VERSION "dbc-export 1 2026.26.6.5"

NS_ :

BS_:

BU_: ADSP APB APP APS APSB BB BMS CC CMP CMPD CP DAS DI DIF DIR DPB EPAS3P EPAS3S EPASTP EPASTS EPBL EPBR ESP EVSE FC GTW HCML HCMR HVP IBST ICR IDB LS OCS1P PARK PCS PCS2 PM PMF PMR PNCD PTC RADC RCM RCM2 RCM3 RCU SCCM SCM SCS SDCR TAS TCU TCU2 TPMS TRCM UI UIS UMC USM V2G VC VCBATT VCBATT0 VCBATT1 VCBATT2 VCCC VCFRONT VCFRONT1 VCFRONT2 VCLEFT VCRIGHT VCSEAT2L VCSEAT2R VCSEC VEH

BO_ 1360 ADSP_alertLog: 8 ADSP
 SG_ ADSP_alertID M : 0|7@1+ (1,0) [0|127] "" Vector__XXX
 SG_ ADSP_alertState : 15|1@1+ (1,0) [0|1] "" Vector__XXX
 SG_ ADSP_a002_core m2 : 16|2@1+ (1,0) [0|3] "" Vector__XXX
 SG_ ADSP_a002_cause m2 : 18|4@1+ (1,0) [0|15] "" Vector__XXX
 SG_ ADSP_a022_error m22 : 16|3@1+ (1,0) [0|7] "" Vector__XXX
 SG_ ADSP_a022_errorCount m22 : 24|32@1+ (1,0) [0|4294967295] "" Vector__XXX
 SG_ ADSP_a035_a2baFaultNode m35 : 16|4@1+ (1,0) [0|15] "" Vector__XXX
 SG_ ADSP_a035_timeout m35 : 20|1@1+ (1,0) [0|1] "" Vector__XXX
 SG_ ADSP_a035_a2baIntrType m35 : 24|8@1+ (1,0) [0|255] "" Vector__XXX
 SG_ ADSP_a035_a2baFaultType m35 : 32|6@1+ (1,0) [0|63] "" Vector__XXX
 SG_ ADSP_a036_a2bbFaultNode m36 : 16|4@1+ (1,0) [0|15] "" Vector__XXX
 SG_ ADSP_a036_timeout m36 : 20|1@1+ (1,0) [0|1] "" Vector__XXX
 SG_ ADSP_a036_a2bbIntrType m36 : 24|8@1+ (1,0) [0|255] "" Vector__XXX
 SG_ ADSP_a036_a2bbFaultType m36 : 32|6@1+ (1,0) [0|63] "" Vector__XXX
 SG_ ADSP_a050_open_load m50 : 16|1@1+ (1,0) [0|1] "" Vector__XXX
 SG_ ADSP_a050_short_vcc m50 : 17|1@1+ (1,0) [0|1] "" Vector__XXX
 SG_ ADSP_a050_short_gnd m50 : 18|1@1+ (1,0) [0|1] "" Vector__XXX
 SG_ ADSP_a050_short_load m50 : 19|1@1+ (1,0) [0|1] "" Vector__XXX
 SG_ ADSP_a050_diag_failed_to_start m50 : 20|1@1+ (1,0) [0|1] "" Vector__XXX
 SG_ ADSP_a050_diag_failed m50 : 21|1@1+ (1,0) [0|1] "" Vector__XXX
 SG_ ADSP_a053_audioSystemUnavailable m53 : 16|3@1+ (1,0) [0|7] "" Vector__XXX
 SG_ ADSP_a066_open_load m66 : 16|1@1+ (1,0) [0|1] "" Vector__XXX
 SG_ ADSP_a066_short_vcc m66 : 17|1@1+ (1,0) [0|1] "" Vector__XXX
 SG_ ADSP_a066_short_gnd m66 : 18|1@1+ (1,0) [0|1] "" Vector__XXX
 SG_ ADSP_a066_short_load m66 : 19|1@1+ (1,0) [0|1] "" Vector__XXX
 SG_ ADSP_a066_diag_failed_to_start m66 : 20|1@1+ (1,0) [0|1] "" Vector__XXX
 SG_ ADSP_a066_diag_failed m66 : 21|1@1+ (1,0) [0|1] "" Vector__XXX
 SG_ ADSP_a067_baseamp0Fault m67 : 16|3@1+ (1,0) [0|7] "" Vector__XXX
 SG_ ADSP_a067_baseamp0Temp m67 : 24|8@1+ (1,0) [0|255] "C" Vector__XXX
 SG_ ADSP_a068_baseamp1Fault m68 : 16|3@1+ (1,0) [0|7] "" Vector__XXX
 SG_ ADSP_a068_baseamp1Temp m68 : 24|8@1+ (1,0) [0|255] "C" Vector__XXX
 SG_ ADSP_a069_baseamp2Fault m69 : 16|3@1+ (1,0) [0|7] "" Vector__XXX
 SG_ ADSP_a069_baseamp2Temp m69 : 24|8@1+ (1,0) [0|255] "C" Vector__XXX
 SG_ ADSP_a070_baseamp3Fault m70 : 16|3@1+ (1,0) [0|7] "" Vector__XXX
 SG_ ADSP_a070_baseamp3Temp m70 : 24|8@1+ (1,0) [0|255] "C" Vector__XXX
 SG_ ADSP_a071_versionMismatch m71 : 16|1@1+ (1,0) [0|1] "" Vector__XXX
 SG_ ADSP_a080_micInitError m80 : 16|2@1+ (1,0) [0|3] "" Vector__XXX

BO_ 1361 ADSP_alertMatrix1: 8 ADSP
 SG_ ADSP_w001_flashInit : 0|1@1+ (1,0) [0|1] "" Vector__XXX
 SG_ ADSP_w002_exception : 1|1@1+ (1,0) [0|1] "" Vector__XXX
 SG_ ADSP_w003_assert : 2|1@1+ (1,0) [0|1] "" Vector__XXX
 SG_ ADSP_w004_malloc : 3|1@1+ (1,0) [0|1] "" Vector__XXX
 SG_ ADSP_w005_stackOverflow : 4|1@1+ (1,0) [0|1] "" Vector__XXX
 SG_ ADSP_w006_eavbSeqno : 5|1@1+ (1,0) [0|1] "" Vector__XXX
 SG_ ADSP_w007_ethLinkErr : 6|1@1+ (1,0) [0|1] "" Vector__XXX
 SG_ ADSP_w008_internalTempHigh : 7|1@1+ (1,0) [0|1] "" Vector__XXX
 SG_ ADSP_w010_12vAudioFiltLow : 9|1@1+ (1,0) [0|1] "" Vector__XXX
 SG_ ADSP_w011_armHighCpuUsage : 10|1@1+ (1,0) [0|1] "" Vector__XXX
 SG_ ADSP_w012_sharc0HighCpuUsage : 11|1@1+ (1,0) [0|1] "" Vector__XXX
 SG_ ADSP_w013_sharc1HighCpuUsage : 12|1@1+ (1,0) [0|1] "" Vector__XXX
 SG_ ADSP_w014_eavbOverrun : 13|1@1+ (1,0) [0|1] "" Vector__XXX
 SG_ ADSP_w015_eavbUnderrun : 14|1@1+ (1,0) [0|1] "" Vector__XXX
 SG_ ADSP_w016_usbRxOverrun : 15|1@1+ (1,0) [0|1] "" Vector__XXX
 SG_ ADSP_w017_usbRxUnderrun : 16|1@1+ (1,0) [0|1] "" Vector__XXX
 SG_ ADSP_w018_usbTxOverrun : 17|1@1+ (1,0) [0|1] "" Vector__XXX
 SG_ ADSP_w019_usbTxUnderrun : 18|1@1+ (1,0) [0|1] "" Vector__XXX
 SG_ ADSP_w020_usbTxFailed : 19|1@1+ (1,0) [0|1] "" Vector__XXX
 SG_ ADSP_w021_usbTxAborted : 20|1@1+ (1,0) [0|1] "" Vector__XXX
 SG_ ADSP_w022_emacErr : 21|1@1+ (1,0) [0|1] "" Vector__XXX
 SG_ ADSP_w023_ethEtharpErr : 22|1@1+ (1,0) [0|1] "" Vector__XXX
 SG_ ADSP_w024_ethIpfragErr : 23|1@1+ (1,0) [0|1] "" Vector__XXX
 SG_ ADSP_w025_ethIpErr : 24|1@1+ (1,0) [0|1] "" Vector__XXX
 SG_ ADSP_w026_ethIcmpErr : 25|1@1+ (1,0) [0|1] "" Vector__XXX
 SG_ ADSP_w027_ethUdpErr : 26|1@1+ (1,0) [0|1] "" Vector__XXX
 SG_ ADSP_w028_ethTcpErr : 27|1@1+ (1,0) [0|1] "" Vector__XXX
 SG_ ADSP_w029_baseamp0SmFault : 28|1@1+ (1,0) [0|1] "" Vector__XXX
 SG_ ADSP_w030_ethSysErr : 29|1@1+ (1,0) [0|1] "" Vector__XXX
 SG_ ADSP_w031_baseamp1SmFault : 30|1@1+ (1,0) [0|1] "" Vector__XXX
 SG_ ADSP_w032_baseamp2SmFault : 31|1@1+ (1,0) [0|1] "" Vector__XXX
 SG_ ADSP_w033_a2baDiscoveryFailed : 32|1@1+ (1,0) [0|1] "" Vector__XXX
 SG_ ADSP_w034_a2bbDiscoveryFailed : 33|1@1+ (1,0) [0|1] "" Vector__XXX
 SG_ ADSP_w035_a2baFault : 34|1@1+ (1,0) [0|1] "" Vector__XXX
 SG_ ADSP_w036_a2bbFault : 35|1@1+ (1,0) [0|1] "" Vector__XXX
 SG_ ADSP_w037_a2baIdleFailed : 36|1@1+ (1,0) [0|1] "" Vector__XXX
 SG_ ADSP_w038_a2bbIdleFailed : 37|1@1+ (1,0) [0|1] "" Vector__XXX
 SG_ ADSP_w039_ancPing : 38|1@1+ (1,0) [0|1] "" Vector__XXX
 SG_ ADSP_w040_socSciHeartbeat : 39|1@1+ (1,0) [0|1] "" Vector__XXX
 SG_ ADSP_w041_twiWriteError : 40|1@1+ (1,0) [0|1] "" Vector__XXX
 SG_ ADSP_w042_twiReadError : 41|1@1+ (1,0) [0|1] "" Vector__XXX
 SG_ ADSP_w043_aweControlError : 42|1@1+ (1,0) [0|1] "" Vector__XXX
 SG_ ADSP_w044_canethChecksum : 43|1@1+ (1,0) [0|1] "" Vector__XXX
 SG_ ADSP_w045_ancEnableFail : 44|1@1+ (1,0) [0|1] "" Vector__XXX
 SG_ ADSP_w046_sharc0AweFrameOverload : 45|1@1+ (1,0) [0|1] "" Vector__XXX
 SG_ ADSP_w047_sharc1AweFrameOverload : 46|1@1+ (1,0) [0|1] "" Vector__XXX
 SG_ ADSP_w048_eCallSelfTestFailed : 47|1@1+ (1,0) [0|1] "" Vector__XXX
 SG_ ADSP_w049_sae : 48|1@1+ (1,0) [0|1] "" Vector__XXX
 SG_ ADSP_w050_extSpkFault : 49|1@1+ (1,0) [0|1] "" Vector__XXX
 SG_ ADSP_w051_extspkFailure : 50|1@1+ (1,0) [0|1] "" Vector__XXX
 SG_ ADSP_w052_criticalReset : 51|1@1+ (1,0) [0|1] "" Vector__XXX
 SG_ ADSP_w053_audioSystemUnavailable : 52|1@1+ (1,0) [0|1] "" Vector__XXX
 SG_ ADSP_w054_canethRxError : 53|1@1+ (1,0) [0|1] "" Vector__XXX
 SG_ ADSP_w055_hfpMathExcept1NAN : 54|1@1+ (1,0) [0|1] "" Vector__XXX
 SG_ ADSP_w056_hfpMathExcept1INF : 55|1@1+ (1,0) [0|1] "" Vector__XXX
 SG_ ADSP_w057_hfpMathExcept2NAN : 56|1@1+ (1,0) [0|1] "" Vector__XXX
 SG_ ADSP_w058_hfpMathExcept2INF : 57|1@1+ (1,0) [0|1] "" Vector__XXX
 SG_ ADSP_w059_nvmmError : 58|1@1+ (1,0) [0|1] "" Vector__XXX
 SG_ ADSP_w060_baseamp3SmFault : 59|1@1+ (1,0) [0|1] "" Vector__XXX
 SG_ ADSP_w061_tcuGpioServiceError : 60|1@1+ (1,0) [0|1] "" Vector__XXX

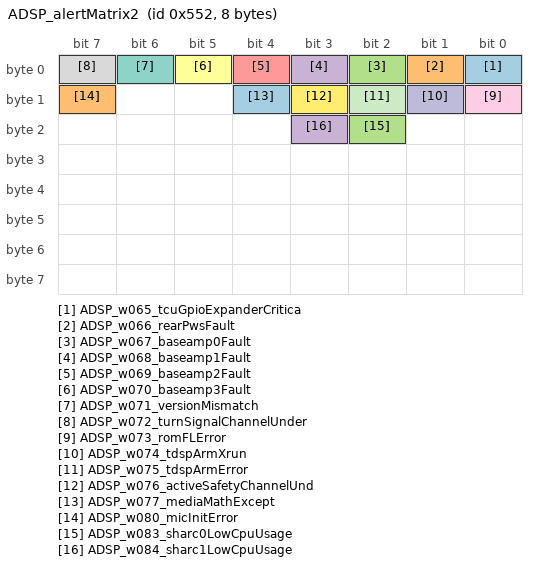
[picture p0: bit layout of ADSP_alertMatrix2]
BO_ 1362 ADSP_alertMatrix2: 8 ADSP
 SG_ ADSP_w065_tcuGpioExpanderCritica : 0|1@1+ (1,0) [0|1] "" Vector__XXX
 SG_ ADSP_w066_rearPwsFault : 1|1@1+ (1,0) [0|1] "" Vector__XXX
 SG_ ADSP_w067_baseamp0Fault : 2|1@1+ (1,0) [0|1] "" Vector__XXX
 SG_ ADSP_w068_baseamp1Fault : 3|1@1+ (1,0) [0|1] "" Vector__XXX
 SG_ ADSP_w069_baseamp2Fault : 4|1@1+ (1,0) [0|1] "" Vector__XXX
 SG_ ADSP_w070_baseamp3Fault : 5|1@1+ (1,0) [0|1] "" Vector__XXX
 SG_ ADSP_w071_versionMismatch : 6|1@1+ (1,0) [0|1] "" Vector__XXX
 SG_ ADSP_w072_turnSignalChannelUnder : 7|1@1+ (1,0) [0|1] "" Vector__XXX
 SG_ ADSP_w073_romFLError : 8|1@1+ (1,0) [0|1] "" Vector__XXX
 SG_ ADSP_w074_tdspArmXrun : 9|1@1+ (1,0) [0|1] "" Vector__XXX
 SG_ ADSP_w075_tdspArmError : 10|1@1+ (1,0) [0|1] "" Vector__XXX
 SG_ ADSP_w076_activeSafetyChannelUnd : 11|1@1+ (1,0) [0|1] "" Vector__XXX
 SG_ ADSP_w077_mediaMathExcept : 12|1@1+ (1,0) [0|1] "" Vector__XXX
 SG_ ADSP_w080_micInitError : 15|1@1+ (1,0) [0|1] "" Vector__XXX
 SG_ ADSP_w083_sharc0LowCpuUsage : 18|1@1+ (1,0) [0|1] "" Vector__XXX
 SG_ ADSP_w084_sharc1LowCpuUsage : 19|1@1+ (1,0) [0|1] "" Vector__XXX

BO_ 1951 ADSP_audioVisualizer: 1 ADSP
 SG_ ADSP_audioVisualizerBrightness : 0|8@1+ (1,0) [0|255] "" Vector__XXX

BO_ 1383 ADSP_state: 8 ADSP
 SG_ ADSP_a2baState : 0|5@1+ (1,0) [0|31] "" Vector__XXX
 SG_ ADSP_a2bbState : 8|5@1+ (1,0) [0|31] "" Vector__XXX
 SG_ ADSP_baseamp0State : 13|3@1+ (1,0) [0|7] "" Vector__XXX
 SG_ ADSP_baseamp1State : 16|3@1+ (1,0) [0|7] "" Vector__XXX
 SG_ ADSP_baseamp2State : 19|3@1+ (1,0) [0|7] "" Vector__XXX
 SG_ ADSP_baseamp3State : 24|3@1+ (1,0) [0|7] "" Vector__XXX
 SG_ ADSP_audioReady : 27|1@1+ (1,0) [0|1] "" Vector__XXX
 SG_ ADSP_extSpkCheckRan : 28|1@1+ (1,0) [0|1] "" Vector__XXX
 SG_ ADSP_tcuI2SEnabled : 29|1@1+ (1,0) [0|1] "" Vector__XXX
 SG_ ADSP_telephonyRxMute : 31|1@1+ (1,0) [0|1] "" Vector__XXX
 SG_ ADSP_ancState : 32|3@1+ (1,0) [0|7] "" Vector__XXX
 SG_ ADSP_sourceSelect : 35|2@1+ (1,0) [0|3] "" Vector__XXX
 SG_ ADSP_tunerSelect : 37|1@1+ (1,0) [0|1] "" Vector__XXX
 SG_ ADSP_ancMode : 38|5@1+ (1,0) [0|31] "" Vector__XXX
 SG_ ADSP_spkMuteAll : 43|1@1+ (1,0) [0|1] "" Vector__XXX
 SG_ ADSP_eCall_ENS_state : 44|3@1+ (1,0) [0|7] "" Vector__XXX
 SG_ ADSP_eCallSelfTest : 47|2@1+ (1,0) [0|3] "" Vector__XXX
 SG_ ADSP_eCallState : 49|1@1+ (1,0) [0|1] "" Vector__XXX
 SG_ ADSP_allAudioReady : 50|1@1+ (1,0) [0|1] "" Vector__XXX
 SG_ ADSP_callState : 51|1@1+ (1,0) [0|1] "" Vector__XXX
 SG_ ADSP_telephonyTxMute : 52|1@1+ (1,0) [0|1] "" Vector__XXX
 SG_ ADSP_eCallMicrophoneStatus : 53|2@1+ (1,0) [0|3] "" Vector__XXX
 SG_ ADSP_eCallSpeakerStatus : 56|2@1+ (1,0) [0|3] "" Vector__XXX
 SG_ ADSP_a2baLoadShedded : 58|1@1+ (1,0) [0|1] "" Vector__XXX
 SG_ ADSP_requestFailoverSpeaker : 59|1@1+ (1,0) [0|1] "" Vector__XXX
 SG_ ADSP_microphoneDataState : 60|1@1+ (1,0) [0|1] "" Vector__XXX

BO_ 600 APB_status: 8 APB
 SG_ APB_watchdogState : 0|3@1+ (1,0) [0|6] "" Vector__XXX
 SG_ APB_fusedState : 3|2@1+ (1,0) [0|2] "" Vector__XXX
 SG_ APB_cameraHeaterRequest : 5|1@1+ (1,0) [0|1] "" Vector__XXX
 SG_ APB_factorySummonStatus : 6|4@1+ (1,0) [1|15] "" Vector__XXX
 SG_ APB_clipRecordingStatus : 10|3@1+ (1,0) [0|7] "" Vector__XXX
 SG_ APB_summonUnavailableReason : 14|5@1+ (1,0) [0|31] "" Vector__XXX
 SG_ APB_fsdSuspendState : 19|2@1+ (1,0) [0|2] "" Vector__XXX
 SG_ APB_fsdRevokeStrikeoutCount : 21|3@1+ (1,0) [0|6] "" Vector__XXX
 SG_ APB_teslaVisionSupported : 24|2@1+ (1,0) [0|2] "" Vector__XXX
 SG_ APB_teslaVisionUnsupportedReason : 26|3@1+ (1,0) [0|7] "" Vector__XXX
 SG_ APB_fsdRevokeCount : 29|3@1+ (1,0) [0|6] "" Vector__XXX
 SG_ APB_excessiveAccelPedalWarning : 32|1@1+ (1,0) [0|1] "" Vector__XXX
 SG_ APB_unifiedObjectStackSupported : 33|2@1+ (1,0) [0|2] "" Vector__XXX
 SG_ APB_sendingBUCStream : 35|1@1+ (1,0) [0|1] "" Vector__XXX
 SG_ APB_DDAWSystemStatus : 37|3@1+ (1,0) [0|7] "" Vector__XXX
 SG_ APB_socOperatingMode : 40|2@1+ (1,0) [0|3] "" Vector__XXX
 SG_ APB_summonVersionIdentifier : 42|2@1+ (1,0) [0|3] "" Vector__XXX
 SG_ APB_sentryState : 44|3@1+ (1,0) [0|7] "" Vector__XXX
 SG_ APB_autoparkVersionIdentifier : 47|2@1+ (1,0) [0|3] "" Vector__XXX
 SG_ APB_autonomySystemHealth : 49|1@1+ (1,0) [0|1] "" Vector__XXX
 SG_ APB_suspendResumeAvailable : 51|1@1+ (1,0) [0|1] "" Vector__XXX
 SG_ APB_statusCounter : 52|4@1+ (1,0) [0|15] "" Vector__XXX
 SG_ APB_statusChecksum : 56|8@1+ (1,0) [0|255] "" Vector__XXX

BO_ 909 APP_VC_infoMessage: 8 APP
 SG_ APP_inTunnel : 0|2@1+ (1,0) [1|3] "" Vector__XXX
 SG_ APP_windshieldHeaterOnReason : 2|4@1+ (1,0) [1|15] "" Vector__XXX
 SG_ APP_selfieCameraBlocked : 6|2@1+ (1,0) [1|3] "" Vector__XXX
 SG_ APP_selfieCameraLUX : 8|8@1+ (1,0) [0|253] "lux" Vector__XXX
 SG_ APP_sceneTagClearlyRaining : 16|2@1+ (1,0) [1|3] "" Vector__XXX
 SG_ APP_sceneTagFog : 18|2@1+ (1,0) [1|3] "" Vector__XXX
 SG_ APP_sceneTagFullyBlocked : 20|2@1+ (1,0) [1|3] "" Vector__XXX
 SG_ APP_sceneTagIndoors : 22|2@1+ (1,0) [1|3] "" Vector__XXX
 SG_ APP_sceneTagLensFlare : 24|2@1+ (1,0) [1|3] "" Vector__XXX
 SG_ APP_sceneTagRaining : 26|2@1+ (1,0) [1|3] "" Vector__XXX
 SG_ APP_sceneTagSevereWeather : 28|2@1+ (1,0) [1|3] "" Vector__XXX
 SG_ APP_sceneTagSnowing : 30|2@1+ (1,0) [1|3] "" Vector__XXX
 SG_ APP_sceneTagSnowyRoad : 32|2@1+ (1,0) [1|3] "" Vector__XXX
 SG_ APP_sceneTagSunGlare : 34|2@1+ (1,0) [1|3] "" Vector__XXX
 SG_ APP_sceneTagTunnel : 36|2@1+ (1,0) [1|3] "" Vector__XXX
 SG_ APP_sceneTagWetRoad : 38|2@1+ (1,0) [1|3] "" Vector__XXX
 SG_ APP_fisheyeInPathVisibility : 40|3@1+ (1,0) [1|7] "" Vector__XXX
 SG_ APP_fisheyeOverallVisibility : 43|3@1+ (1,0) [1|7] "" Vector__XXX
 SG_ APP_mainInPathVisibility : 46|3@1+ (1,0) [1|7] "" Vector__XXX
 SG_ APP_mainOverallVisibility : 49|3@1+ (1,0) [1|7] "" Vector__XXX
 SG_ APP_narrowInPathVisibility : 52|3@1+ (1,0) [1|7] "" Vector__XXX
 SG_ APP_narrowOverallVisibility : 55|3@1+ (1,0) [1|7] "" Vector__XXX
 SG_ APP_frontCamOcclusionType : 58|3@1+ (1,0) [0|7] "" Vector__XXX

BO_ 1513 APP_alertLog: 8 APP
 SG_ APP_alertID M : 0|14@1+ (1,0) [0|16383] "" Vector__XXX
 SG_ APP_alertSource : 14|1@1+ (1,0) [0|1] "" Vector__XXX
 SG_ APP_alertState : 15|1@1+ (1,0) [0|1] "" Vector__XXX
 SG_ APP_sw004_radIssue m4 : 16|1@1+ (1,0) [0|1] "" Vector__XXX
 SG_ APP_sw004_radHWFailure m4 : 17|1@1+ (1,0) [0|1] "" Vector__XXX
 SG_ APP_sw004_radSensorBlind m4 : 18|1@1+ (1,0) [0|1] "" Vector__XXX
 SG_ APP_sw004_radSGUFailure m4 : 19|1@1+ (1,0) [0|1] "" Vector__XXX
 SG_ APP_sw004_radMia m4 : 20|1@1+ (1,0) [0|1] "" Vector__XXX
 SG_ APP_sw004_radDynamicsError m4 : 21|1@1+ (1,0) [0|1] "" Vector__XXX
 SG_ APP_sw004_espMIA m4 : 22|1@1+ (1,0) [0|1] "" Vector__XXX
 SG_ APP_sw004_accState m4 : 24|4@1+ (1,0) [0|15] "" Vector__XXX
 SG_ APP_sw004_appMobileyeStatus m4 : 28|5@1+ (1,0) [0|31] "" Vector__XXX
 SG_ APP_sw004_diCruiseStateFault m4 : 33|1@1+ (1,0) [0|1] "" Vector__XXX
 SG_ APP_sw004_diMIA m4 : 34|1@1+ (1,0) [0|1] "" Vector__XXX
 SG_ APP_sw004_accelPedalInvalid m4 : 35|1@1+ (1,0) [0|1] "" Vector__XXX
 SG_ APP_sw004_stwAngleInvalid m4 : 36|1@1+ (1,0) [0|1] "" Vector__XXX
 SG_ APP_sw004_accelerationInvalid m4 : 37|1@1+ (1,0) [0|1] "" Vector__XXX
 SG_ APP_sw004_diSpeedInvalid m4 : 38|1@1+ (1,0) [0|1] "" Vector__XXX
 SG_ APP_sw004_DASFeaturesDisabled m4 : 39|1@1+ (1,0) [0|1] "" Vector__XXX
 SG_ APP_sw004_appMobileyeNotInVision m4 : 40|1@1+ (1,0) [0|1] "" Vector__XXX
 SG_ APP_sw004_CamCommonMIA m4 : 41|1@1+ (1,0) [0|1] "" Vector__XXX
 SG_ APP_sw004_CamObjectsMIA m4 : 42|1@1+ (1,0) [0|1] "" Vector__XXX
 SG_ APP_sw004_CamWatchdog m4 : 43|1@1+ (1,0) [0|1] "" Vector__XXX
 SG_ APP_sw004_RadarLowVisibility m4 : 44|1@1+ (1,0) [0|1] "" Vector__XXX
 SG_ APP_sw004_RadarMisalignment m4 : 45|1@1+ (1,0) [0|1] "" Vector__XXX
 SG_ APP_sw004_OutOfFocusImage m4 : 46|1@1+ (1,0) [0|1] "" Vector__XXX
 SG_ APP_sw004_ImpairedVD m4 : 47|1@1+ (1,0) [0|1] "" Vector__XXX
 SG_ APP_sw004_SunRay m4 : 48|1@1+ (1,0) [0|1] "" Vector__XXX
 SG_ APP_sw004_Splashes m4 : 49|1@1+ (1,0) [0|1] "" Vector__XXX
 SG_ APP_sw004_BlurredImage m4 : 50|1@1+ (1,0) [0|1] "" Vector__XXX
 SG_ APP_sw004_LowSun m4 : 51|1@1+ (1,0) [0|1] "" Vector__XXX
 SG_ APP_sw004_SmearedSpots m4 : 52|1@1+ (1,0) [0|1] "" Vector__XXX
 SG_ APP_sw004_PartialBlockage m4 : 53|1@1+ (1,0) [0|1] "" Vector__XXX
 SG_ APP_sw004_AutofixOutOfCalib m4 : 54|1@1+ (1,0) [0|1] "" Vector__XXX
 SG_ APP_sw004_AutofixOutOfCalibHorzn m4 : 55|1@1+ (1,0) [0|1] "" Vector__XXX
 SG_ APP_sw004_AutofixOutOfCalibYaw m4 : 56|1@1+ (1,0) [0|1] "" Vector__XXX
 SG_ APP_sw004_FullBlockage m4 : 57|1@1+ (1,0) [0|1] "" Vector__XXX
 SG_ APP_sw004_SmearedHalos m4 : 58|1@1+ (1,0) [0|1] "" Vector__XXX
 SG_ APP_sw004_FoggyLights m4 : 59|1@1+ (1,0) [0|1] "" Vector__XXX
 SG_ APP_sw004_SelfGlare m4 : 60|1@1+ (1,0) [0|1] "" Vector__XXX
 SG_ APP_sw004_visionNotRunning m4 : 61|1@1+ (1,0) [0|1] "" Vector__XXX
 SG_ APP_sw009_DIaebState_fault m9 : 16|1@1+ (1,0) [0|1] "" Vector__XXX
 SG_ APP_sw009_DI_aeb_unresponsive m9 : 17|1@1+ (1,0) [0|1] "" Vector__XXX
 SG_ APP_sw009_DI_MIA m9 : 18|1@1+ (1,0) [0|1] "" Vector__XXX
 SG_ APP_sw009_SCCM_MIA m9 : 19|1@1+ (1,0) [0|1] "" Vector__XXX
 SG_ APP_sw009_CameraStream_fault m9 : 20|1@1+ (1,0) [0|1] "" Vector__XXX
 SG_ APP_sw010_a04calibNotDone m10 : 16|1@1+ (1,0) [0|1] "" Vector__XXX
 SG_ APP_sw010_a05calibReqd m10 : 17|1@1+ (1,0) [0|1] "" Vector__XXX
 SG_ APP_sw010_a06calibNotOK m10 : 18|1@1+ (1,0) [0|1] "" Vector__XXX
 SG_ APP_sw010_a08PlantMode m10 : 19|1@1+ (1,0) [0|1] "" Vector__XXX
 SG_ APP_sw010_HorizontalMisalignment m10 : 20|16@1+ (0.00137332,-45) [-45|45.0005262] "deg" Vector__XXX
 SG_ APP_sw010_VerticalMisalignment m10 : 36|10@1+ (0.087977,-45) [-45|45.000471] "deg" Vector__XXX
 SG_ APP_sw010_unusedBits m10 : 46|2@1+ (1,0) [0|3] "" Vector__XXX
 SG_ APP_sw010_VmaPlausibility m10 : 48|16@1+ (1.52587890625e-05,0) [0|0.999984741211] "FIXME" Vector__XXX
 SG_ APP_sw011_scaState m11 : 16|3@1+ (1,0) [0|7] "" Vector__XXX
 SG_ APP_sw011_scaLeft m11 : 19|1@1+ (1,0) [0|1] "" Vector__XXX
 SG_ APP_sw011_scaRight m11 : 20|1@1+ (1,0) [0|1] "" Vector__XXX
 SG_ APP_sw011_scaBlinker m11 : 21|2@1+ (1,0) [0|3] "" Vector__XXX
 SG_ APP_sw011_scaThreshold m11 : 23|1@1+ (1,0) [0|1] "" Vector__XXX
 SG_ APP_sw011_scaSpeed m11 : 24|7@1+ (1,0) [0|127] "MPH" Vector__XXX
 SG_ APP_sw011_scaSonicDist m11 : 32|5@1+ (0.05,0) [0|1.55] "m" Vector__XXX
 SG_ APP_sw011_scaSteerAngle m11 : 37|10@1+ (0.1,-51.2) [-51.2|51.1] "deg" Vector__XXX
 SG_ APP_sw011_egoRightOfCenter m11 : 47|1@1+ (1,0) [0|1] "" Vector__XXX
 SG_ APP_sw011_egoMovingRight m11 : 48|1@1+ (1,0) [0|1] "" Vector__XXX
 SG_ APP_sw011_egoLeftOfCenter m11 : 49|1@1+ (1,0) [0|1] "" Vector__XXX
 SG_ APP_sw011_egoMovingLeft m11 : 50|1@1+ (1,0) [0|1] "" Vector__XXX
 SG_ APP_sw011_polyValid m11 : 51|1@1+ (1,0) [0|1] "" Vector__XXX
 SG_ APP_sw011_egoCentered m11 : 52|1@1+ (1,0) [0|1] "" Vector__XXX
 SG_ APP_sw011_scaReasonEldw m11 : 53|1@1+ (1,0) [0|1] "" Vector__XXX
 SG_ APP_sw011_laneWidth m11 : 56|8@1+ (0.025,0) [0|6.375] "m" Vector__XXX
 SG_ APP_sw025_state_before_override m25 : 16|4@1+ (1,0) [0|15] "" Vector__XXX
 SG_ APP_sw025_road_class m25 : 20|3@1+ (1,0) [0|7] "" Vector__XXX
 SG_ APP_sw025_road_match m25 : 23|1@1+ (1,0) [0|1] "" Vector__XXX
 SG_ APP_sw025_controlled_access m25 : 24|1@1+ (1,0) [0|1] "" Vector__XXX
 SG_ APP_sw025_leftLaneUsage m25 : 25|2@1+ (1,0) [0|3] "" Vector__XXX
 SG_ APP_sw025_rightLaneUsage m25 : 27|2@1+ (1,0) [0|3] "" Vector__XXX
 SG_ APP_sw025_vehiclesUsage m25 : 29|2@1+ (1,0) [0|3] "" Vector__XXX
 SG_ APP_sw025_hppUsage m25 : 32|2@1+ (1,0) [0|3] "" Vector__XXX
 SG_ APP_sw025_navigationUsage m25 : 34|2@1+ (1,0) [0|3] "" Vector__XXX
 SG_ APP_sw025_modelUsage m25 : 36|2@1+ (1,0) [0|3] "" Vector__XXX
 SG_ APP_sw025_bottsDotsUsage m25 : 38|2@1+ (1,0) [0|3] "" Vector__XXX
 SG_ APP_sw025_offsetSide m25 : 40|2@1+ (1,0) [0|3] "" Vector__XXX
 SG_ APP_sw025_torsionBarTorque m25 : 48|8@1+ (0.1,-12.8) [-12.8|12.7] "Nm" Vector__XXX
 SG_ APP_sw033_carConfig m33 : 16|1@1+ (1,0) [0|1] "" Vector__XXX
 SG_ APP_sw033_chNm m33 : 17|1@1+ (1,0) [0|1] "" Vector__XXX
 SG_ APP_sw033_gearControlVehBus m33 : 18|1@1+ (1,0) [0|1] "" Vector__XXX
 SG_ APP_sw034_sccmMia m34 : 16|8@1+ (1,0) [0|255] "" Vector__XXX
 SG_ APP_sw034_unusedByte m34 : 24|8@1+ (1,0) [0|255] "" Vector__XXX
 SG_ APP_sw034_unusedW0 m34 : 32|16@1+ (1,0) [0|65535] "" Vector__XXX
 SG_ APP_sw034_unusedW1 m34 : 48|16@1+ (1,0) [0|65535] "" Vector__XXX
 SG_ APP_sw035_status m35 : 16|1@1+ (1,0) [0|1] "" Vector__XXX
 SG_ APP_sw035_wheelRotation m35 : 17|1@1+ (1,0) [0|1] "" Vector__XXX
 SG_ APP_sw035_wheelSpeeds m35 : 18|1@1+ (1,0) [0|1] "" Vector__XXX
 SG_ APP_sw035_redundantBrakingStatus m35 : 19|1@1+ (1,0) [0|1] "" Vector__XXX
 SG_ APP_sw040_accel_pedal_pos m40 : 16|8@1+ (0.5,0) [0|127.5] "%" Vector__XXX
 SG_ APP_sw040_ego_veh_speed m40 : 24|8@1+ (0.2,0) [0|51] "m/s" Vector__XXX
 SG_ APP_sw040_das_steering_req m40 : 32|8@1+ (1,-128) [-128|127] "deg" Vector__XXX
 SG_ APP_sw040_epas_internal_sas m40 : 40|8@1+ (1,-128) [-128|127] "deg" Vector__XXX
 SG_ APP_sw040_torsion_bar_torque m40 : 48|8@1+ (0.1,-12.8) [-12.8|12.7] "Nm" Vector__XXX
 SG_ APP_sw040_view_range m40 : 56|8@1+ (1,0) [0|255] "m" Vector__XXX
 SG_ APP_sw041_rate m41 : 16|10@1- (1,0) [-512|511] "deg/s" Vector__XXX
 SG_ APP_sw041_max_rate m41 : 26|10@1- (1,0) [-512|511] "deg/s" Vector__XXX
 SG_ APP_sw041_ego_speed m41 : 36|10@1+ (0.05,0) [0|51.15] "m/s" Vector__XXX
 SG_ APP_sw041_unusedW2 m41 : 46|18@1+ (1,0) [0|262143] "" Vector__XXX
 SG_ APP_sw042_health_state m42 : 16|3@1+ (1,0) [0|6] "" Vector__XXX
 SG_ APP_sw042_abort_reason m42 : 19|5@1+ (1,0) [0|31] "" Vector__XXX
 SG_ APP_sw042_view_range m42 : 24|8@1+ (1,0) [0|255] "" Vector__XXX
 SG_ APP_sw042_state_before_abort m42 : 32|4@1+ (1,0) [0|15] "" Vector__XXX
 SG_ APP_sw042_epas_error_code m42 : 36|4@1+ (1,0) [0|15] "" Vector__XXX
 SG_ APP_sw042_cam_SunRay m42 : 40|1@1+ (1,0) [0|1] "" Vector__XXX
 SG_ APP_sw042_cam_RoadSpray m42 : 41|1@1+ (1,0) [0|1] "" Vector__XXX
 SG_ APP_sw042_cam_BlurredImage m42 : 42|1@1+ (1,0) [0|1] "" Vector__XXX
 SG_ APP_sw042_cam_LowSun m42 : 43|1@1+ (1,0) [0|1] "" Vector__XXX
 SG_ APP_sw042_cam_SmearedSpots m42 : 44|1@1+ (1,0) [0|1] "" Vector__XXX
 SG_ APP_sw042_cam_PartialBlock m42 : 45|1@1+ (1,0) [0|1] "" Vector__XXX
 SG_ APP_sw042_cam_Autofix m42 : 46|1@1+ (1,0) [0|1] "" Vector__XXX
 SG_ APP_sw042_cam_AutofixHorizon m42 : 47|1@1+ (1,0) [0|1] "" Vector__XXX
 SG_ APP_sw042_cam_AutofixYaw m42 : 48|1@1+ (1,0) [0|1] "" Vector__XXX
 SG_ APP_sw042_cam_FullBlock m42 : 49|1@1+ (1,0) [0|1] "" Vector__XXX
 SG_ APP_sw042_cam_SmearedHalos m42 : 50|1@1+ (1,0) [0|1] "" Vector__XXX
 SG_ APP_sw042_cam_FoggySpots m42 : 51|1@1+ (1,0) [0|1] "" Vector__XXX
 SG_ APP_sw042_cam_SelfGlare m42 : 52|1@1+ (1,0) [0|1] "" Vector__XXX
 SG_ APP_sw042_cam_OutofFocus m42 : 53|1@1+ (1,0) [0|1] "" Vector__XXX
 SG_ APP_sw042_road_match m42 : 54|1@1+ (1,0) [0|1] "" Vector__XXX
 SG_ APP_sw042_controlled_access m42 : 55|1@1+ (1,0) [0|1] "" Vector__XXX
 SG_ APP_sw042_road_class m42 : 56|3@1+ (1,0) [0|7] "" Vector__XXX
 SG_ APP_sw045_radcAlertMatrix m45 : 16|1@1+ (1,0) [0|1] "" Vector__XXX
 SG_ APP_sw045_radcInfo m45 : 17|1@1+ (1,0) [0|1] "" Vector__XXX
 SG_ APP_sw045_radcAccTargObj1A m45 : 18|1@1+ (1,0) [0|1] "" Vector__XXX
 SG_ APP_sw045_lrrAlertMatrix0 m45 : 19|1@1+ (1,0) [0|1] "" Vector__XXX
 SG_ APP_sw045_lrrPacketEnder m45 : 20|1@1+ (1,0) [0|1] "" Vector__XXX
 SG_ APP_sw045_lrrRadarStatus m45 : 21|1@1+ (1,0) [0|1] "" Vector__XXX
 SG_ APP_sw045_lrrObj00A m45 : 22|1@1+ (1,0) [0|1] "" Vector__XXX
 SG_ APP_sw048_swAssert m48 : 16|1@1+ (1,0) [0|1] "" Vector__XXX
 SG_ APP_sw048_thermalIssue m48 : 17|1@1+ (1,0) [0|1] "" Vector__XXX
 SG_ APP_sw048_powerIssue m48 : 18|1@1+ (1,0) [0|1] "" Vector__XXX
 SG_ APP_sw048_stackOverflow m48 : 19|1@1+ (1,0) [0|1] "" Vector__XXX
 SG_ APP_sw048_checkStop m48 : 20|1@1+ (1,0) [0|1] "" Vector__XXX
 SG_ APP_sw048_ecuWatchdog m48 : 21|1@1+ (1,0) [0|1] "" Vector__XXX
 SG_ APP_sw048_ecuReset m48 : 22|1@1+ (1,0) [0|1] "" Vector__XXX
 SG_ APP_sw048_radcVersionMismatch m48 : 23|1@1+ (1,0) [0|1] "" Vector__XXX
 SG_ APP_sw048_radcCalibration m48 : 24|1@1+ (1,0) [0|1] "" Vector__XXX
 SG_ APP_sw048_radcMia m48 : 25|1@1+ (1,0) [0|1] "" Vector__XXX
 SG_ APP_sw048_eyeQVersionMismatch m48 : 26|1@1+ (1,0) [0|1] "" Vector__XXX
 SG_ APP_sw048_camIssue m48 : 27|1@1+ (1,0) [0|1] "" Vector__XXX
 SG_ APP_sw048_parkerIssue m48 : 28|1@1+ (1,0) [0|1] "" Vector__XXX
 SG_ APP_sw048_prolongedUiMia m48 : 29|1@1+ (1,0) [0|1] "" Vector__XXX
 SG_ APP_sw048_apImuNoise m48 : 30|1@1+ (1,0) [0|1] "" Vector__XXX
 SG_ APP_sw048_uiMiaAtBootup m48 : 31|1@1+ (1,0) [0|1] "" Vector__XXX
 SG_ APP_sw048_fisheyeNarrowSwap m48 : 32|1@1+ (1,0) [0|1] "" Vector__XXX
 SG_ APP_sw048_pillarSwap m48 : 33|1@1+ (1,0) [0|1] "" Vector__XXX
 SG_ APP_sw048_severeResidueDetected m48 : 34|1@1+ (1,0) [0|1] "" Vector__XXX
 SG_ APP_sw050_targetDist m50 : 16|9@1+ (0.2,0) [0|102.2] "m" Vector__XXX
 SG_ APP_sw050_targetRelSpeed m50 : 25|9@1+ (0.0625,-31) [-31|0.9375] "m/s" Vector__XXX
 SG_ APP_sw050_targetOverlap m50 : 34|6@1+ (0.1,0) [0|6.3] "m" Vector__XXX
 SG_ APP_sw050_hostSpeed m50 : 40|8@1+ (1,0) [0|255] "kph" Vector__XXX
 SG_ APP_sw050_hostLongAccel m50 : 48|7@1+ (0.15625,-10) [-10|9.84375] "m/s^2" Vector__XXX
 SG_ APP_sw050_driverPressedAccelPed m50 : 55|1@1+ (1,0) [0|1] "" Vector__XXX
 SG_ APP_sw050_driverPressedBrakePed m50 : 56|1@1+ (1,0) [0|1] "" Vector__XXX
 SG_ APP_sw050_overrideAccelPed m50 : 57|1@1+ (1,0) [0|1] "" Vector__XXX
 SG_ APP_sw050_overrideBlinker m50 : 58|1@1+ (1,0) [0|1] "" Vector__XXX
 SG_ APP_sw050_overrideBrake m50 : 59|1@1+ (1,0) [0|1] "" Vector__XXX
 SG_ APP_sw050_overrideSteer m50 : 60|1@1+ (1,0) [0|1] "" Vector__XXX
 SG_ APP_sw050_fcmModeAtEvent m50 : 61|2@1+ (1,0) [0|3] "" Vector__XXX
 SG_ APP_sw050_accActive m50 : 63|1@1+ (1,0) [0|1] "" Vector__XXX
 SG_ APP_sw051_a01ecuInternalPerf m51 : 16|1@1+ (1,0) [0|1] "" Vector__XXX
 SG_ APP_sw051_a02flashPerformance m51 : 17|1@1+ (1,0) [0|1] "" Vector__XXX
 SG_ APP_sw051_a03vBatHigh m51 : 18|1@1+ (1,0) [0|1] "" Vector__XXX
 SG_ APP_sw051_a09configMismatch m51 : 19|1@1+ (1,0) [0|1] "" Vector__XXX
 SG_ APP_sw051_a52radomeHtrInop m51 : 20|1@1+ (1,0) [0|1] "" Vector__XXX
 SG_ APP_sw051_unused m51 : 21|3@1+ (1,0) [0|7] "" Vector__XXX
 SG_ APP_sw051_SCUTemperature m51 : 24|8@1- (1,0) [-128|127] "" Vector__XXX
 SG_ APP_sw051_HWFail m51 : 32|1@1+ (1,0) [0|1] "" Vector__XXX
 SG_ APP_sw051_SGUFail m51 : 33|1@1+ (1,0) [0|1] "" Vector__XXX
 SG_ APP_sw051_unusedBits m51 : 34|6@1+ (1,0) [0|63] "" Vector__XXX
 SG_ APP_sw051_unusedB0 m51 : 40|8@1+ (1,0) [0|255] "" Vector__XXX
 SG_ APP_sw051_unusedW1 m51 : 48|16@1+ (1,0) [0|65535] "" Vector__XXX
 SG_ APP_sw052_a07sensorBlinded m52 : 16|1@1+ (1,0) [0|1] "" Vector__XXX
 SG_ APP_sw052_sensorDirty m52 : 17|1@1+ (1,0) [0|1] "" Vector__XXX
 SG_ APP_sw052_HWFail m52 : 18|1@1+ (1,0) [0|1] "" Vector__XXX
 SG_ APP_sw052_overTemperature m52 : 19|1@1+ (1,0) [0|1] "" Vector__XXX
 SG_ APP_sw052_underTemperature m52 : 20|1@1+ (1,0) [0|1] "" Vector__XXX
 SG_ APP_sw052_chirpError m52 : 21|1@1+ (1,0) [0|1] "" Vector__XXX
 SG_ APP_sw052_rspError m52 : 22|1@1+ (1,0) [0|1] "" Vector__XXX
 SG_ APP_sw052_sensorBlocked m52 : 23|1@1+ (1,0) [0|1] "" Vector__XXX
 SG_ APP_sw053_a10canBusOff m53 : 16|1@1+ (1,0) [0|1] "" Vector__XXX
 SG_ APP_sw053_a11bdyMIA m53 : 17|1@1+ (1,0) [0|1] "" Vector__XXX
 SG_ APP_sw053_a12espMIA m53 : 18|1@1+ (1,0) [0|1] "" Vector__XXX
 SG_ APP_sw053_a13gtwMIA m53 : 19|1@1+ (1,0) [0|1] "" Vector__XXX
 SG_ APP_sw053_a14sccmMIA m53 : 20|1@1+ (1,0) [0|1] "" Vector__XXX
 SG_ APP_sw053_a15adasMIA m53 : 21|1@1+ (1,0) [0|1] "" Vector__XXX
 SG_ APP_sw053_a16bdyInvalidCount m53 : 22|1@1+ (1,0) [0|1] "" Vector__XXX
 SG_ APP_sw053_a17adasInvalidCount m53 : 23|1@1+ (1,0) [0|1] "" Vector__XXX
 SG_ APP_sw053_a18espInvalidCount m53 : 24|1@1+ (1,0) [0|1] "" Vector__XXX
 SG_ APP_sw053_a19sccmInvalidCount m53 : 25|1@1+ (1,0) [0|1] "" Vector__XXX
 SG_ APP_sw053_a20bdyInvalidChkSm m53 : 26|1@1+ (1,0) [0|1] "" Vector__XXX
 SG_ APP_sw053_a21espInvalidChkSm m53 : 27|1@1+ (1,0) [0|1] "" Vector__XXX
 SG_ APP_sw053_a22sccmInvalidChkSm m53 : 28|1@1+ (1,0) [0|1] "" Vector__XXX
 SG_ APP_sw053_a23sccmInvalidChkSm m53 : 29|1@1+ (1,0) [0|1] "" Vector__XXX
 SG_ APP_sw053_a24absValidity m53 : 30|1@1+ (1,0) [0|1] "" Vector__XXX
 SG_ APP_sw053_a25ambTValidity m53 : 31|1@1+ (1,0) [0|1] "" Vector__XXX
 SG_ APP_sw053_a26brakeValidity m53 : 32|1@1+ (1,0) [0|1] "" Vector__XXX
 SG_ APP_sw053_a27CntryCdValidity m53 : 33|1@1+ (1,0) [0|1] "" Vector__XXX
 SG_ APP_sw053_a28espValidity m53 : 34|1@1+ (1,0) [0|1] "" Vector__XXX
 SG_ APP_sw053_a29longAccOffValidity m53 : 35|1@1+ (1,0) [0|1] "" Vector__XXX
 SG_ APP_sw053_a30longAccValidity m53 : 36|1@1+ (1,0) [0|1] "" Vector__XXX
 SG_ APP_sw053_a31odoValidity m53 : 37|1@1+ (1,0) [0|1] "" Vector__XXX
 SG_ APP_sw053_a32gearValidity m53 : 38|1@1+ (1,0) [0|1] "" Vector__XXX
 SG_ APP_sw053_a33steerAngValidity m53 : 39|1@1+ (1,0) [0|1] "" Vector__XXX
 SG_ APP_sw053_a34steerAngSpdValidity m53 : 40|1@1+ (1,0) [0|1] "" Vector__XXX
 SG_ APP_sw053_a35indctrValidity m53 : 41|1@1+ (1,0) [0|1] "" Vector__XXX
 SG_ APP_sw053_a36vehStndStllValidty m53 : 42|1@1+ (1,0) [0|1] "" Vector__XXX
 SG_ APP_sw053_a37vinValidity m53 : 43|1@1+ (1,0) [0|1] "" Vector__XXX
 SG_ APP_sw053_a38whlRotValidity m53 : 44|1@1+ (1,0) [0|1] "" Vector__XXX
 SG_ APP_sw053_a39whlSpdValidity m53 : 45|1@1+ (1,0) [0|1] "" Vector__XXX
 SG_ APP_sw053_a40whlStndStllValidty m53 : 46|1@1+ (1,0) [0|1] "" Vector__XXX
 SG_ APP_sw053_a41wiperValidity m53 : 47|1@1+ (1,0) [0|1] "" Vector__XXX
 SG_ APP_sw053_a42xwdValidity m53 : 48|1@1+ (1,0) [0|1] "" Vector__XXX
 SG_ APP_sw053_a43yawOffValidity m53 : 49|1@1+ (1,0) [0|1] "" Vector__XXX
 SG_ APP_sw053_a44yawValidity m53 : 50|1@1+ (1,0) [0|1] "" Vector__XXX
 SG_ APP_sw053_a48steerAngOffSanity m53 : 51|1@1+ (1,0) [0|1] "" Vector__XXX
 SG_ APP_sw053_a49tireSizeSanity m53 : 52|1@1+ (1,0) [0|1] "" Vector__XXX
 SG_ APP_sw053_a50velocitySanity m53 : 53|1@1+ (1,0) [0|1] "" Vector__XXX
 SG_ APP_sw053_a51yawSanity m53 : 54|1@1+ (1,0) [0|1] "" Vector__XXX
 SG_ APP_sw053_a53espmodValidity m53 : 55|1@1+ (1,0) [0|1] "" Vector__XXX
 SG_ APP_sw053_a54gtwmodValidity m53 : 56|1@1+ (1,0) [0|1] "" Vector__XXX
 SG_ APP_sw053_a55stwmodValidity m53 : 57|1@1+ (1,0) [0|1] "" Vector__XXX
 SG_ APP_sw053_a56bcmodValidity m53 : 58|1@1+ (1,0) [0|1] "" Vector__XXX
 SG_ APP_sw053_a57dimodValidity m53 : 59|1@1+ (1,0) [0|1] "" Vector__XXX
 SG_ APP_sw053_a59drmiInvalidChkSm m53 : 60|1@1+ (1,0) [0|1] "" Vector__XXX
 SG_ APP_sw053_a60drmiInvalidCount m53 : 61|1@1+ (1,0) [0|1] "" Vector__XXX
 SG_ APP_sw053_a61radPositionMismatch m53 : 62|1@1+ (1,0) [0|1] "" Vector__XXX
 SG_ APP_sw053_a62strRackMismatch m53 : 63|1@1+ (1,0) [0|1] "" Vector__XXX
 SG_ APP_sw055_detectedRadcVersion m55 : 16|32@1+ (1,0) [0|4294967295] "" Vector__XXX
 SG_ APP_sw055_expectedCrcLsw m55 : 48|16@1+ (1,0) [0|65535] "" Vector__XXX
 SG_ APP_sw056_diMia m56 : 16|8@1+ (1,0) [0|255] "" Vector__XXX
 SG_ APP_sw056_unusedByte m56 : 24|8@1+ (1,0) [0|255] "" Vector__XXX
 SG_ APP_sw056_unusedW0 m56 : 32|16@1+ (1,0) [0|65535] "" Vector__XXX
 SG_ APP_sw056_unusedW1 m56 : 48|16@1+ (1,0) [0|65535] "" Vector__XXX
 SG_ APP_sw058_epbMia m58 : 16|8@1+ (1,0) [0|255] "" Vector__XXX
 SG_ APP_sw058_unusedByte m58 : 24|8@1+ (1,0) [0|255] "" Vector__XXX
 SG_ APP_sw058_unusedW0 m58 : 32|16@1+ (1,0) [0|65535] "" Vector__XXX
 SG_ APP_sw058_unusedW1 m58 : 48|16@1+ (1,0) [0|65535] "" Vector__XXX
 SG_ APP_sw059_oloDict m59 : 16|1@1+ (1,0) [0|1] "" Vector__XXX
 SG_ APP_sw059_oocStatus m59 : 17|1@1+ (1,0) [0|1] "" Vector__XXX
 SG_ APP_sw059_pasFrontMiddle m59 : 18|1@1+ (1,0) [0|1] "" Vector__XXX
 SG_ APP_sw059_pasRearMiddle m59 : 19|1@1+ (1,0) [0|1] "" Vector__XXX
 SG_ APP_sw059_pscStatus m59 : 20|1@1+ (1,0) [0|1] "" Vector__XXX
 SG_ APP_sw059_pscVehSlot m59 : 21|1@1+ (1,0) [0|1] "" Vector__XXX
 SG_ APP_sw059_sdiFront m59 : 22|1@1+ (1,0) [0|1] "" Vector__XXX
 SG_ APP_sw059_sdiRear m59 : 23|1@1+ (1,0) [0|1] "" Vector__XXX
 SG_ APP_sw059_sensorStatusFront m59 : 24|1@1+ (1,0) [0|1] "" Vector__XXX
 SG_ APP_sw059_sensorStatusRear m59 : 25|1@1+ (1,0) [0|1] "" Vector__XXX
 SG_ APP_sw059_status2 m59 : 26|1@1+ (1,0) [0|1] "" Vector__XXX
 SG_ APP_sw059_status m59 : 27|1@1+ (1,0) [0|1] "" Vector__XXX
 SG_ APP_sw061_states m61 : 16|1@1+ (1,0) [0|1] "" Vector__XXX
 SG_ APP_sw061_axleData m61 : 17|1@1+ (1,0) [0|1] "" Vector__XXX
 SG_ APP_sw061_dampingStates m61 : 18|1@1+ (1,0) [0|1] "" Vector__XXX
 SG_ APP_sw061_speedBumpAttributes m61 : 19|1@1+ (1,0) [0|1] "" Vector__XXX
 SG_ APP_sw063_expectedMajorVer m63 : 16|8@1+ (1,0) [0|255] "" Vector__XXX
 SG_ APP_sw063_detectedMajorVer m63 : 24|8@1+ (1,0) [0|255] "" Vector__XXX
 SG_ APP_sw063_expectedMinorVer m63 : 32|8@1+ (1,0) [0|255] "" Vector__XXX
 SG_ APP_sw063_detectedMinorVer m63 : 40|8@1+ (1,0) [0|255] "" Vector__XXX
 SG_ APP_sw063_expectedSubMinorVer m63 : 48|8@1+ (1,0) [0|255] "" Vector__XXX
 SG_ APP_sw063_detectedSubMinorVer m63 : 56|8@1+ (1,0) [0|255] "" Vector__XXX
 SG_ APP_sw064_sysStatus m64 : 16|1@1+ (1,0) [0|1] "" Vector__XXX
 SG_ APP_sw064_status m64 : 17|1@1+ (1,0) [0|1] "" Vector__XXX
 SG_ APP_sw073_escalateLDWs m73 : 16|1@1+ (1,0) [0|1] "" Vector__XXX
 SG_ APP_sw073_silentEscalatedLDW m73 : 17|1@1+ (1,0) [0|1] "" Vector__XXX
 SG_ APP_sw073_escalateLDWreason m73 : 18|3@1+ (1,0) [0|7] "" Vector__XXX
 SG_ APP_sw073_rawMobileyeLDW m73 : 21|2@1+ (1,0) [0|3] "" Vector__XXX
 SG_ APP_sw073_freespaceLDW m73 : 24|2@1+ (1,0) [0|3] "" Vector__XXX
 SG_ APP_sw073_freespaceLeftC0 m73 : 26|7@1+ (0.2,-12.8) [-12.8|12.6] "m" Vector__XXX
 SG_ APP_sw073_freespaceRightC0 m73 : 33|7@1+ (0.2,-12.8) [-12.8|12.6] "m" Vector__XXX
 SG_ APP_sw073_freespaceLeftC1 m73 : 40|8@1+ (0.0016,-0.2) [-0.2|0.208] "rad" Vector__XXX
 SG_ APP_sw073_freespaceRightC1 m73 : 48|8@1+ (0.0016,-0.2) [-0.2|0.208] "rad" Vector__XXX
 SG_ APP_sw073_freespaceLeftFarZ m73 : 56|4@1+ (4,0) [0|60] "m" Vector__XXX
 SG_ APP_sw073_freespaceRightFarZ m73 : 60|4@1+ (4,0) [0|60] "m" Vector__XXX
 SG_ APP_sw075_scMia m75 : 16|8@1+ (1,0) [0|255] "" Vector__XXX
 SG_ APP_sw075_unusedByte m75 : 24|8@1+ (1,0) [0|255] "" Vector__XXX
 SG_ APP_sw075_unusedW0 m75 : 32|16@1+ (1,0) [0|65535] "" Vector__XXX
 SG_ APP_sw075_unusedW1 m75 : 48|16@1+ (1,0) [0|65535] "" Vector__XXX
 SG_ APP_sw077_oocDistance m77 : 16|9@1+ (1,0) [0|511] "cm" Vector__XXX
 SG_ APP_sw077_oocConfidence m77 : 25|7@1+ (1,0) [0|127] "%" Vector__XXX
 SG_ APP_sw077_oocCollisionSide m77 : 32|3@1+ (1,0) [0|7] "" Vector__XXX
 SG_ APP_sw077_oocHeight m77 : 35|2@1+ (1,0) [0|3] "" Vector__XXX
 SG_ APP_sw077_vehicleSpeed m77 : 37|10@1+ (0.05,-25) [-25|26.15] "MPH" Vector__XXX
 SG_ APP_sw077_oocUntrackedTime m77 : 48|6@1+ (0.1,0) [0|6.3] "s" Vector__XXX
 SG_ APP_sw077_oocOffCourseDist_cm m77 : 54|10@1- (1,0) [-512|511] "" Vector__XXX
 SG_ APP_sw080_sensors_healty_check m80 : 16|1@1+ (1,0) [0|1] "" Vector__XXX
 SG_ APP_sw080_dist_travelled_check m80 : 17|1@1+ (1,0) [0|1] "" Vector__XXX
 SG_ APP_sw080_road_class_check m80 : 18|1@1+ (1,0) [0|1] "" Vector__XXX
 SG_ APP_sw080_stw_angle_check m80 : 19|1@1+ (1,0) [0|1] "" Vector__XXX
 SG_ APP_sw080_rad_tar_5_check m80 : 20|1@1+ (1,0) [0|1] "" Vector__XXX
 SG_ APP_sw080_ultrasonic_obs_check m80 : 21|1@1+ (1,0) [0|1] "" Vector__XXX
 SG_ APP_sw080_freespace_check m80 : 22|1@1+ (1,0) [0|1] "" Vector__XXX
 SG_ APP_sw080_pedestrian_check m80 : 23|1@1+ (1,0) [0|1] "" Vector__XXX
 SG_ APP_sw080_rad_tar_5_dist m80 : 24|6@1+ (1,0) [0|63] "m" Vector__XXX
 SG_ APP_sw080_stw_angle_deg m80 : 32|8@1+ (1,0) [0|255] "deg" Vector__XXX
 SG_ APP_sw080_road_class m80 : 40|3@1+ (1,0) [0|7] "" Vector__XXX
 SG_ APP_sw080_ego_speed m80 : 43|5@1+ (1,0) [0|31] "mph" Vector__XXX
 SG_ APP_sw080_cipv_valid m80 : 48|1@1+ (1,0) [0|1] "" Vector__XXX
 SG_ APP_sw080_min_speed_check m80 : 49|1@1+ (1,0) [0|1] "" Vector__XXX
 SG_ APP_sw080_cruise_lever_state m80 : 50|3@1+ (1,0) [0|7] "" Vector__XXX
 SG_ APP_sw080_cruise_speed_check m80 : 53|1@1+ (1,0) [0|1] "" Vector__XXX
 SG_ APP_sw081_radarDistance m81 : 16|8@1+ (0.0625,0) [0|15.9375] "m" Vector__XXX
 SG_ APP_sw081_radarTTC m81 : 24|8@1+ (0.02,0) [0|5.1] "seconds" Vector__XXX
 SG_ APP_sw081_cameraDistance m81 : 32|8@1+ (0.0625,0) [0|15.9375] "m" Vector__XXX
 SG_ APP_sw081_cameraTTC m81 : 40|8@1+ (0.02,0) [0|5.1] "seconds" Vector__XXX
 SG_ APP_sw081_pedalPosition m81 : 48|7@1+ (1,0) [0|127] "%" Vector__XXX
 SG_ APP_sw129_mainCamExtNoCalFile m129 : 16|1@1+ (1,0) [0|1] "" Vector__XXX
 SG_ APP_sw130_narrowCamExtNoCalFile m130 : 16|1@1+ (1,0) [0|1] "" Vector__XXX
 SG_ APP_sw133_mainCamDeserFault m133 : 16|3@1+ (1,0) [0|7] "" Vector__XXX
 SG_ APP_sw133_mainCamI2CbusFault m133 : 19|1@1+ (1,0) [0|1] "" Vector__XXX
 SG_ APP_sw133_mainCamSensorFault m133 : 20|3@1+ (1,0) [0|7] "" Vector__XXX
 SG_ APP_sw133_mainCamSerFault m133 : 24|3@1+ (1,0) [0|7] "" Vector__XXX
 SG_ APP_sw134_narrowCamDeserFault m134 : 16|3@1+ (1,0) [0|7] "" Vector__XXX
 SG_ APP_sw134_narrowCamI2CbusFault m134 : 19|1@1+ (1,0) [0|1] "" Vector__XXX
 SG_ APP_sw134_narrowCamSensorFault m134 : 20|3@1+ (1,0) [0|7] "" Vector__XXX
 SG_ APP_sw134_narrowCamSerFault m134 : 24|3@1+ (1,0) [0|7] "" Vector__XXX
 SG_ APP_sw135_fisheyeCamDeserFault m135 : 16|3@1+ (1,0) [0|7] "" Vector__XXX
 SG_ APP_sw135_fisheyeCamI2CbusFault m135 : 19|1@1+ (1,0) [0|1] "" Vector__XXX
 SG_ APP_sw135_fisheyeCamSensorFault m135 : 20|3@1+ (1,0) [0|7] "" Vector__XXX
 SG_ APP_sw135_fisheyeCamSerFault m135 : 24|3@1+ (1,0) [0|7] "" Vector__XXX
 SG_ APP_sw136_lPillarCamDeserFault m136 : 16|3@1+ (1,0) [0|7] "" Vector__XXX
 SG_ APP_sw136_lPillarCamI2CbusFault m136 : 19|1@1+ (1,0) [0|1] "" Vector__XXX
 SG_ APP_sw136_lPillarCamSensorFault m136 : 20|3@1+ (1,0) [0|7] "" Vector__XXX
 SG_ APP_sw136_lPillarCamSerFault m136 : 24|3@1+ (1,0) [0|7] "" Vector__XXX
 SG_ APP_sw137_rPillarCamDeserFault m137 : 16|3@1+ (1,0) [0|7] "" Vector__XXX
 SG_ APP_sw137_rPillarCamI2CbusFault m137 : 19|1@1+ (1,0) [0|1] "" Vector__XXX
 SG_ APP_sw137_rPillarCamSensorFault m137 : 20|3@1+ (1,0) [0|7] "" Vector__XXX
 SG_ APP_sw137_rPillarCamSerFault m137 : 24|3@1+ (1,0) [0|7] "" Vector__XXX
 SG_ APP_sw138_lRepeatCamDeserFault m138 : 16|3@1+ (1,0) [0|7] "" Vector__XXX
 SG_ APP_sw138_lRepeatCamI2CbusFault m138 : 19|1@1+ (1,0) [0|1] "" Vector__XXX
 SG_ APP_sw138_lRepeatCamSensorFault m138 : 20|3@1+ (1,0) [0|7] "" Vector__XXX
 SG_ APP_sw138_lRepeatCamSerFault m138 : 24|3@1+ (1,0) [0|7] "" Vector__XXX
 SG_ APP_sw139_rRepeatCamDeserFault m139 : 16|3@1+ (1,0) [0|7] "" Vector__XXX
 SG_ APP_sw139_rRepeatCamI2CbusFault m139 : 19|1@1+ (1,0) [0|1] "" Vector__XXX
 SG_ APP_sw139_rRepeatCamSensorFault m139 : 20|3@1+ (1,0) [0|7] "" Vector__XXX
 SG_ APP_sw139_rRepeatCamSerFault m139 : 24|3@1+ (1,0) [0|7] "" Vector__XXX
 SG_ APP_sw140_backupCamCSIBridgeFlt m140 : 16|3@1+ (1,0) [0|7] "" Vector__XXX
 SG_ APP_sw140_backupCamDeserFault m140 : 19|3@1+ (1,0) [0|7] "" Vector__XXX
 SG_ APP_sw140_backupCamI2CbusFault m140 : 22|1@1+ (1,0) [0|1] "" Vector__XXX
 SG_ APP_sw140_backupCamSensorFault m140 : 24|3@1+ (1,0) [0|7] "" Vector__XXX
 SG_ APP_sw140_backupCamUARTbusFault m140 : 27|1@1+ (1,0) [0|1] "" Vector__XXX
 SG_ APP_sw140_backupCamSXDeserFailed m140 : 28|1@1+ (1,0) [0|1] "" Vector__XXX
 SG_ APP_sw140_backupCamDeserLock m140 : 29|2@1+ (1,0) [0|3] "" Vector__XXX
 SG_ APP_sw140_backupCamSerFault m140 : 32|3@1+ (1,0) [0|7] "" Vector__XXX
 SG_ APP_sw140_backupCamHDMISerFault m140 : 35|1@1+ (1,0) [0|1] "" Vector__XXX
 SG_ APP_sw141_maxThreshold m141 : 16|8@1- (1,0) [-128|127] "degC" Vector__XXX
 SG_ APP_sw141_minThreshold m141 : 24|8@1- (1,0) [-128|127] "degC" Vector__XXX
 SG_ APP_sw141_tempSensorId m141 : 32|8@1+ (1,0) [0|255] "" Vector__XXX
 SG_ APP_sw141_temperature m141 : 40|8@1- (1,0) [-128|127] "degC" Vector__XXX
 SG_ APP_sw142_camExtPitchCal m142 : 16|9@1+ (0.05,-12.5) [-12.5|13.05] "deg" Vector__XXX
 SG_ APP_sw142_pitchOffsetAtmptVal m142 : 25|9@1+ (1,-256) [-256|255] "pixels" Vector__XXX
 SG_ APP_sw142_problemCamPosition m142 : 34|4@1+ (1,0) [0|15] "" Vector__XXX
 SG_ APP_sw145_pitchSpike m145 : 16|1@1+ (1,0) [0|1] "" Vector__XXX
 SG_ APP_sw145_yawSpike m145 : 17|1@1+ (1,0) [0|1] "" Vector__XXX
 SG_ APP_sw145_rollSpike m145 : 18|1@1+ (1,0) [0|1] "" Vector__XXX
 SG_ APP_sw145_insaneCal m145 : 19|1@1+ (1,0) [0|1] "" Vector__XXX
 SG_ APP_sw145_problemSaving m145 : 20|1@1+ (1,0) [0|1] "" Vector__XXX
 SG_ APP_sw145_problemCamPosition m145 : 24|4@1+ (1,0) [0|15] "" Vector__XXX
 SG_ APP_sw145_camExtPitchCal m145 : 28|9@1+ (0.05,-12.5) [-12.5|13.05] "deg" Vector__XXX
 SG_ APP_sw145_camExtYawCal m145 : 37|9@1+ (0.05,-12.5) [-12.5|13.05] "deg" Vector__XXX
 SG_ APP_sw145_camExtRollCal m145 : 46|9@1+ (0.05,-12.5) [-12.5|13.05] "deg" Vector__XXX
 SG_ APP_sw147_selfieCamDeserFault m147 : 16|3@1+ (1,0) [0|7] "" Vector__XXX
 SG_ APP_sw147_selfieCamI2CbusFault m147 : 19|1@1+ (1,0) [0|1] "" Vector__XXX
 SG_ APP_sw147_selfieCamSensorFault m147 : 20|3@1+ (1,0) [0|7] "" Vector__XXX
 SG_ APP_sw147_selfieCamSerFault m147 : 24|3@1+ (1,0) [0|7] "" Vector__XXX
 SG_ APP_sw150_locStatus m150 : 16|1@1+ (1,0) [0|1] "" Vector__XXX
 SG_ APP_sw150_speed m150 : 17|1@1+ (1,0) [0|1] "" Vector__XXX
 SG_ APP_sw150_systemStatus m150 : 18|1@1+ (1,0) [0|1] "" Vector__XXX
 SG_ APP_sw150_chassisControl m150 : 19|1@1+ (1,0) [0|1] "" Vector__XXX
 SG_ APP_sw150_locStatus2 m150 : 20|1@1+ (1,0) [0|1] "" Vector__XXX
 SG_ APP_sw150_autonomyHealth m150 : 21|1@1+ (1,0) [0|1] "" Vector__XXX
 SG_ APP_sw150_chassisControl2 m150 : 22|1@1+ (1,0) [0|1] "" Vector__XXX
 SG_ APP_sw151_sysStatus m151 : 16|1@1+ (1,0) [0|1] "" Vector__XXX
 SG_ APP_sw151_status m151 : 17|1@1+ (1,0) [0|1] "" Vector__XXX
 SG_ APP_sw152_status m152 : 16|1@1+ (1,0) [0|1] "" Vector__XXX
 SG_ APP_sw152_wheelRotation m152 : 17|1@1+ (1,0) [0|1] "" Vector__XXX
 SG_ APP_sw152_wheelSpeeds m152 : 18|1@1+ (1,0) [0|1] "" Vector__XXX
 SG_ APP_sw153_inertial1 m153 : 16|1@1+ (1,0) [0|1] "" Vector__XXX
 SG_ APP_sw153_inertial2 m153 : 17|1@1+ (1,0) [0|1] "" Vector__XXX
 SG_ APP_sw153_inertial3 m153 : 18|1@1+ (1,0) [0|1] "" Vector__XXX
 SG_ APP_sw153_inertial4 m153 : 19|1@1+ (1,0) [0|1] "" Vector__XXX
 SG_ APP_sw154_restraintStatus m154 : 16|1@1+ (1,0) [0|1] "" Vector__XXX
 SG_ APP_sw154_doorStatus m154 : 17|1@1+ (1,0) [0|1] "" Vector__XXX
 SG_ APP_sw155_restraintStatus m155 : 16|1@1+ (1,0) [0|1] "" Vector__XXX
 SG_ APP_sw155_doorStatus m155 : 17|1@1+ (1,0) [0|1] "" Vector__XXX
 SG_ APP_sw156_status m156 : 16|1@1+ (1,0) [0|1] "" Vector__XXX
 SG_ APP_sw156_autonomyHealth m156 : 17|1@1+ (1,0) [0|1] "" Vector__XXX
 SG_ APP_sw157_leftStalk m157 : 16|1@1+ (1,0) [0|1] "" Vector__XXX
 SG_ APP_sw157_rightStalk m157 : 17|1@1+ (1,0) [0|1] "" Vector__XXX
 SG_ APP_sw157_steeringAngleSensor m157 : 18|1@1+ (1,0) [0|1] "" Vector__XXX
 SG_ APP_sw158_lvPowerState m158 : 16|1@1+ (1,0) [0|1] "" Vector__XXX
 SG_ APP_sw158_vehicleStatus m158 : 17|1@1+ (1,0) [0|1] "" Vector__XXX
 SG_ APP_sw158_status m158 : 18|1@1+ (1,0) [0|1] "" Vector__XXX
 SG_ APP_sw158_lighting m158 : 19|1@1+ (1,0) [0|1] "" Vector__XXX
 SG_ APP_sw158_LVHealth m158 : 20|1@1+ (1,0) [0|1] "" Vector__XXX
 SG_ APP_sw158_sensors m158 : 21|1@1+ (1,0) [0|1] "" Vector__XXX
 SG_ APP_sw158_coolant m158 : 22|1@1+ (1,0) [0|1] "" Vector__XXX
 SG_ APP_sw159_doorStatus m159 : 16|1@1+ (1,0) [0|1] "" Vector__XXX
 SG_ APP_sw159_switchStatus m159 : 17|1@1+ (1,0) [0|1] "" Vector__XXX
 SG_ APP_sw160_doorStatus m160 : 16|1@1+ (1,0) [0|1] "" Vector__XXX
 SG_ APP_sw160_thsStatus m160 : 17|1@1+ (1,0) [0|1] "" Vector__XXX
 SG_ APP_sw160_hvacStatus m160 : 18|1@1+ (1,0) [0|1] "" Vector__XXX
 SG_ APP_sw160_switchStatus m160 : 19|1@1+ (1,0) [0|1] "" Vector__XXX
 SG_ APP_sw161_frameTimeout m161 : 16|1@1+ (1,0) [0|1] "" Vector__XXX
 SG_ APP_sw161_hdmiDisplayError m161 : 17|1@1+ (1,0) [0|1] "" Vector__XXX
 SG_ APP_sw161_rawImageTimeout m161 : 18|1@1+ (1,0) [0|1] "" Vector__XXX
 SG_ APP_sw161_imagerOutOfSpecTemp m161 : 19|1@1+ (1,0) [0|1] "" Vector__XXX
 SG_ APP_sw162_colorFilterMismatch m162 : 16|1@1+ (1,0) [0|1] "" Vector__XXX
 SG_ APP_sw162_detectedColorFilter m162 : 17|2@1+ (1,0) [0|3] "" Vector__XXX
 SG_ APP_sw162_expectedColorFilter m162 : 19|2@1+ (1,0) [0|3] "" Vector__XXX
 SG_ APP_sw162_cameraPositionMismatch m162 : 21|1@1+ (1,0) [0|1] "" Vector__XXX
 SG_ APP_sw162_blacklistedFuseID m162 : 22|1@1+ (1,0) [0|1] "" Vector__XXX
 SG_ APP_sw162_uuidMismatch m162 : 23|1@1+ (1,0) [0|1] "" Vector__XXX
 SG_ APP_sw162_detectedPosition m162 : 24|4@1+ (1,0) [0|15] "" Vector__XXX
 SG_ APP_sw163_colorFilterMismatch m163 : 16|1@1+ (1,0) [0|1] "" Vector__XXX
 SG_ APP_sw163_detectedColorFilter m163 : 17|2@1+ (1,0) [0|3] "" Vector__XXX
 SG_ APP_sw163_expectedColorFilter m163 : 19|2@1+ (1,0) [0|3] "" Vector__XXX
 SG_ APP_sw163_cameraPositionMismatch m163 : 21|1@1+ (1,0) [0|1] "" Vector__XXX
 SG_ APP_sw163_blacklistedFuseID m163 : 22|1@1+ (1,0) [0|1] "" Vector__XXX
 SG_ APP_sw163_uuidMismatch m163 : 23|1@1+ (1,0) [0|1] "" Vector__XXX
 SG_ APP_sw163_detectedPosition m163 : 24|4@1+ (1,0) [0|15] "" Vector__XXX
 SG_ APP_sw164_colorFilterMismatch m164 : 16|1@1+ (1,0) [0|1] "" Vector__XXX
 SG_ APP_sw164_detectedColorFilter m164 : 17|2@1+ (1,0) [0|3] "" Vector__XXX
 SG_ APP_sw164_expectedColorFilter m164 : 19|2@1+ (1,0) [0|3] "" Vector__XXX
 SG_ APP_sw164_cameraPositionMismatch m164 : 21|1@1+ (1,0) [0|1] "" Vector__XXX
 SG_ APP_sw164_blacklistedFuseID m164 : 22|1@1+ (1,0) [0|1] "" Vector__XXX
 SG_ APP_sw164_uuidMismatch m164 : 23|1@1+ (1,0) [0|1] "" Vector__XXX
 SG_ APP_sw164_detectedPosition m164 : 24|4@1+ (1,0) [0|15] "" Vector__XXX
 SG_ APP_sw165_colorFilterMismatch m165 : 16|1@1+ (1,0) [0|1] "" Vector__XXX
 SG_ APP_sw165_detectedColorFilter m165 : 17|2@1+ (1,0) [0|3] "" Vector__XXX
 SG_ APP_sw165_expectedColorFilter m165 : 19|2@1+ (1,0) [0|3] "" Vector__XXX
 SG_ APP_sw165_cameraPositionMismatch m165 : 21|1@1+ (1,0) [0|1] "" Vector__XXX
 SG_ APP_sw165_blacklistedFuseID m165 : 22|1@1+ (1,0) [0|1] "" Vector__XXX
 SG_ APP_sw165_uuidMismatch m165 : 23|1@1+ (1,0) [0|1] "" Vector__XXX
 SG_ APP_sw165_detectedPosition m165 : 24|4@1+ (1,0) [0|15] "" Vector__XXX
 SG_ APP_sw166_colorFilterMismatch m166 : 16|1@1+ (1,0) [0|1] "" Vector__XXX
 SG_ APP_sw166_detectedColorFilter m166 : 17|2@1+ (1,0) [0|3] "" Vector__XXX
 SG_ APP_sw166_expectedColorFilter m166 : 19|2@1+ (1,0) [0|3] "" Vector__XXX
 SG_ APP_sw166_cameraPositionMismatch m166 : 21|1@1+ (1,0) [0|1] "" Vector__XXX
 SG_ APP_sw166_blacklistedFuseID m166 : 22|1@1+ (1,0) [0|1] "" Vector__XXX
 SG_ APP_sw166_uuidMismatch m166 : 23|1@1+ (1,0) [0|1] "" Vector__XXX
 SG_ APP_sw166_detectedPosition m166 : 24|4@1+ (1,0) [0|15] "" Vector__XXX
 SG_ APP_sw167_colorFilterMismatch m167 : 16|1@1+ (1,0) [0|1] "" Vector__XXX
 SG_ APP_sw167_detectedColorFilter m167 : 17|2@1+ (1,0) [0|3] "" Vector__XXX
 SG_ APP_sw167_expectedColorFilter m167 : 19|2@1+ (1,0) [0|3] "" Vector__XXX
 SG_ APP_sw167_cameraPositionMismatch m167 : 21|1@1+ (1,0) [0|1] "" Vector__XXX
 SG_ APP_sw167_blacklistedFuseID m167 : 22|1@1+ (1,0) [0|1] "" Vector__XXX
 SG_ APP_sw167_uuidMismatch m167 : 23|1@1+ (1,0) [0|1] "" Vector__XXX
 SG_ APP_sw167_detectedPosition m167 : 24|4@1+ (1,0) [0|15] "" Vector__XXX
 SG_ APP_sw168_colorFilterMismatch m168 : 16|1@1+ (1,0) [0|1] "" Vector__XXX
 SG_ APP_sw168_detectedColorFilter m168 : 17|2@1+ (1,0) [0|3] "" Vector__XXX
 SG_ APP_sw168_expectedColorFilter m168 : 19|2@1+ (1,0) [0|3] "" Vector__XXX
 SG_ APP_sw168_cameraPositionMismatch m168 : 21|1@1+ (1,0) [0|1] "" Vector__XXX
 SG_ APP_sw168_blacklistedFuseID m168 : 22|1@1+ (1,0) [0|1] "" Vector__XXX
 SG_ APP_sw168_uuidMismatch m168 : 23|1@1+ (1,0) [0|1] "" Vector__XXX
 SG_ APP_sw168_detectedPosition m168 : 24|4@1+ (1,0) [0|15] "" Vector__XXX
 SG_ APP_sw169_colorFilterMismatch m169 : 16|1@1+ (1,0) [0|1] "" Vector__XXX
 SG_ APP_sw169_detectedColorFilter m169 : 17|2@1+ (1,0) [0|3] "" Vector__XXX
 SG_ APP_sw169_expectedColorFilter m169 : 19|2@1+ (1,0) [0|3] "" Vector__XXX
 SG_ APP_sw169_cameraPositionMismatch m169 : 21|1@1+ (1,0) [0|1] "" Vector__XXX
 SG_ APP_sw169_blacklistedFuseID m169 : 22|1@1+ (1,0) [0|1] "" Vector__XXX
 SG_ APP_sw169_uuidMismatch m169 : 23|1@1+ (1,0) [0|1] "" Vector__XXX
 SG_ APP_sw169_detectedPosition m169 : 24|4@1+ (1,0) [0|15] "" Vector__XXX
 SG_ APP_sw170_colorFilterMismatch m170 : 16|1@1+ (1,0) [0|1] "" Vector__XXX
 SG_ APP_sw170_detectedColorFilter m170 : 17|2@1+ (1,0) [0|3] "" Vector__XXX
 SG_ APP_sw170_expectedColorFilter m170 : 19|2@1+ (1,0) [0|3] "" Vector__XXX
 SG_ APP_sw170_cameraPositionMismatch m170 : 21|1@1+ (1,0) [0|1] "" Vector__XXX
 SG_ APP_sw170_blacklistedFuseID m170 : 22|1@1+ (1,0) [0|1] "" Vector__XXX
 SG_ APP_sw170_uuidMismatch m170 : 23|1@1+ (1,0) [0|1] "" Vector__XXX
 SG_ APP_sw170_detectedPosition m170 : 24|4@1+ (1,0) [0|15] "" Vector__XXX
 SG_ APP_sw171_APP_parkerATemp m171 : 16|8@1+ (1,-128) [-128|127] "C" Vector__XXX
 SG_ APP_sw171_APP_parkerBTemp m171 : 24|8@1+ (1,-128) [-128|127] "C" Vector__XXX
 SG_ APP_sw171_APP_pascalTemp m171 : 32|8@1+ (1,-128) [-128|127] "C" Vector__XXX
 SG_ APP_sw171_APP_pascalExtTemp m171 : 40|8@1+ (1,-128) [-128|127] "C" Vector__XXX
 SG_ APP_sw172_fisheyeCamExtNoCalFile m172 : 16|1@1+ (1,0) [0|1] "" Vector__XXX
 SG_ APP_sw173_lPillarCamExtNoCalFile m173 : 16|1@1+ (1,0) [0|1] "" Vector__XXX
 SG_ APP_sw174_rPillarCamExtNoCalFile m174 : 16|1@1+ (1,0) [0|1] "" Vector__XXX
 SG_ APP_sw175_lRepeatCamExtNoCalFile m175 : 16|1@1+ (1,0) [0|1] "" Vector__XXX
 SG_ APP_sw176_rRepeatCamExtNoCalFile m176 : 16|1@1+ (1,0) [0|1] "" Vector__XXX
 SG_ APP_sw182_exitStatus m182 : 16|1@1+ (1,0) [0|1] "" Vector__XXX
 SG_ APP_sw182_bufferError m182 : 17|1@1+ (1,0) [0|1] "" Vector__XXX
 SG_ APP_sw182_frameGrabFailure m182 : 18|1@1+ (1,0) [0|1] "" Vector__XXX
 SG_ APP_sw182_gainControlFailure m182 : 19|1@1+ (1,0) [0|1] "" Vector__XXX
 SG_ APP_sw182_tempMonitorFailure m182 : 20|2@1+ (1,0) [0|3] "" Vector__XXX
 SG_ APP_sw182_firstFrameGrabFailure m182 : 22|1@1+ (1,0) [0|1] "" Vector__XXX
 SG_ APP_sw182_deserParityError m182 : 23|1@1+ (1,0) [0|1] "" Vector__XXX
 SG_ APP_sw182_deserLockError m182 : 24|1@1+ (1,0) [0|1] "" Vector__XXX
 SG_ APP_sw182_deserCrcError m182 : 25|1@1+ (1,0) [0|1] "" Vector__XXX
 SG_ APP_sw182_imagerHeartbeat m182 : 26|2@1+ (1,0) [0|2] "" Vector__XXX
 SG_ APP_sw182_serializerCrcErrCount m182 : 28|8@1+ (1,0) [0|254] "" Vector__XXX
 SG_ APP_sw182_deserLineLengthError m182 : 36|1@1+ (1,0) [0|1] "" Vector__XXX
 SG_ APP_sw182_numCaptureRecoveries m182 : 37|3@1+ (1,0) [0|7] "" Vector__XXX
 SG_ APP_sw182_currentTemperature m182 : 40|8@1+ (1,-60) [-60|194] "degC" Vector__XXX
 SG_ APP_sw182_minTemperature m182 : 48|8@1+ (1,-60) [-60|194] "degC" Vector__XXX
 SG_ APP_sw182_maxTemperature m182 : 56|8@1+ (1,-60) [-60|194] "degC" Vector__XXX
 SG_ APP_sw183_exitStatus m183 : 16|1@1+ (1,0) [0|1] "" Vector__XXX
 SG_ APP_sw183_bufferError m183 : 17|1@1+ (1,0) [0|1] "" Vector__XXX
 SG_ APP_sw183_frameGrabFailure m183 : 18|1@1+ (1,0) [0|1] "" Vector__XXX
 SG_ APP_sw183_gainControlFailure m183 : 19|1@1+ (1,0) [0|1] "" Vector__XXX
 SG_ APP_sw183_tempMonitorFailure m183 : 20|2@1+ (1,0) [0|3] "" Vector__XXX
 SG_ APP_sw183_firstFrameGrabFailure m183 : 22|1@1+ (1,0) [0|1] "" Vector__XXX
 SG_ APP_sw183_deserParityError m183 : 23|1@1+ (1,0) [0|1] "" Vector__XXX
 SG_ APP_sw183_deserLockError m183 : 24|1@1+ (1,0) [0|1] "" Vector__XXX
 SG_ APP_sw183_deserCrcError m183 : 25|1@1+ (1,0) [0|1] "" Vector__XXX
 SG_ APP_sw183_imagerHeartbeat m183 : 26|2@1+ (1,0) [0|2] "" Vector__XXX
 SG_ APP_sw183_serializerCrcErrCount m183 : 28|8@1+ (1,0) [0|254] "" Vector__XXX
 SG_ APP_sw183_deserLineLengthError m183 : 36|1@1+ (1,0) [0|1] "" Vector__XXX
 SG_ APP_sw183_numCaptureRecoveries m183 : 37|3@1+ (1,0) [0|7] "" Vector__XXX
 SG_ APP_sw183_currentTemperature m183 : 40|8@1+ (1,-60) [-60|194] "degC" Vector__XXX
 SG_ APP_sw183_minTemperature m183 : 48|8@1+ (1,-60) [-60|194] "degC" Vector__XXX
 SG_ APP_sw183_maxTemperature m183 : 56|8@1+ (1,-60) [-60|194] "degC" Vector__XXX
 SG_ APP_sw184_exitStatus m184 : 16|1@1+ (1,0) [0|1] "" Vector__XXX
 SG_ APP_sw184_bufferError m184 : 17|1@1+ (1,0) [0|1] "" Vector__XXX
 SG_ APP_sw184_frameGrabFailure m184 : 18|1@1+ (1,0) [0|1] "" Vector__XXX
 SG_ APP_sw184_gainControlFailure m184 : 19|1@1+ (1,0) [0|1] "" Vector__XXX
 SG_ APP_sw184_tempMonitorFailure m184 : 20|2@1+ (1,0) [0|3] "" Vector__XXX
 SG_ APP_sw184_firstFrameGrabFailure m184 : 22|1@1+ (1,0) [0|1] "" Vector__XXX
 SG_ APP_sw184_deserParityError m184 : 23|1@1+ (1,0) [0|1] "" Vector__XXX
 SG_ APP_sw184_deserLockError m184 : 24|1@1+ (1,0) [0|1] "" Vector__XXX
 SG_ APP_sw184_deserCrcError m184 : 25|1@1+ (1,0) [0|1] "" Vector__XXX
 SG_ APP_sw184_imagerHeartbeat m184 : 26|2@1+ (1,0) [0|2] "" Vector__XXX
 SG_ APP_sw184_serializerCrcErrCount m184 : 28|8@1+ (1,0) [0|254] "" Vector__XXX
 SG_ APP_sw184_deserLineLengthError m184 : 36|1@1+ (1,0) [0|1] "" Vector__XXX
 SG_ APP_sw184_numCaptureRecoveries m184 : 37|3@1+ (1,0) [0|7] "" Vector__XXX
 SG_ APP_sw184_currentTemperature m184 : 40|8@1+ (1,-60) [-60|194] "degC" Vector__XXX
 SG_ APP_sw184_minTemperature m184 : 48|8@1+ (1,-60) [-60|194] "degC" Vector__XXX
 SG_ APP_sw184_maxTemperature m184 : 56|8@1+ (1,-60) [-60|194] "degC" Vector__XXX
 SG_ APP_sw185_exitStatus m185 : 16|1@1+ (1,0) [0|1] "" Vector__XXX
 SG_ APP_sw185_bufferError m185 : 17|1@1+ (1,0) [0|1] "" Vector__XXX
 SG_ APP_sw185_frameGrabFailure m185 : 18|1@1+ (1,0) [0|1] "" Vector__XXX
 SG_ APP_sw185_gainControlFailure m185 : 19|1@1+ (1,0) [0|1] "" Vector__XXX
 SG_ APP_sw185_tempMonitorFailure m185 : 20|2@1+ (1,0) [0|3] "" Vector__XXX
 SG_ APP_sw185_firstFrameGrabFailure m185 : 22|1@1+ (1,0) [0|1] "" Vector__XXX
 SG_ APP_sw185_deserParityError m185 : 23|1@1+ (1,0) [0|1] "" Vector__XXX
 SG_ APP_sw185_deserLockError m185 : 24|1@1+ (1,0) [0|1] "" Vector__XXX
 SG_ APP_sw185_deserCrcError m185 : 25|1@1+ (1,0) [0|1] "" Vector__XXX
 SG_ APP_sw185_imagerHeartbeat m185 : 26|2@1+ (1,0) [0|2] "" Vector__XXX
 SG_ APP_sw185_serializerCrcErrCount m185 : 28|8@1+ (1,0) [0|254] "" Vector__XXX
 SG_ APP_sw185_deserLineLengthError m185 : 36|1@1+ (1,0) [0|1] "" Vector__XXX
 SG_ APP_sw185_numCaptureRecoveries m185 : 37|3@1+ (1,0) [0|7] "" Vector__XXX
 SG_ APP_sw185_currentTemperature m185 : 40|8@1+ (1,-60) [-60|194] "degC" Vector__XXX
 SG_ APP_sw185_minTemperature m185 : 48|8@1+ (1,-60) [-60|194] "degC" Vector__XXX
 SG_ APP_sw185_maxTemperature m185 : 56|8@1+ (1,-60) [-60|194] "degC" Vector__XXX
 SG_ APP_sw186_exitStatus m186 : 16|1@1+ (1,0) [0|1] "" Vector__XXX
 SG_ APP_sw186_bufferError m186 : 17|1@1+ (1,0) [0|1] "" Vector__XXX
 SG_ APP_sw186_frameGrabFailure m186 : 18|1@1+ (1,0) [0|1] "" Vector__XXX
 SG_ APP_sw186_gainControlFailure m186 : 19|1@1+ (1,0) [0|1] "" Vector__XXX
 SG_ APP_sw186_tempMonitorFailure m186 : 20|2@1+ (1,0) [0|3] "" Vector__XXX
 SG_ APP_sw186_firstFrameGrabFailure m186 : 22|1@1+ (1,0) [0|1] "" Vector__XXX
 SG_ APP_sw186_deserParityError m186 : 23|1@1+ (1,0) [0|1] "" Vector__XXX
 SG_ APP_sw186_deserLockError m186 : 24|1@1+ (1,0) [0|1] "" Vector__XXX
 SG_ APP_sw186_deserCrcError m186 : 25|1@1+ (1,0) [0|1] "" Vector__XXX
 SG_ APP_sw186_imagerHeartbeat m186 : 26|2@1+ (1,0) [0|2] "" Vector__XXX
 SG_ APP_sw186_serializerCrcErrCount m186 : 28|8@1+ (1,0) [0|254] "" Vector__XXX
 SG_ APP_sw186_deserLineLengthError m186 : 36|1@1+ (1,0) [0|1] "" Vector__XXX
 SG_ APP_sw186_numCaptureRecoveries m186 : 37|3@1+ (1,0) [0|7] "" Vector__XXX
 SG_ APP_sw186_currentTemperature m186 : 40|8@1+ (1,-60) [-60|194] "degC" Vector__XXX
 SG_ APP_sw186_minTemperature m186 : 48|8@1+ (1,-60) [-60|194] "degC" Vector__XXX
 SG_ APP_sw186_maxTemperature m186 : 56|8@1+ (1,-60) [-60|194] "degC" Vector__XXX
 SG_ APP_sw187_exitStatus m187 : 16|1@1+ (1,0) [0|1] "" Vector__XXX
 SG_ APP_sw187_bufferError m187 : 17|1@1+ (1,0) [0|1] "" Vector__XXX
 SG_ APP_sw187_frameGrabFailure m187 : 18|1@1+ (1,0) [0|1] "" Vector__XXX
 SG_ APP_sw187_gainControlFailure m187 : 19|1@1+ (1,0) [0|1] "" Vector__XXX
 SG_ APP_sw187_tempMonitorFailure m187 : 20|2@1+ (1,0) [0|3] "" Vector__XXX
 SG_ APP_sw187_firstFrameGrabFailure m187 : 22|1@1+ (1,0) [0|1] "" Vector__XXX
 SG_ APP_sw187_deserParityError m187 : 23|1@1+ (1,0) [0|1] "" Vector__XXX
 SG_ APP_sw187_deserLockError m187 : 24|1@1+ (1,0) [0|1] "" Vector__XXX
 SG_ APP_sw187_deserCrcError m187 : 25|1@1+ (1,0) [0|1] "" Vector__XXX
 SG_ APP_sw187_imagerHeartbeat m187 : 26|2@1+ (1,0) [0|2] "" Vector__XXX
 SG_ APP_sw187_serializerCrcErrCount m187 : 28|8@1+ (1,0) [0|254] "" Vector__XXX
 SG_ APP_sw187_deserLineLengthError m187 : 36|1@1+ (1,0) [0|1] "" Vector__XXX
 SG_ APP_sw187_numCaptureRecoveries m187 : 37|3@1+ (1,0) [0|7] "" Vector__XXX
 SG_ APP_sw187_currentTemperature m187 : 40|8@1+ (1,-60) [-60|194] "degC" Vector__XXX
 SG_ APP_sw187_minTemperature m187 : 48|8@1+ (1,-60) [-60|194] "degC" Vector__XXX
 SG_ APP_sw187_maxTemperature m187 : 56|8@1+ (1,-60) [-60|194] "degC" Vector__XXX
 SG_ APP_sw188_exitStatus m188 : 16|1@1+ (1,0) [0|1] "" Vector__XXX

BO_TX_BU_ 1360 : ADSP;
BO_TX_BU_ 1361 : ADSP;
BO_TX_BU_ 1362 : ADSP;
BO_TX_BU_ 1951 : ADSP;
BO_TX_BU_ 1383 : ADSP;
BO_TX_BU_ 600 : APB;
BO_TX_BU_ 909 : APP;
BO_TX_BU_ 1513 : APP;

CM_ "Tesla Model 3 / Model Y CAN bus database; bus ETH (Ethernet-side ids, not CAN ids); firmware 2026.26.6.5. Decoded CAN signal definitions (layout, scaling, units, value tables).";
CM_ BU_ ADSP "Audio amplifier";
CM_ BU_ APB "APB ECU";
CM_ BU_ APP "Driver assistance computer (primary)";
CM_ BU_ APS "Driver assistance computer (secondary)";
CM_ BU_ APSB "APSB ECU";
CM_ BU_ BB "BB ECU";
CM_ BU_ BMS "High-voltage battery management system";
CM_ BU_ CC "Charge cable controller";
CM_ BU_ CMP "A/C compressor";
CM_ BU_ CMPD "CMPD ECU";
CM_ BU_ CP "Charge port controller";
CM_ BU_ DAS "Driver assistance computer";
CM_ BU_ DI "Drive inverter";
CM_ BU_ DIF "Front drive inverter";
CM_ BU_ DIR "Rear drive inverter";
CM_ BU_ DPB "DPB ECU";
CM_ BU_ EPAS3P "Electric power steering (primary)";
CM_ BU_ EPAS3S "Electric power steering (secondary)";
CM_ BU_ EPASTP "EPASTP ECU";
CM_ BU_ EPASTS "EPASTS ECU";
CM_ BU_ EPBL "Left electric parking brake";
CM_ BU_ EPBR "Right electric parking brake";
CM_ BU_ ESP "Electronic stability control";
CM_ BU_ EVSE "EVSE ECU";
CM_ BU_ FC "FC ECU";
CM_ BU_ GTW "Gateway";
CM_ BU_ HCML "HCML ECU";
CM_ BU_ HCMR "HCMR ECU";
CM_ BU_ HVP "High-voltage processor (pack contactor and isolation controller)";
CM_ BU_ IBST "Electric brake booster";
CM_ BU_ ICR "ICR ECU";
CM_ BU_ IDB "IDB ECU";
CM_ BU_ LS "LS ECU";
CM_ BU_ OCS1P "Occupant classification system";
CM_ BU_ PARK "Parking assist sensors";
CM_ BU_ PCS "Power conversion system (on-board charger and DC-DC converter)";
CM_ BU_ PCS2 "PCS2 ECU";
CM_ BU_ PM "PM ECU";
CM_ BU_ PMF "PMF ECU";
CM_ BU_ PMR "PMR ECU";
CM_ BU_ PNCD "PNCD ECU";
CM_ BU_ PTC "Cabin heater";
CM_ BU_ RADC "Radar";
CM_ BU_ RCM "Restraint control module";
CM_ BU_ RCM2 "RCM2 ECU";
CM_ BU_ RCM3 "RCM3 ECU";
CM_ BU_ RCU "RCU ECU";
CM_ BU_ SCCM "Steering column control module";
CM_ BU_ SCM "SCM ECU";
CM_ BU_ SCS "SCS ECU";
CM_ BU_ SDCR "SDCR ECU";
CM_ BU_ TAS "Air suspension controller";
CM_ BU_ TCU "TCU ECU";
CM_ BU_ TCU2 "TCU2 ECU";
CM_ BU_ TPMS "Tire pressure monitoring";
CM_ BU_ TRCM "TRCM ECU";
CM_ BU_ UI "Touchscreen user interface computer";
CM_ BU_ UIS "UIS ECU";
CM_ BU_ UMC "UMC ECU";
CM_ BU_ USM "USM ECU";
CM_ BU_ V2G "V2G ECU";
CM_ BU_ VC "VC ECU";
CM_ BU_ VCBATT "VCBATT ECU";
CM_ BU_ VCBATT0 "VCBATT0 ECU";
CM_ BU_ VCBATT1 "VCBATT1 ECU";
CM_ BU_ VCBATT2 "VCBATT2 ECU";
CM_ BU_ VCCC "VCCC ECU";
CM_ BU_ VCFRONT "Front body controller";
CM_ BU_ VCFRONT1 "VCFRONT1 ECU";
CM_ BU_ VCFRONT2 "VCFRONT2 ECU";
CM_ BU_ VCLEFT "Left body controller";
CM_ BU_ VCRIGHT "Right body controller";
CM_ BU_ VCSEAT2L "VCSEAT2L ECU";
CM_ BU_ VCSEAT2R "VCSEAT2R ECU";
CM_ BU_ VCSEC "Vehicle security controller";
CM_ BU_ VEH "VEH ECU";
CM_ BO_ 1360 "Audio amplifier message: alert log";
CM_ SG_ 1360 ADSP_alertID "Audio amplifier: alert ID";
CM_ SG_ 1360 ADSP_alertState "Audio amplifier: alert state";
CM_ SG_ 1360 ADSP_a002_core "Audio amplifier: a002 core";
CM_ SG_ 1360 ADSP_a002_cause "Audio amplifier: a002 cause";
CM_ SG_ 1360 ADSP_a022_error "Audio amplifier: a022 error";
CM_ SG_ 1360 ADSP_a022_errorCount "Audio amplifier: a022 error count";
CM_ SG_ 1360 ADSP_a035_a2baFaultNode "Audio amplifier: a035 a2ba fault node";
CM_ SG_ 1360 ADSP_a035_timeout "Audio amplifier: a035 timeout";
CM_ SG_ 1360 ADSP_a035_a2baIntrType "Audio amplifier: a035 a2ba intr type";
CM_ SG_ 1360 ADSP_a035_a2baFaultType "Audio amplifier: a035 a2ba fault type";
CM_ SG_ 1360 ADSP_a036_a2bbFaultNode "Audio amplifier: a036 a2bb fault node";
CM_ SG_ 1360 ADSP_a036_timeout "Audio amplifier: a036 timeout";
CM_ SG_ 1360 ADSP_a036_a2bbIntrType "Audio amplifier: a036 a2bb intr type";
CM_ SG_ 1360 ADSP_a036_a2bbFaultType "Audio amplifier: a036 a2bb fault type";
CM_ SG_ 1360 ADSP_a050_open_load "Audio amplifier: a050 open load";
CM_ SG_ 1360 ADSP_a050_short_vcc "Audio amplifier: a050 short vcc";
CM_ SG_ 1360 ADSP_a050_short_gnd "Audio amplifier: a050 short gnd";
CM_ SG_ 1360 ADSP_a050_short_load "Audio amplifier: a050 short load";
CM_ SG_ 1360 ADSP_a050_diag_failed_to_start "Audio amplifier: a050 diag failed to start";
CM_ SG_ 1360 ADSP_a050_diag_failed "Audio amplifier: a050 diag failed";
CM_ SG_ 1360 ADSP_a053_audioSystemUnavailable "Audio amplifier: a053 audio system unavailable";
CM_ SG_ 1360 ADSP_a066_open_load "Audio amplifier: a066 open load";
CM_ SG_ 1360 ADSP_a066_short_vcc "Audio amplifier: a066 short vcc";
CM_ SG_ 1360 ADSP_a066_short_gnd "Audio amplifier: a066 short gnd";
CM_ SG_ 1360 ADSP_a066_short_load "Audio amplifier: a066 short load";
CM_ SG_ 1360 ADSP_a066_diag_failed_to_start "Audio amplifier: a066 diag failed to start";
CM_ SG_ 1360 ADSP_a066_diag_failed "Audio amplifier: a066 diag failed";
CM_ SG_ 1360 ADSP_a067_baseamp0Fault "Audio amplifier: a067 baseamp0 fault";
CM_ SG_ 1360 ADSP_a067_baseamp0Temp "Audio amplifier: a067 baseamp0 temp";
CM_ SG_ 1360 ADSP_a068_baseamp1Fault "Audio amplifier: a068 baseamp1 fault";
CM_ SG_ 1360 ADSP_a068_baseamp1Temp "Audio amplifier: a068 baseamp1 temp";
CM_ SG_ 1360 ADSP_a069_baseamp2Fault "Audio amplifier: a069 baseamp2 fault";
CM_ SG_ 1360 ADSP_a069_baseamp2Temp "Audio amplifier: a069 baseamp2 temp";
CM_ SG_ 1360 ADSP_a070_baseamp3Fault "Audio amplifier: a070 baseamp3 fault";
CM_ SG_ 1360 ADSP_a070_baseamp3Temp "Audio amplifier: a070 baseamp3 temp";
CM_ SG_ 1360 ADSP_a071_versionMismatch "Audio amplifier: a071 version mismatch";
CM_ SG_ 1360 ADSP_a080_micInitError "Audio amplifier: a080 mic init error";
CM_ BO_ 1361 "Audio amplifier message: alert matrix1";
CM_ SG_ 1361 ADSP_w001_flashInit "Audio amplifier: w001 flash init";
CM_ SG_ 1361 ADSP_w002_exception "Audio amplifier: w002 exception";
CM_ SG_ 1361 ADSP_w003_assert "Audio amplifier: w003 assert";
CM_ SG_ 1361 ADSP_w004_malloc "Audio amplifier: w004 malloc";
CM_ SG_ 1361 ADSP_w005_stackOverflow "Audio amplifier: w005 stack overflow";
CM_ SG_ 1361 ADSP_w006_eavbSeqno "Audio amplifier: w006 eavb seqno";
CM_ SG_ 1361 ADSP_w007_ethLinkErr "Audio amplifier: w007 eth link err";
CM_ SG_ 1361 ADSP_w008_internalTempHigh "Audio amplifier: w008 internal temp high";
CM_ SG_ 1361 ADSP_w010_12vAudioFiltLow "Audio amplifier: w010 12v audio filt low";
CM_ SG_ 1361 ADSP_w011_armHighCpuUsage "Audio amplifier: w011 arm high cpu usage";
CM_ SG_ 1361 ADSP_w012_sharc0HighCpuUsage "Audio amplifier: w012 sharc0 high cpu usage";
CM_ SG_ 1361 ADSP_w013_sharc1HighCpuUsage "Audio amplifier: w013 sharc1 high cpu usage";
CM_ SG_ 1361 ADSP_w014_eavbOverrun "Audio amplifier: w014 eavb overrun";
CM_ SG_ 1361 ADSP_w015_eavbUnderrun "Audio amplifier: w015 eavb underrun";
CM_ SG_ 1361 ADSP_w016_usbRxOverrun "Audio amplifier: w016 usb rx overrun";
CM_ SG_ 1361 ADSP_w017_usbRxUnderrun "Audio amplifier: w017 usb rx underrun";
CM_ SG_ 1361 ADSP_w018_usbTxOverrun "Audio amplifier: w018 usb tx overrun";
CM_ SG_ 1361 ADSP_w019_usbTxUnderrun "Audio amplifier: w019 usb tx underrun";
CM_ SG_ 1361 ADSP_w020_usbTxFailed "Audio amplifier: w020 usb tx failed";
CM_ SG_ 1361 ADSP_w021_usbTxAborted "Audio amplifier: w021 usb tx aborted";
CM_ SG_ 1361 ADSP_w022_emacErr "Audio amplifier: w022 emac err";
CM_ SG_ 1361 ADSP_w023_ethEtharpErr "Audio amplifier: w023 eth etharp err";
CM_ SG_ 1361 ADSP_w024_ethIpfragErr "Audio amplifier: w024 eth ipfrag err";
CM_ SG_ 1361 ADSP_w025_ethIpErr "Audio amplifier: w025 eth ip err";
CM_ SG_ 1361 ADSP_w026_ethIcmpErr "Audio amplifier: w026 eth icmp err";
CM_ SG_ 1361 ADSP_w027_ethUdpErr "Audio amplifier: w027 eth udp err";
CM_ SG_ 1361 ADSP_w028_ethTcpErr "Audio amplifier: w028 eth tcp err";
CM_ SG_ 1361 ADSP_w029_baseamp0SmFault "Audio amplifier: w029 baseamp0 sm fault";
CM_ SG_ 1361 ADSP_w030_ethSysErr "Audio amplifier: w030 eth sys err";
CM_ SG_ 1361 ADSP_w031_baseamp1SmFault "Audio amplifier: w031 baseamp1 sm fault";
CM_ SG_ 1361 ADSP_w032_baseamp2SmFault "Audio amplifier: w032 baseamp2 sm fault";
CM_ SG_ 1361 ADSP_w033_a2baDiscoveryFailed "Audio amplifier: w033 a2ba discovery failed";
CM_ SG_ 1361 ADSP_w034_a2bbDiscoveryFailed "Audio amplifier: w034 a2bb discovery failed";
CM_ SG_ 1361 ADSP_w035_a2baFault "Audio amplifier: w035 a2ba fault";
CM_ SG_ 1361 ADSP_w036_a2bbFault "Audio amplifier: w036 a2bb fault";
CM_ SG_ 1361 ADSP_w037_a2baIdleFailed "Audio amplifier: w037 a2ba idle failed";
CM_ SG_ 1361 ADSP_w038_a2bbIdleFailed "Audio amplifier: w038 a2bb idle failed";
CM_ SG_ 1361 ADSP_w039_ancPing "Audio amplifier: w039 anc ping";
CM_ SG_ 1361 ADSP_w040_socSciHeartbeat "Audio amplifier: w040 soc sci heartbeat";
CM_ SG_ 1361 ADSP_w041_twiWriteError "Audio amplifier: w041 twi write error";
CM_ SG_ 1361 ADSP_w042_twiReadError "Audio amplifier: w042 twi read error";
CM_ SG_ 1361 ADSP_w043_aweControlError "Audio amplifier: w043 awe control error";
CM_ SG_ 1361 ADSP_w044_canethChecksum "Audio amplifier: w044 caneth checksum";
CM_ SG_ 1361 ADSP_w045_ancEnableFail "Audio amplifier: w045 anc enable fail";
CM_ SG_ 1361 ADSP_w046_sharc0AweFrameOverload "Audio amplifier: w046 sharc0 awe frame overload";
CM_ SG_ 1361 ADSP_w047_sharc1AweFrameOverload "Audio amplifier: w047 sharc1 awe frame overload";
CM_ SG_ 1361 ADSP_w048_eCallSelfTestFailed "Audio amplifier: w048 e call self test failed";
CM_ SG_ 1361 ADSP_w049_sae "Audio amplifier: w049 sae";
CM_ SG_ 1361 ADSP_w050_extSpkFault "Audio amplifier: w050 ext spk fault";
CM_ SG_ 1361 ADSP_w051_extspkFailure "Audio amplifier: w051 extspk failure";
CM_ SG_ 1361 ADSP_w052_criticalReset "Audio amplifier: w052 critical reset";
CM_ SG_ 1361 ADSP_w053_audioSystemUnavailable "Audio amplifier: w053 audio system unavailable";
CM_ SG_ 1361 ADSP_w054_canethRxError "Audio amplifier: w054 caneth rx error";
CM_ SG_ 1361 ADSP_w055_hfpMathExcept1NAN "Audio amplifier: w055 hfp math except1 NAN";
CM_ SG_ 1361 ADSP_w056_hfpMathExcept1INF "Audio amplifier: w056 hfp math except1 INF";
CM_ SG_ 1361 ADSP_w057_hfpMathExcept2NAN "Audio amplifier: w057 hfp math except2 NAN";
CM_ SG_ 1361 ADSP_w058_hfpMathExcept2INF "Audio amplifier: w058 hfp math except2 INF";
CM_ SG_ 1361 ADSP_w059_nvmmError "Audio amplifier: w059 nvmm error";
CM_ SG_ 1361 ADSP_w060_baseamp3SmFault "Audio amplifier: w060 baseamp3 sm fault";
CM_ SG_ 1361 ADSP_w061_tcuGpioServiceError "Audio amplifier: w061 tcu gpio service error";
CM_ BO_ 1362 "Audio amplifier message: alert matrix2";
CM_ SG_ 1362 ADSP_w065_tcuGpioExpanderCritica "Audio amplifier: w065 tcu gpio expander critical error";
CM_ SG_ 1362 ADSP_w066_rearPwsFault "Audio amplifier: w066 rear pws fault";
CM_ SG_ 1362 ADSP_w067_baseamp0Fault "Audio amplifier: w067 baseamp0 fault";
CM_ SG_ 1362 ADSP_w068_baseamp1Fault "Audio amplifier: w068 baseamp1 fault";
CM_ SG_ 1362 ADSP_w069_baseamp2Fault "Audio amplifier: w069 baseamp2 fault";
CM_ SG_ 1362 ADSP_w070_baseamp3Fault "Audio amplifier: w070 baseamp3 fault";
CM_ SG_ 1362 ADSP_w071_versionMismatch "Audio amplifier: w071 version mismatch";
CM_ SG_ 1362 ADSP_w072_turnSignalChannelUnder "Audio amplifier: w072 turn signal channel underrun";
CM_ SG_ 1362 ADSP_w073_romFLError "Audio amplifier: w073 rom FL error";
CM_ SG_ 1362 ADSP_w074_tdspArmXrun "Audio amplifier: w074 tdsp arm xrun";
CM_ SG_ 1362 ADSP_w075_tdspArmError "Audio amplifier: w075 tdsp arm error";
CM_ SG_ 1362 ADSP_w076_activeSafetyChannelUnd "Audio amplifier: w076 active safety channel underrun";
CM_ SG_ 1362 ADSP_w077_mediaMathExcept "Audio amplifier: w077 media math except";
CM_ SG_ 1362 ADSP_w080_micInitError "Audio amplifier: w080 mic init error";
CM_ SG_ 1362 ADSP_w083_sharc0LowCpuUsage "Audio amplifier: w083 sharc0 low cpu usage";
CM_ SG_ 1362 ADSP_w084_sharc1LowCpuUsage "Audio amplifier: w084 sharc1 low cpu usage";
CM_ BO_ 1951 "Audio amplifier message: audio visualizer";
CM_ SG_ 1951 ADSP_audioVisualizerBrightness "Audio amplifier: audio visualizer brightness";
CM_ BO_ 1383 "Audio amplifier message: state";
CM_ SG_ 1383 ADSP_a2baState "Reports the state of the Automotive Audio Bus A (A2B-A) network.";
CM_ SG_ 1383 ADSP_a2bbState "Reports the state of the Automotive Audio Bus B (A2B-B) network.";
CM_ SG_ 1383 ADSP_baseamp0State "Audio amplifier: baseamp0 state";
CM_ SG_ 1383 ADSP_baseamp1State "Audio amplifier: baseamp1 state";
CM_ SG_ 1383 ADSP_baseamp2State "Audio amplifier: baseamp2 state";
CM_ SG_ 1383 ADSP_baseamp3State "Audio amplifier: baseamp3 state";
CM_ SG_ 1383 ADSP_audioReady "Audio is ready";
CM_ SG_ 1383 ADSP_extSpkCheckRan "True once the external speaker diagnostic check (check_diag_result) has run on this boot. Stays false on platforms without CONFIG_EXTSPK_CHECK.";
CM_ SG_ 1383 ADSP_tcuI2SEnabled "Reports whether the Telematics Control Unit (TCU) Integrated-circuit Sound (I2S) clock is enabled.";
CM_ SG_ 1383 ADSP_telephonyRxMute "Reports the telephony receive mute status.";
CM_ SG_ 1383 ADSP_ancState "Reports the state of the Active Noise Canceling (ANC) Digital Signal Processing (DSP).";
CM_ SG_ 1383 ADSP_sourceSelect "Reports the current audio source.";
CM_ SG_ 1383 ADSP_tunerSelect "Audio amplifier: tuner select";
CM_ SG_ 1383 ADSP_ancMode "Reports the Active Noise Cancelling (ANC) mode.";
CM_ SG_ 1383 ADSP_spkMuteAll "Reports when all audio speakers are muted.";
CM_ SG_ 1383 ADSP_eCall_ENS_state "ADSP-ECALL-ENS state";
CM_ SG_ 1383 ADSP_eCallSelfTest "eCall seft-test result";
CM_ SG_ 1383 ADSP_eCallState "eCall State";
CM_ SG_ 1383 ADSP_allAudioReady "Reports when all audio peripherals are ready.";
CM_ SG_ 1383 ADSP_callState "Reports the current call state.";
CM_ SG_ 1383 ADSP_telephonyTxMute "Reports the telephony transmit mute status.";
CM_ SG_ 1383 ADSP_eCallMicrophoneStatus "status of microphone";
CM_ SG_ 1383 ADSP_eCallSpeakerStatus "status of eCall speakers";
CM_ SG_ 1383 ADSP_a2baLoadShedded "Audio amplifier: a2ba load shedded";
CM_ SG_ 1383 ADSP_requestFailoverSpeaker "Reports requests for failover speaker for chimes.";
CM_ SG_ 1383 ADSP_microphoneDataState "Audio amplifier: microphone data state";
CM_ BO_ 600 "APB ECU message: status";
CM_ SG_ 600 APB_watchdogState "State of system watchdog on ParkerB; raw 7 = signal not available (SNA)";
CM_ SG_ 600 APB_fusedState "APB ECU: fused state; raw 3 = signal not available (SNA)";
CM_ SG_ 600 APB_cameraHeaterRequest "Indicates if heater grid is active because of request from Autopilot (AP) cameras.";
CM_ SG_ 600 APB_factorySummonStatus "APB ECU: factory summon status; raw 0 = signal not available (SNA)";
CM_ SG_ 600 APB_clipRecordingStatus "APB ECU: clip recording status";
CM_ SG_ 600 APB_summonUnavailableReason "Reports the reason why smart summon is currently unavailable.";
CM_ SG_ 600 APB_fsdSuspendState "APB ECU: fsd suspend state; raw 3 = signal not available (SNA)";
CM_ SG_ 600 APB_fsdRevokeStrikeoutCount "APB ECU: fsd revoke strikeout count; raw 7 = signal not available (SNA)";
CM_ SG_ 600 APB_teslaVisionSupported "APB ECU: tesla vision supported; raw 3 = signal not available (SNA)";
CM_ SG_ 600 APB_teslaVisionUnsupportedReason "APB ECU: tesla vision unsupported reason";
CM_ SG_ 600 APB_fsdRevokeCount "APB ECU: fsd revoke count; raw 7 = signal not available (SNA)";
CM_ SG_ 600 APB_excessiveAccelPedalWarning "Indicates that driver is using acceleration pedal continuously and excessively.";
CM_ SG_ 600 APB_unifiedObjectStackSupported "APB ECU: unified object stack supported; raw 3 = signal not available (SNA)";
CM_ SG_ 600 APB_sendingBUCStream "Indicates if the backup camera stream is being sent to the Media Control Unit (MCU) from Turbo A.";
CM_ SG_ 600 APB_DDAWSystemStatus "Reports the Driver Drowsiness and Attention Warning (DDAW) system status; raw 4 = signal not available (SNA)";
CM_ SG_ 600 APB_socOperatingMode "Reports the operating mode of the System on Chip (SoC).";
CM_ SG_ 600 APB_summonVersionIdentifier "APB ECU: summon version identifier";
CM_ SG_ 600 APB_sentryState "Reports the Sentry mode state on Hardware 4 (HW4) and later vehicles; raw 6 = signal not available (SNA)";
CM_ SG_ 600 APB_autoparkVersionIdentifier "Indicates which version of autopark will actively control the vehicle during user interactions.";
CM_ SG_ 600 APB_autonomySystemHealth "APB ECU: autonomy system health";
CM_ SG_ 600 APB_suspendResumeAvailable "APB ECU: suspend resume available";
CM_ SG_ 600 APB_statusCounter "APB ECU: status counter";
CM_ SG_ 600 APB_statusChecksum "APB ECU: status checksum";
CM_ BO_ 909 "Driver assistance computer (primary) message: VC info message";
CM_ SG_ 909 APP_inTunnel "Driver assistance computer (primary): in tunnel; raw 0 = signal not available (SNA)";
CM_ SG_ 909 APP_windshieldHeaterOnReason "Reports the reason why Autopilot (AP) is turning windshield heater on; raw 0 = signal not available (SNA)";
CM_ SG_ 909 APP_selfieCameraBlocked "Indicates if the selfie camera is currently blocked, or if this selfie camera model doesn't report lux; raw 0 = signal not available (SNA)";
CM_ SG_ 909 APP_selfieCameraLUX "Reports lux reading. Note that selfie camera lux is not currently calibrated against other cameras so the range is different; raw 255 = signal not available (SNA)";
CM_ SG_ 909 APP_sceneTagClearlyRaining "Indicates if the vision scene tag is clearly raining; raw 0 = signal not available (SNA)";
CM_ SG_ 909 APP_sceneTagFog "Indicates if the vision scene tag detects fog; raw 0 = signal not available (SNA)";
CM_ SG_ 909 APP_sceneTagFullyBlocked "Indicates if the vision scene tag detects a fully blocked view; raw 0 = signal not available (SNA)";
CM_ SG_ 909 APP_sceneTagIndoors "Indicates if the vision scene tag detects an indoor environment; raw 0 = signal not available (SNA)";
CM_ SG_ 909 APP_sceneTagLensFlare "Indicates if the vision scene tag detects lens flare; raw 0 = signal not available (SNA)";
CM_ SG_ 909 APP_sceneTagRaining "Indicates if the vision scene tag detects raining conditions; raw 0 = signal not available (SNA)";
CM_ SG_ 909 APP_sceneTagSevereWeather "Indicates if the vision scene tag detects severe weather conditions; raw 0 = signal not available (SNA)";
CM_ SG_ 909 APP_sceneTagSnowing "Indicates if the vision scene tag detects snowing conditions; raw 0 = signal not available (SNA)";
CM_ SG_ 909 APP_sceneTagSnowyRoad "Indicates if the vision scene tag detects snowy road conditions; raw 0 = signal not available (SNA)";
CM_ SG_ 909 APP_sceneTagSunGlare "Indicates if the vision scene tag detects sun glare conditions; raw 0 = signal not available (SNA)";
CM_ SG_ 909 APP_sceneTagTunnel "Indicates if the vision scene tag detects a tunnel environment; raw 0 = signal not available (SNA)";
CM_ SG_ 909 APP_sceneTagWetRoad "Indicates if the vision scene tag detects wet road conditions; raw 0 = signal not available (SNA)";
CM_ SG_ 909 APP_fisheyeInPathVisibility "Driver assistance computer (primary): fisheye in path visibility; raw 0 = signal not available (SNA)";
CM_ SG_ 909 APP_fisheyeOverallVisibility "Driver assistance computer (primary): fisheye overall visibility; raw 0 = signal not available (SNA)";
CM_ SG_ 909 APP_mainInPathVisibility "Driver assistance computer (primary): main in path visibility; raw 0 = signal not available (SNA)";
CM_ SG_ 909 APP_mainOverallVisibility "Driver assistance computer (primary): main overall visibility; raw 0 = signal not available (SNA)";
CM_ SG_ 909 APP_narrowInPathVisibility "Driver assistance computer (primary): narrow in path visibility; raw 0 = signal not available (SNA)";
CM_ SG_ 909 APP_narrowOverallVisibility "Driver assistance computer (primary): narrow overall visibility; raw 0 = signal not available (SNA)";
CM_ SG_ 909 APP_frontCamOcclusionType "Reports the current type of what is obstructing the front camera vision.";
CM_ BO_ 1513 "Driver assistance computer (primary) message: alert log";
CM_ SG_ 1513 APP_alertID "Driver assistance computer (primary): alert ID";
CM_ SG_ 1513 APP_alertSource "Driver assistance computer (primary): alert source";
CM_ SG_ 1513 APP_alertState "Driver assistance computer (primary): alert state";
CM_ SG_ 1513 APP_sw004_radIssue "Driver assistance computer (primary): sw004 rad issue";
CM_ SG_ 1513 APP_sw004_radHWFailure "Driver assistance computer (primary): sw004 rad HW failure";
CM_ SG_ 1513 APP_sw004_radSensorBlind "Driver assistance computer (primary): sw004 rad sensor blind";
CM_ SG_ 1513 APP_sw004_radSGUFailure "Driver assistance computer (primary): sw004 rad SGU failure";
CM_ SG_ 1513 APP_sw004_radMia "Driver assistance computer (primary): sw004 rad mia";
CM_ SG_ 1513 APP_sw004_radDynamicsError "Driver assistance computer (primary): sw004 rad dynamics error";
CM_ SG_ 1513 APP_sw004_espMIA "Driver assistance computer (primary): sw004 esp MIA";
CM_ SG_ 1513 APP_sw004_accState "Driver assistance computer (primary): sw004 acc state";
CM_ SG_ 1513 APP_sw004_appMobileyeStatus "Driver assistance computer (primary): sw004 app mobileye status";
CM_ SG_ 1513 APP_sw004_diCruiseStateFault "Driver assistance computer (primary): sw004 di cruise state fault";
CM_ SG_ 1513 APP_sw004_diMIA "Driver assistance computer (primary): sw004 di MIA";
CM_ SG_ 1513 APP_sw004_accelPedalInvalid "Driver assistance computer (primary): sw004 accel pedal invalid";
CM_ SG_ 1513 APP_sw004_stwAngleInvalid "Driver assistance computer (primary): sw004 stw angle invalid";
CM_ SG_ 1513 APP_sw004_accelerationInvalid "Driver assistance computer (primary): sw004 acceleration invalid";
CM_ SG_ 1513 APP_sw004_diSpeedInvalid "Driver assistance computer (primary): sw004 di speed invalid";
CM_ SG_ 1513 APP_sw004_DASFeaturesDisabled "Driver assistance computer (primary): sw004 DAS features disabled";
CM_ SG_ 1513 APP_sw004_appMobileyeNotInVision "Driver assistance computer (primary): sw004 app mobileye not in vision";
CM_ SG_ 1513 APP_sw004_CamCommonMIA "Driver assistance computer (primary): sw004 cam common MIA";
CM_ SG_ 1513 APP_sw004_CamObjectsMIA "Driver assistance computer (primary): sw004 cam objects MIA";
CM_ SG_ 1513 APP_sw004_CamWatchdog "Driver assistance computer (primary): sw004 cam watchdog";
CM_ SG_ 1513 APP_sw004_RadarLowVisibility "Driver assistance computer (primary): sw004 radar low visibility";
CM_ SG_ 1513 APP_sw004_RadarMisalignment "Driver assistance computer (primary): sw004 radar misalignment";
CM_ SG_ 1513 APP_sw004_OutOfFocusImage "Driver assistance computer (primary): sw004 out of focus image";
CM_ SG_ 1513 APP_sw004_ImpairedVD "Driver assistance computer (primary): sw004 impaired VD";
CM_ SG_ 1513 APP_sw004_SunRay "Driver assistance computer (primary): sw004 sun ray";
CM_ SG_ 1513 APP_sw004_Splashes "Driver assistance computer (primary): sw004 splashes";
CM_ SG_ 1513 APP_sw004_BlurredImage "Driver assistance computer (primary): sw004 blurred image";
CM_ SG_ 1513 APP_sw004_LowSun "Driver assistance computer (primary): sw004 low sun";
CM_ SG_ 1513 APP_sw004_SmearedSpots "Driver assistance computer (primary): sw004 smeared spots";
CM_ SG_ 1513 APP_sw004_PartialBlockage "Driver assistance computer (primary): sw004 partial blockage";
CM_ SG_ 1513 APP_sw004_AutofixOutOfCalib "Driver assistance computer (primary): sw004 autofix out of calib";
CM_ SG_ 1513 APP_sw004_AutofixOutOfCalibHorzn "Driver assistance computer (primary): sw004 autofix out of calib horzn";
CM_ SG_ 1513 APP_sw004_AutofixOutOfCalibYaw "Driver assistance computer (primary): sw004 autofix out of calib yaw";
CM_ SG_ 1513 APP_sw004_FullBlockage "Driver assistance computer (primary): sw004 full blockage";
CM_ SG_ 1513 APP_sw004_SmearedHalos "Driver assistance computer (primary): sw004 smeared halos";
CM_ SG_ 1513 APP_sw004_FoggyLights "Driver assistance computer (primary): sw004 foggy lights";
CM_ SG_ 1513 APP_sw004_SelfGlare "Driver assistance computer (primary): sw004 self glare";
CM_ SG_ 1513 APP_sw004_visionNotRunning "Driver assistance computer (primary): sw004 vision not running";
CM_ SG_ 1513 APP_sw009_DIaebState_fault "Driver assistance computer (primary): sw009 d iaeb state fault";
CM_ SG_ 1513 APP_sw009_DI_aeb_unresponsive "Driver assistance computer (primary): sw009 DI aeb unresponsive";
CM_ SG_ 1513 APP_sw009_DI_MIA "Driver assistance computer (primary): sw009 DI MIA";
CM_ SG_ 1513 APP_sw009_SCCM_MIA "Driver assistance computer (primary): sw009 SCCM MIA";
CM_ SG_ 1513 APP_sw009_CameraStream_fault "Driver assistance computer (primary): sw009 camera stream fault";
CM_ SG_ 1513 APP_sw010_a04calibNotDone "Driver assistance computer (primary): sw010 a04calib not done";
CM_ SG_ 1513 APP_sw010_a05calibReqd "Driver assistance computer (primary): sw010 a05calib reqd";
CM_ SG_ 1513 APP_sw010_a06calibNotOK "Driver assistance computer (primary): sw010 a06calib not OK";
CM_ SG_ 1513 APP_sw010_a08PlantMode "Driver assistance computer (primary): sw010 a08 plant mode";
CM_ SG_ 1513 APP_sw010_HorizontalMisalignment "Driver assistance computer (primary): sw010 horizontal misalignment";
CM_ SG_ 1513 APP_sw010_VerticalMisalignment "Driver assistance computer (primary): sw010 vertical misalignment";
CM_ SG_ 1513 APP_sw010_unusedBits "Driver assistance computer (primary): sw010 unused bits";
CM_ SG_ 1513 APP_sw010_VmaPlausibility "Driver assistance computer (primary): sw010 vma plausibility";
CM_ SG_ 1513 APP_sw011_scaState "Driver assistance computer (primary): sw011 sca state";
CM_ SG_ 1513 APP_sw011_scaLeft "Driver assistance computer (primary): sw011 sca left";
CM_ SG_ 1513 APP_sw011_scaRight "Driver assistance computer (primary): sw011 sca right";
CM_ SG_ 1513 APP_sw011_scaBlinker "Driver assistance computer (primary): sw011 sca blinker";
CM_ SG_ 1513 APP_sw011_scaThreshold "Driver assistance computer (primary): sw011 sca threshold";
CM_ SG_ 1513 APP_sw011_scaSpeed "Driver assistance computer (primary): sw011 sca speed";
CM_ SG_ 1513 APP_sw011_scaSonicDist "Driver assistance computer (primary): sw011 sca sonic dist";
CM_ SG_ 1513 APP_sw011_scaSteerAngle "Driver assistance computer (primary): sw011 sca steer angle";
CM_ SG_ 1513 APP_sw011_egoRightOfCenter "Driver assistance computer (primary): sw011 ego right of center";
CM_ SG_ 1513 APP_sw011_egoMovingRight "Driver assistance computer (primary): sw011 ego moving right";
CM_ SG_ 1513 APP_sw011_egoLeftOfCenter "Driver assistance computer (primary): sw011 ego left of center";
CM_ SG_ 1513 APP_sw011_egoMovingLeft "Driver assistance computer (primary): sw011 ego moving left";
CM_ SG_ 1513 APP_sw011_polyValid "Driver assistance computer (primary): sw011 poly valid";
CM_ SG_ 1513 APP_sw011_egoCentered "Driver assistance computer (primary): sw011 ego centered";
CM_ SG_ 1513 APP_sw011_scaReasonEldw "Driver assistance computer (primary): sw011 sca reason eldw";
CM_ SG_ 1513 APP_sw011_laneWidth "Driver assistance computer (primary): sw011 lane width";
CM_ SG_ 1513 APP_sw025_state_before_override "Driver assistance computer (primary): sw025 state before override";
CM_ SG_ 1513 APP_sw025_road_class "Driver assistance computer (primary): sw025 road class";
CM_ SG_ 1513 APP_sw025_road_match "Driver assistance computer (primary): sw025 road match";
CM_ SG_ 1513 APP_sw025_controlled_access "Driver assistance computer (primary): sw025 controlled access";
CM_ SG_ 1513 APP_sw025_leftLaneUsage "Driver assistance computer (primary): sw025 left lane usage";
CM_ SG_ 1513 APP_sw025_rightLaneUsage "Driver assistance computer (primary): sw025 right lane usage";
CM_ SG_ 1513 APP_sw025_vehiclesUsage "Driver assistance computer (primary): sw025 vehicles usage";
CM_ SG_ 1513 APP_sw025_hppUsage "Driver assistance computer (primary): sw025 hpp usage";
CM_ SG_ 1513 APP_sw025_navigationUsage "Driver assistance computer (primary): sw025 navigation usage";
CM_ SG_ 1513 APP_sw025_modelUsage "Driver assistance computer (primary): sw025 model usage";
CM_ SG_ 1513 APP_sw025_bottsDotsUsage "Driver assistance computer (primary): sw025 botts dots usage";
CM_ SG_ 1513 APP_sw025_offsetSide "Driver assistance computer (primary): sw025 offset side";
CM_ SG_ 1513 APP_sw025_torsionBarTorque "Driver assistance computer (primary): sw025 torsion bar torque";
CM_ SG_ 1513 APP_sw033_carConfig "Driver assistance computer (primary): sw033 car config";
CM_ SG_ 1513 APP_sw033_chNm "Driver assistance computer (primary): sw033 ch nm";
CM_ SG_ 1513 APP_sw033_gearControlVehBus "Driver assistance computer (primary): sw033 gear control veh bus";
CM_ SG_ 1513 APP_sw034_sccmMia "Driver assistance computer (primary): sw034 sccm mia";
CM_ SG_ 1513 APP_sw034_unusedByte "Driver assistance computer (primary): sw034 unused byte";
CM_ SG_ 1513 APP_sw034_unusedW0 "Driver assistance computer (primary): sw034 unused W0";
CM_ SG_ 1513 APP_sw034_unusedW1 "Driver assistance computer (primary): sw034 unused W1";
CM_ SG_ 1513 APP_sw035_status "Driver assistance computer (primary): sw035 status";
CM_ SG_ 1513 APP_sw035_wheelRotation "Driver assistance computer (primary): sw035 wheel rotation";
CM_ SG_ 1513 APP_sw035_wheelSpeeds "Driver assistance computer (primary): sw035 wheel speeds";
CM_ SG_ 1513 APP_sw035_redundantBrakingStatus "Driver assistance computer (primary): sw035 redundant braking status";
CM_ SG_ 1513 APP_sw040_accel_pedal_pos "Driver assistance computer (primary): sw040 accel pedal pos";
CM_ SG_ 1513 APP_sw040_ego_veh_speed "Driver assistance computer (primary): sw040 ego veh speed";
CM_ SG_ 1513 APP_sw040_das_steering_req "Driver assistance computer (primary): sw040 das steering req";
CM_ SG_ 1513 APP_sw040_epas_internal_sas "Driver assistance computer (primary): sw040 epas internal sas";
CM_ SG_ 1513 APP_sw040_torsion_bar_torque "Driver assistance computer (primary): sw040 torsion bar torque";
CM_ SG_ 1513 APP_sw040_view_range "Driver assistance computer (primary): sw040 view range";
CM_ SG_ 1513 APP_sw041_rate "Driver assistance computer (primary): sw041 rate";
CM_ SG_ 1513 APP_sw041_max_rate "Driver assistance computer (primary): sw041 max rate";
CM_ SG_ 1513 APP_sw041_ego_speed "Driver assistance computer (primary): sw041 ego speed";
CM_ SG_ 1513 APP_sw041_unusedW2 "Driver assistance computer (primary): sw041 unused W2";
CM_ SG_ 1513 APP_sw042_health_state "Driver assistance computer (primary): sw042 health state; raw 7 = signal not available (SNA)";
CM_ SG_ 1513 APP_sw042_abort_reason "Driver assistance computer (primary): sw042 abort reason";
CM_ SG_ 1513 APP_sw042_view_range "Driver assistance computer (primary): sw042 view range";
CM_ SG_ 1513 APP_sw042_state_before_abort "Driver assistance computer (primary): sw042 state before abort";
CM_ SG_ 1513 APP_sw042_epas_error_code "Driver assistance computer (primary): sw042 epas error code";
CM_ SG_ 1513 APP_sw042_cam_SunRay "Driver assistance computer (primary): sw042 cam sun ray";
CM_ SG_ 1513 APP_sw042_cam_RoadSpray "Driver assistance computer (primary): sw042 cam road spray";
CM_ SG_ 1513 APP_sw042_cam_BlurredImage "Driver assistance computer (primary): sw042 cam blurred image";
CM_ SG_ 1513 APP_sw042_cam_LowSun "Driver assistance computer (primary): sw042 cam low sun";
CM_ SG_ 1513 APP_sw042_cam_SmearedSpots "Driver assistance computer (primary): sw042 cam smeared spots";
CM_ SG_ 1513 APP_sw042_cam_PartialBlock "Driver assistance computer (primary): sw042 cam partial block";
CM_ SG_ 1513 APP_sw042_cam_Autofix "Driver assistance computer (primary): sw042 cam autofix";
CM_ SG_ 1513 APP_sw042_cam_AutofixHorizon "Driver assistance computer (primary): sw042 cam autofix horizon";
CM_ SG_ 1513 APP_sw042_cam_AutofixYaw "Driver assistance computer (primary): sw042 cam autofix yaw";
CM_ SG_ 1513 APP_sw042_cam_FullBlock "Driver assistance computer (primary): sw042 cam full block";
CM_ SG_ 1513 APP_sw042_cam_SmearedHalos "Driver assistance computer (primary): sw042 cam smeared halos";
CM_ SG_ 1513 APP_sw042_cam_FoggySpots "Driver assistance computer (primary): sw042 cam foggy spots";
CM_ SG_ 1513 APP_sw042_cam_SelfGlare "Driver assistance computer (primary): sw042 cam self glare";
CM_ SG_ 1513 APP_sw042_cam_OutofFocus "Driver assistance computer (primary): sw042 cam outof focus";
CM_ SG_ 1513 APP_sw042_road_match "Driver assistance computer (primary): sw042 road match";
CM_ SG_ 1513 APP_sw042_controlled_access "Driver assistance computer (primary): sw042 controlled access";
CM_ SG_ 1513 APP_sw042_road_class "Driver assistance computer (primary): sw042 road class";
CM_ SG_ 1513 APP_sw045_radcAlertMatrix "Driver assistance computer (primary): sw045 radc alert matrix";
CM_ SG_ 1513 APP_sw045_radcInfo "Driver assistance computer (primary): sw045 radc info";
CM_ SG_ 1513 APP_sw045_radcAccTargObj1A "Driver assistance computer (primary): sw045 radc acc targ obj1 a";
CM_ SG_ 1513 APP_sw045_lrrAlertMatrix0 "Driver assistance computer (primary): sw045 lrr alert matrix0";
CM_ SG_ 1513 APP_sw045_lrrPacketEnder "Driver assistance computer (primary): sw045 lrr packet ender";
CM_ SG_ 1513 APP_sw045_lrrRadarStatus "Driver assistance computer (primary): sw045 lrr radar status";
CM_ SG_ 1513 APP_sw045_lrrObj00A "Driver assistance computer (primary): sw045 lrr obj00 a";
CM_ SG_ 1513 APP_sw048_swAssert "Driver assistance computer (primary): sw048 sw assert";
CM_ SG_ 1513 APP_sw048_thermalIssue "Driver assistance computer (primary): sw048 thermal issue";
CM_ SG_ 1513 APP_sw048_powerIssue "Driver assistance computer (primary): sw048 power issue";
CM_ SG_ 1513 APP_sw048_stackOverflow "Driver assistance computer (primary): sw048 stack overflow";
CM_ SG_ 1513 APP_sw048_checkStop "Driver assistance computer (primary): sw048 check stop";
CM_ SG_ 1513 APP_sw048_ecuWatchdog "Driver assistance computer (primary): sw048 ecu watchdog";
CM_ SG_ 1513 APP_sw048_ecuReset "Driver assistance computer (primary): sw048 ecu reset";
CM_ SG_ 1513 APP_sw048_radcVersionMismatch "Driver assistance computer (primary): sw048 radc version mismatch";
CM_ SG_ 1513 APP_sw048_radcCalibration "Driver assistance computer (primary): sw048 radc calibration";
CM_ SG_ 1513 APP_sw048_radcMia "Driver assistance computer (primary): sw048 radc mia";
CM_ SG_ 1513 APP_sw048_eyeQVersionMismatch "Driver assistance computer (primary): sw048 eye q version mismatch";
CM_ SG_ 1513 APP_sw048_camIssue "Driver assistance computer (primary): sw048 cam issue";
CM_ SG_ 1513 APP_sw048_parkerIssue "Driver assistance computer (primary): sw048 parker issue";
CM_ SG_ 1513 APP_sw048_prolongedUiMia "Driver assistance computer (primary): sw048 prolonged ui mia";
CM_ SG_ 1513 APP_sw048_apImuNoise "Driver assistance computer (primary): sw048 ap imu noise";
CM_ SG_ 1513 APP_sw048_uiMiaAtBootup "Driver assistance computer (primary): sw048 ui mia at bootup";
CM_ SG_ 1513 APP_sw048_fisheyeNarrowSwap "Driver assistance computer (primary): sw048 fisheye narrow swap";
CM_ SG_ 1513 APP_sw048_pillarSwap "Driver assistance computer (primary): sw048 pillar swap";
CM_ SG_ 1513 APP_sw048_severeResidueDetected "Driver assistance computer (primary): sw048 severe residue detected";
CM_ SG_ 1513 APP_sw050_targetDist "Driver assistance computer (primary): sw050 target dist";
CM_ SG_ 1513 APP_sw050_targetRelSpeed "Driver assistance computer (primary): sw050 target rel speed";
CM_ SG_ 1513 APP_sw050_targetOverlap "Driver assistance computer (primary): sw050 target overlap";
CM_ SG_ 1513 APP_sw050_hostSpeed "Driver assistance computer (primary): sw050 host speed";
CM_ SG_ 1513 APP_sw050_hostLongAccel "Driver assistance computer (primary): sw050 host long accel";
CM_ SG_ 1513 APP_sw050_driverPressedAccelPed "Driver assistance computer (primary): sw050 driver pressed accel ped";
CM_ SG_ 1513 APP_sw050_driverPressedBrakePed "Driver assistance computer (primary): sw050 driver pressed brake ped";
CM_ SG_ 1513 APP_sw050_overrideAccelPed "Driver assistance computer (primary): sw050 override accel ped";
CM_ SG_ 1513 APP_sw050_overrideBlinker "Driver assistance computer (primary): sw050 override blinker";
CM_ SG_ 1513 APP_sw050_overrideBrake "Driver assistance computer (primary): sw050 override brake";
CM_ SG_ 1513 APP_sw050_overrideSteer "Driver assistance computer (primary): sw050 override steer";
CM_ SG_ 1513 APP_sw050_fcmModeAtEvent "Driver assistance computer (primary): sw050 fcm mode at event";
CM_ SG_ 1513 APP_sw050_accActive "Driver assistance computer (primary): sw050 acc active";
CM_ SG_ 1513 APP_sw051_a01ecuInternalPerf "Driver assistance computer (primary): sw051 a01ecu internal perf";
CM_ SG_ 1513 APP_sw051_a02flashPerformance "Driver assistance computer (primary): sw051 a02flash performance";
CM_ SG_ 1513 APP_sw051_a03vBatHigh "Driver assistance computer (primary): sw051 a03v bat high";
CM_ SG_ 1513 APP_sw051_a09configMismatch "Driver assistance computer (primary): sw051 a09config mismatch";
CM_ SG_ 1513 APP_sw051_a52radomeHtrInop "Driver assistance computer (primary): sw051 a52radome htr inop";
CM_ SG_ 1513 APP_sw051_unused "Driver assistance computer (primary): sw051 unused";
CM_ SG_ 1513 APP_sw051_SCUTemperature "Driver assistance computer (primary): sw051 SCU temperature";
CM_ SG_ 1513 APP_sw051_HWFail "Driver assistance computer (primary): sw051 HW fail";
CM_ SG_ 1513 APP_sw051_SGUFail "Driver assistance computer (primary): sw051 SGU fail";
CM_ SG_ 1513 APP_sw051_unusedBits "Driver assistance computer (primary): sw051 unused bits";
CM_ SG_ 1513 APP_sw051_unusedB0 "Driver assistance computer (primary): sw051 unused B0";
CM_ SG_ 1513 APP_sw051_unusedW1 "Driver assistance computer (primary): sw051 unused W1";
CM_ SG_ 1513 APP_sw052_a07sensorBlinded "Driver assistance computer (primary): sw052 a07sensor blinded";
CM_ SG_ 1513 APP_sw052_sensorDirty "Driver assistance computer (primary): sw052 sensor dirty";
CM_ SG_ 1513 APP_sw052_HWFail "Driver assistance computer (primary): sw052 HW fail";
CM_ SG_ 1513 APP_sw052_overTemperature "Driver assistance computer (primary): sw052 over temperature";
CM_ SG_ 1513 APP_sw052_underTemperature "Driver assistance computer (primary): sw052 under temperature";
CM_ SG_ 1513 APP_sw052_chirpError "Driver assistance computer (primary): sw052 chirp error";
CM_ SG_ 1513 APP_sw052_rspError "Driver assistance computer (primary): sw052 rsp error";
CM_ SG_ 1513 APP_sw052_sensorBlocked "Driver assistance computer (primary): sw052 sensor blocked";
CM_ SG_ 1513 APP_sw053_a10canBusOff "Driver assistance computer (primary): sw053 a10can bus off";
CM_ SG_ 1513 APP_sw053_a11bdyMIA "Driver assistance computer (primary): sw053 a11bdy MIA";
CM_ SG_ 1513 APP_sw053_a12espMIA "Driver assistance computer (primary): sw053 a12esp MIA";
CM_ SG_ 1513 APP_sw053_a13gtwMIA "Driver assistance computer (primary): sw053 a13gtw MIA";
CM_ SG_ 1513 APP_sw053_a14sccmMIA "Driver assistance computer (primary): sw053 a14sccm MIA";
CM_ SG_ 1513 APP_sw053_a15adasMIA "Driver assistance computer (primary): sw053 a15adas MIA";
CM_ SG_ 1513 APP_sw053_a16bdyInvalidCount "Driver assistance computer (primary): sw053 a16bdy invalid count";
CM_ SG_ 1513 APP_sw053_a17adasInvalidCount "Driver assistance computer (primary): sw053 a17adas invalid count";
CM_ SG_ 1513 APP_sw053_a18espInvalidCount "Driver assistance computer (primary): sw053 a18esp invalid count";
CM_ SG_ 1513 APP_sw053_a19sccmInvalidCount "Driver assistance computer (primary): sw053 a19sccm invalid count";
CM_ SG_ 1513 APP_sw053_a20bdyInvalidChkSm "Driver assistance computer (primary): sw053 a20bdy invalid chk sm";
CM_ SG_ 1513 APP_sw053_a21espInvalidChkSm "Driver assistance computer (primary): sw053 a21esp invalid chk sm";
CM_ SG_ 1513 APP_sw053_a22sccmInvalidChkSm "Driver assistance computer (primary): sw053 a22sccm invalid chk sm";
CM_ SG_ 1513 APP_sw053_a23sccmInvalidChkSm "Driver assistance computer (primary): sw053 a23sccm invalid chk sm";
CM_ SG_ 1513 APP_sw053_a24absValidity "Driver assistance computer (primary): sw053 a24abs validity";
CM_ SG_ 1513 APP_sw053_a25ambTValidity "Driver assistance computer (primary): sw053 a25amb t validity";
CM_ SG_ 1513 APP_sw053_a26brakeValidity "Driver assistance computer (primary): sw053 a26brake validity";
CM_ SG_ 1513 APP_sw053_a27CntryCdValidity "Driver assistance computer (primary): sw053 a27 cntry cd validity";
CM_ SG_ 1513 APP_sw053_a28espValidity "Driver assistance computer (primary): sw053 a28esp validity";
CM_ SG_ 1513 APP_sw053_a29longAccOffValidity "Driver assistance computer (primary): sw053 a29long acc off validity";
CM_ SG_ 1513 APP_sw053_a30longAccValidity "Driver assistance computer (primary): sw053 a30long acc validity";
CM_ SG_ 1513 APP_sw053_a31odoValidity "Driver assistance computer (primary): sw053 a31odo validity";
CM_ SG_ 1513 APP_sw053_a32gearValidity "Driver assistance computer (primary): sw053 a32gear validity";
CM_ SG_ 1513 APP_sw053_a33steerAngValidity "Driver assistance computer (primary): sw053 a33steer ang validity";
CM_ SG_ 1513 APP_sw053_a34steerAngSpdValidity "Driver assistance computer (primary): sw053 a34steer ang spd validity";
CM_ SG_ 1513 APP_sw053_a35indctrValidity "Driver assistance computer (primary): sw053 a35indctr validity";
CM_ SG_ 1513 APP_sw053_a36vehStndStllValidty "Driver assistance computer (primary): sw053 a36veh stnd stll validty";
CM_ SG_ 1513 APP_sw053_a37vinValidity "Driver assistance computer (primary): sw053 a37vin validity";
CM_ SG_ 1513 APP_sw053_a38whlRotValidity "Driver assistance computer (primary): sw053 a38whl rot validity";
CM_ SG_ 1513 APP_sw053_a39whlSpdValidity "Driver assistance computer (primary): sw053 a39whl spd validity";
CM_ SG_ 1513 APP_sw053_a40whlStndStllValidty "Driver assistance computer (primary): sw053 a40whl stnd stll validty";
CM_ SG_ 1513 APP_sw053_a41wiperValidity "Driver assistance computer (primary): sw053 a41wiper validity";
CM_ SG_ 1513 APP_sw053_a42xwdValidity "Driver assistance computer (primary): sw053 a42xwd validity";
CM_ SG_ 1513 APP_sw053_a43yawOffValidity "Driver assistance computer (primary): sw053 a43yaw off validity";
CM_ SG_ 1513 APP_sw053_a44yawValidity "Driver assistance computer (primary): sw053 a44yaw validity";
CM_ SG_ 1513 APP_sw053_a48steerAngOffSanity "Driver assistance computer (primary): sw053 a48steer ang off sanity";
CM_ SG_ 1513 APP_sw053_a49tireSizeSanity "Driver assistance computer (primary): sw053 a49tire size sanity";
CM_ SG_ 1513 APP_sw053_a50velocitySanity "Driver assistance computer (primary): sw053 a50velocity sanity";
CM_ SG_ 1513 APP_sw053_a51yawSanity "Driver assistance computer (primary): sw053 a51yaw sanity";
CM_ SG_ 1513 APP_sw053_a53espmodValidity "Driver assistance computer (primary): sw053 a53espmod validity";
CM_ SG_ 1513 APP_sw053_a54gtwmodValidity "Driver assistance computer (primary): sw053 a54gtwmod validity";
CM_ SG_ 1513 APP_sw053_a55stwmodValidity "Driver assistance computer (primary): sw053 a55stwmod validity";
CM_ SG_ 1513 APP_sw053_a56bcmodValidity "Driver assistance computer (primary): sw053 a56bcmod validity";
CM_ SG_ 1513 APP_sw053_a57dimodValidity "Driver assistance computer (primary): sw053 a57dimod validity";
CM_ SG_ 1513 APP_sw053_a59drmiInvalidChkSm "Driver assistance computer (primary): sw053 a59drmi invalid chk sm";
CM_ SG_ 1513 APP_sw053_a60drmiInvalidCount "Driver assistance computer (primary): sw053 a60drmi invalid count";
CM_ SG_ 1513 APP_sw053_a61radPositionMismatch "Driver assistance computer (primary): sw053 a61rad position mismatch";
CM_ SG_ 1513 APP_sw053_a62strRackMismatch "Driver assistance computer (primary): sw053 a62str rack mismatch";
CM_ SG_ 1513 APP_sw055_detectedRadcVersion "Driver assistance computer (primary): sw055 detected radc version";
CM_ SG_ 1513 APP_sw055_expectedCrcLsw "Driver assistance computer (primary): sw055 expected crc lsw";
CM_ SG_ 1513 APP_sw056_diMia "Driver assistance computer (primary): sw056 di mia";
CM_ SG_ 1513 APP_sw056_unusedByte "Driver assistance computer (primary): sw056 unused byte";
CM_ SG_ 1513 APP_sw056_unusedW0 "Driver assistance computer (primary): sw056 unused W0";
CM_ SG_ 1513 APP_sw056_unusedW1 "Driver assistance computer (primary): sw056 unused W1";
CM_ SG_ 1513 APP_sw058_epbMia "Driver assistance computer (primary): sw058 epb mia";
CM_ SG_ 1513 APP_sw058_unusedByte "Driver assistance computer (primary): sw058 unused byte";
CM_ SG_ 1513 APP_sw058_unusedW0 "Driver assistance computer (primary): sw058 unused W0";
CM_ SG_ 1513 APP_sw058_unusedW1 "Driver assistance computer (primary): sw058 unused W1";
CM_ SG_ 1513 APP_sw059_oloDict "Driver assistance computer (primary): sw059 olo dict";
CM_ SG_ 1513 APP_sw059_oocStatus "Driver assistance computer (primary): sw059 ooc status";
CM_ SG_ 1513 APP_sw059_pasFrontMiddle "Driver assistance computer (primary): sw059 pas front middle";
CM_ SG_ 1513 APP_sw059_pasRearMiddle "Driver assistance computer (primary): sw059 pas rear middle";
CM_ SG_ 1513 APP_sw059_pscStatus "Driver assistance computer (primary): sw059 psc status";
CM_ SG_ 1513 APP_sw059_pscVehSlot "Driver assistance computer (primary): sw059 psc veh slot";
CM_ SG_ 1513 APP_sw059_sdiFront "Driver assistance computer (primary): sw059 sdi front";
CM_ SG_ 1513 APP_sw059_sdiRear "Driver assistance computer (primary): sw059 sdi rear";
CM_ SG_ 1513 APP_sw059_sensorStatusFront "Driver assistance computer (primary): sw059 sensor status front";
CM_ SG_ 1513 APP_sw059_sensorStatusRear "Driver assistance computer (primary): sw059 sensor status rear";
CM_ SG_ 1513 APP_sw059_status2 "Driver assistance computer (primary): sw059 status2";
CM_ SG_ 1513 APP_sw059_status "Driver assistance computer (primary): sw059 status";
CM_ SG_ 1513 APP_sw061_states "Driver assistance computer (primary): sw061 states";
CM_ SG_ 1513 APP_sw061_axleData "Driver assistance computer (primary): sw061 axle data";
CM_ SG_ 1513 APP_sw061_dampingStates "Driver assistance computer (primary): sw061 damping states";
CM_ SG_ 1513 APP_sw061_speedBumpAttributes "Driver assistance computer (primary): sw061 speed bump attributes";
CM_ SG_ 1513 APP_sw063_expectedMajorVer "Driver assistance computer (primary): sw063 expected major ver";
CM_ SG_ 1513 APP_sw063_detectedMajorVer "Driver assistance computer (primary): sw063 detected major ver";
CM_ SG_ 1513 APP_sw063_expectedMinorVer "Driver assistance computer (primary): sw063 expected minor ver";
CM_ SG_ 1513 APP_sw063_detectedMinorVer "Driver assistance computer (primary): sw063 detected minor ver";
CM_ SG_ 1513 APP_sw063_expectedSubMinorVer "Driver assistance computer (primary): sw063 expected sub minor ver";
CM_ SG_ 1513 APP_sw063_detectedSubMinorVer "Driver assistance computer (primary): sw063 detected sub minor ver";
CM_ SG_ 1513 APP_sw064_sysStatus "Driver assistance computer (primary): sw064 sys status";
CM_ SG_ 1513 APP_sw064_status "Driver assistance computer (primary): sw064 status";
CM_ SG_ 1513 APP_sw073_escalateLDWs "Driver assistance computer (primary): sw073 escalate LD ws";
CM_ SG_ 1513 APP_sw073_silentEscalatedLDW "Driver assistance computer (primary): sw073 silent escalated LDW";
CM_ SG_ 1513 APP_sw073_escalateLDWreason "Driver assistance computer (primary): sw073 escalate LD wreason";
CM_ SG_ 1513 APP_sw073_rawMobileyeLDW "Driver assistance computer (primary): sw073 raw mobileye LDW";
CM_ SG_ 1513 APP_sw073_freespaceLDW "Driver assistance computer (primary): sw073 freespace LDW";
CM_ SG_ 1513 APP_sw073_freespaceLeftC0 "Driver assistance computer (primary): sw073 freespace left C0";
CM_ SG_ 1513 APP_sw073_freespaceRightC0 "Driver assistance computer (primary): sw073 freespace right C0";
CM_ SG_ 1513 APP_sw073_freespaceLeftC1 "Driver assistance computer (primary): sw073 freespace left C1";
CM_ SG_ 1513 APP_sw073_freespaceRightC1 "Driver assistance computer (primary): sw073 freespace right C1";
CM_ SG_ 1513 APP_sw073_freespaceLeftFarZ "Driver assistance computer (primary): sw073 freespace left far z";
CM_ SG_ 1513 APP_sw073_freespaceRightFarZ "Driver assistance computer (primary): sw073 freespace right far z";
CM_ SG_ 1513 APP_sw075_scMia "Driver assistance computer (primary): sw075 sc mia";
CM_ SG_ 1513 APP_sw075_unusedByte "Driver assistance computer (primary): sw075 unused byte";
CM_ SG_ 1513 APP_sw075_unusedW0 "Driver assistance computer (primary): sw075 unused W0";
CM_ SG_ 1513 APP_sw075_unusedW1 "Driver assistance computer (primary): sw075 unused W1";
CM_ SG_ 1513 APP_sw077_oocDistance "Driver assistance computer (primary): sw077 ooc distance";
CM_ SG_ 1513 APP_sw077_oocConfidence "Driver assistance computer (primary): sw077 ooc confidence";
CM_ SG_ 1513 APP_sw077_oocCollisionSide "Driver assistance computer (primary): sw077 ooc collision side";
CM_ SG_ 1513 APP_sw077_oocHeight "Driver assistance computer (primary): sw077 ooc height";
CM_ SG_ 1513 APP_sw077_vehicleSpeed "Driver assistance computer (primary): sw077 vehicle speed";
CM_ SG_ 1513 APP_sw077_oocUntrackedTime "Driver assistance computer (primary): sw077 ooc untracked time";
CM_ SG_ 1513 APP_sw077_oocOffCourseDist_cm "Driver assistance computer (primary): sw077 ooc off course dist cm";
CM_ SG_ 1513 APP_sw080_sensors_healty_check "Driver assistance computer (primary): sw080 sensors healty check";
CM_ SG_ 1513 APP_sw080_dist_travelled_check "Driver assistance computer (primary): sw080 dist travelled check";
CM_ SG_ 1513 APP_sw080_road_class_check "Driver assistance computer (primary): sw080 road class check";
CM_ SG_ 1513 APP_sw080_stw_angle_check "Driver assistance computer (primary): sw080 stw angle check";
CM_ SG_ 1513 APP_sw080_rad_tar_5_check "Driver assistance computer (primary): sw080 rad tar 5 check";
CM_ SG_ 1513 APP_sw080_ultrasonic_obs_check "Driver assistance computer (primary): sw080 ultrasonic obs check";
CM_ SG_ 1513 APP_sw080_freespace_check "Driver assistance computer (primary): sw080 freespace check";
CM_ SG_ 1513 APP_sw080_pedestrian_check "Driver assistance computer (primary): sw080 pedestrian check";
CM_ SG_ 1513 APP_sw080_rad_tar_5_dist "Driver assistance computer (primary): sw080 rad tar 5 dist";
CM_ SG_ 1513 APP_sw080_stw_angle_deg "Driver assistance computer (primary): sw080 stw angle deg";
CM_ SG_ 1513 APP_sw080_road_class "Driver assistance computer (primary): sw080 road class";
CM_ SG_ 1513 APP_sw080_ego_speed "Driver assistance computer (primary): sw080 ego speed";
CM_ SG_ 1513 APP_sw080_cipv_valid "Driver assistance computer (primary): sw080 cipv valid";
CM_ SG_ 1513 APP_sw080_min_speed_check "Driver assistance computer (primary): sw080 min speed check";
CM_ SG_ 1513 APP_sw080_cruise_lever_state "Driver assistance computer (primary): sw080 cruise lever state";
CM_ SG_ 1513 APP_sw080_cruise_speed_check "Driver assistance computer (primary): sw080 cruise speed check";
CM_ SG_ 1513 APP_sw081_radarDistance "Driver assistance computer (primary): sw081 radar distance";
CM_ SG_ 1513 APP_sw081_radarTTC "Driver assistance computer (primary): sw081 radar TTC";
CM_ SG_ 1513 APP_sw081_cameraDistance "Driver assistance computer (primary): sw081 camera distance";
CM_ SG_ 1513 APP_sw081_cameraTTC "Driver assistance computer (primary): sw081 camera TTC";
CM_ SG_ 1513 APP_sw081_pedalPosition "Driver assistance computer (primary): sw081 pedal position";
CM_ SG_ 1513 APP_sw129_mainCamExtNoCalFile "Driver assistance computer (primary): sw129 main cam ext no cal file";
CM_ SG_ 1513 APP_sw130_narrowCamExtNoCalFile "Driver assistance computer (primary): sw130 narrow cam ext no cal file";
CM_ SG_ 1513 APP_sw133_mainCamDeserFault "Driver assistance computer (primary): sw133 main cam deser fault";
CM_ SG_ 1513 APP_sw133_mainCamI2CbusFault "Driver assistance computer (primary): sw133 main cam I2 cbus fault";
CM_ SG_ 1513 APP_sw133_mainCamSensorFault "Driver assistance computer (primary): sw133 main cam sensor fault";
CM_ SG_ 1513 APP_sw133_mainCamSerFault "Driver assistance computer (primary): sw133 main cam ser fault";
CM_ SG_ 1513 APP_sw134_narrowCamDeserFault "Driver assistance computer (primary): sw134 narrow cam deser fault";
CM_ SG_ 1513 APP_sw134_narrowCamI2CbusFault "Driver assistance computer (primary): sw134 narrow cam I2 cbus fault";
CM_ SG_ 1513 APP_sw134_narrowCamSensorFault "Driver assistance computer (primary): sw134 narrow cam sensor fault";
CM_ SG_ 1513 APP_sw134_narrowCamSerFault "Driver assistance computer (primary): sw134 narrow cam ser fault";
CM_ SG_ 1513 APP_sw135_fisheyeCamDeserFault "Driver assistance computer (primary): sw135 fisheye cam deser fault";
CM_ SG_ 1513 APP_sw135_fisheyeCamI2CbusFault "Driver assistance computer (primary): sw135 fisheye cam I2 cbus fault";
CM_ SG_ 1513 APP_sw135_fisheyeCamSensorFault "Driver assistance computer (primary): sw135 fisheye cam sensor fault";
CM_ SG_ 1513 APP_sw135_fisheyeCamSerFault "Driver assistance computer (primary): sw135 fisheye cam ser fault";
CM_ SG_ 1513 APP_sw136_lPillarCamDeserFault "Driver assistance computer (primary): sw136 l pillar cam deser fault";
CM_ SG_ 1513 APP_sw136_lPillarCamI2CbusFault "Driver assistance computer (primary): sw136 l pillar cam I2 cbus fault";
CM_ SG_ 1513 APP_sw136_lPillarCamSensorFault "Driver assistance computer (primary): sw136 l pillar cam sensor fault";
CM_ SG_ 1513 APP_sw136_lPillarCamSerFault "Driver assistance computer (primary): sw136 l pillar cam ser fault";
CM_ SG_ 1513 APP_sw137_rPillarCamDeserFault "Driver assistance computer (primary): sw137 r pillar cam deser fault";
CM_ SG_ 1513 APP_sw137_rPillarCamI2CbusFault "Driver assistance computer (primary): sw137 r pillar cam I2 cbus fault";
CM_ SG_ 1513 APP_sw137_rPillarCamSensorFault "Driver assistance computer (primary): sw137 r pillar cam sensor fault";
CM_ SG_ 1513 APP_sw137_rPillarCamSerFault "Driver assistance computer (primary): sw137 r pillar cam ser fault";
CM_ SG_ 1513 APP_sw138_lRepeatCamDeserFault "Driver assistance computer (primary): sw138 l repeat cam deser fault";
CM_ SG_ 1513 APP_sw138_lRepeatCamI2CbusFault "Driver assistance computer (primary): sw138 l repeat cam I2 cbus fault";
CM_ SG_ 1513 APP_sw138_lRepeatCamSensorFault "Driver assistance computer (primary): sw138 l repeat cam sensor fault";
CM_ SG_ 1513 APP_sw138_lRepeatCamSerFault "Driver assistance computer (primary): sw138 l repeat cam ser fault";
CM_ SG_ 1513 APP_sw139_rRepeatCamDeserFault "Driver assistance computer (primary): sw139 r repeat cam deser fault";
CM_ SG_ 1513 APP_sw139_rRepeatCamI2CbusFault "Driver assistance computer (primary): sw139 r repeat cam I2 cbus fault";
CM_ SG_ 1513 APP_sw139_rRepeatCamSensorFault "Driver assistance computer (primary): sw139 r repeat cam sensor fault";
CM_ SG_ 1513 APP_sw139_rRepeatCamSerFault "Driver assistance computer (primary): sw139 r repeat cam ser fault";
CM_ SG_ 1513 APP_sw140_backupCamCSIBridgeFlt "Driver assistance computer (primary): sw140 backup cam CSI bridge flt";
CM_ SG_ 1513 APP_sw140_backupCamDeserFault "Driver assistance computer (primary): sw140 backup cam deser fault";
CM_ SG_ 1513 APP_sw140_backupCamI2CbusFault "Driver assistance computer (primary): sw140 backup cam I2 cbus fault";
CM_ SG_ 1513 APP_sw140_backupCamSensorFault "Driver assistance computer (primary): sw140 backup cam sensor fault";
CM_ SG_ 1513 APP_sw140_backupCamUARTbusFault "Driver assistance computer (primary): sw140 backup cam UAR tbus fault";
CM_ SG_ 1513 APP_sw140_backupCamSXDeserFailed "Driver assistance computer (primary): sw140 backup cam SX deser failed";
CM_ SG_ 1513 APP_sw140_backupCamDeserLock "Driver assistance computer (primary): sw140 backup cam deser lock";
CM_ SG_ 1513 APP_sw140_backupCamSerFault "Driver assistance computer (primary): sw140 backup cam ser fault";
CM_ SG_ 1513 APP_sw140_backupCamHDMISerFault "Driver assistance computer (primary): sw140 backup cam HDMI ser fault";
CM_ SG_ 1513 APP_sw141_maxThreshold "Driver assistance computer (primary): sw141 max threshold";
CM_ SG_ 1513 APP_sw141_minThreshold "Driver assistance computer (primary): sw141 min threshold";
CM_ SG_ 1513 APP_sw141_tempSensorId "Driver assistance computer (primary): sw141 temp sensor id";
CM_ SG_ 1513 APP_sw141_temperature "Driver assistance computer (primary): sw141 temperature";
CM_ SG_ 1513 APP_sw142_camExtPitchCal "Driver assistance computer (primary): sw142 cam ext pitch cal";
CM_ SG_ 1513 APP_sw142_pitchOffsetAtmptVal "Driver assistance computer (primary): sw142 pitch offset atmpt val";
CM_ SG_ 1513 APP_sw142_problemCamPosition "Driver assistance computer (primary): sw142 problem cam position";
CM_ SG_ 1513 APP_sw145_pitchSpike "Driver assistance computer (primary): sw145 pitch spike";
CM_ SG_ 1513 APP_sw145_yawSpike "Driver assistance computer (primary): sw145 yaw spike";
CM_ SG_ 1513 APP_sw145_rollSpike "Driver assistance computer (primary): sw145 roll spike";
CM_ SG_ 1513 APP_sw145_insaneCal "Driver assistance computer (primary): sw145 insane cal";
CM_ SG_ 1513 APP_sw145_problemSaving "Driver assistance computer (primary): sw145 problem saving";
CM_ SG_ 1513 APP_sw145_problemCamPosition "Driver assistance computer (primary): sw145 problem cam position";
CM_ SG_ 1513 APP_sw145_camExtPitchCal "Driver assistance computer (primary): sw145 cam ext pitch cal";
CM_ SG_ 1513 APP_sw145_camExtYawCal "Driver assistance computer (primary): sw145 cam ext yaw cal";
CM_ SG_ 1513 APP_sw145_camExtRollCal "Driver assistance computer (primary): sw145 cam ext roll cal";
CM_ SG_ 1513 APP_sw147_selfieCamDeserFault "Driver assistance computer (primary): sw147 selfie cam deser fault";
CM_ SG_ 1513 APP_sw147_selfieCamI2CbusFault "Driver assistance computer (primary): sw147 selfie cam I2 cbus fault";
CM_ SG_ 1513 APP_sw147_selfieCamSensorFault "Driver assistance computer (primary): sw147 selfie cam sensor fault";
CM_ SG_ 1513 APP_sw147_selfieCamSerFault "Driver assistance computer (primary): sw147 selfie cam ser fault";
CM_ SG_ 1513 APP_sw150_locStatus "Driver assistance computer (primary): sw150 loc status";
CM_ SG_ 1513 APP_sw150_speed "Driver assistance computer (primary): sw150 speed";
CM_ SG_ 1513 APP_sw150_systemStatus "Driver assistance computer (primary): sw150 system status";
CM_ SG_ 1513 APP_sw150_chassisControl "Driver assistance computer (primary): sw150 chassis control";
CM_ SG_ 1513 APP_sw150_locStatus2 "Driver assistance computer (primary): sw150 loc status2";
CM_ SG_ 1513 APP_sw150_autonomyHealth "Driver assistance computer (primary): sw150 autonomy health";
CM_ SG_ 1513 APP_sw150_chassisControl2 "Driver assistance computer (primary): sw150 chassis control2";
CM_ SG_ 1513 APP_sw151_sysStatus "Driver assistance computer (primary): sw151 sys status";
CM_ SG_ 1513 APP_sw151_status "Driver assistance computer (primary): sw151 status";
CM_ SG_ 1513 APP_sw152_status "Driver assistance computer (primary): sw152 status";
CM_ SG_ 1513 APP_sw152_wheelRotation "Driver assistance computer (primary): sw152 wheel rotation";
CM_ SG_ 1513 APP_sw152_wheelSpeeds "Driver assistance computer (primary): sw152 wheel speeds";
CM_ SG_ 1513 APP_sw153_inertial1 "Driver assistance computer (primary): sw153 inertial1";
CM_ SG_ 1513 APP_sw153_inertial2 "Driver assistance computer (primary): sw153 inertial2";
CM_ SG_ 1513 APP_sw153_inertial3 "Driver assistance computer (primary): sw153 inertial3";
CM_ SG_ 1513 APP_sw153_inertial4 "Driver assistance computer (primary): sw153 inertial4";
CM_ SG_ 1513 APP_sw154_restraintStatus "Driver assistance computer (primary): sw154 restraint status";
CM_ SG_ 1513 APP_sw154_doorStatus "Driver assistance computer (primary): sw154 door status";
CM_ SG_ 1513 APP_sw155_restraintStatus "Driver assistance computer (primary): sw155 restraint status";
CM_ SG_ 1513 APP_sw155_doorStatus "Driver assistance computer (primary): sw155 door status";
CM_ SG_ 1513 APP_sw156_status "Driver assistance computer (primary): sw156 status";
CM_ SG_ 1513 APP_sw156_autonomyHealth "Driver assistance computer (primary): sw156 autonomy health";
CM_ SG_ 1513 APP_sw157_leftStalk "Driver assistance computer (primary): sw157 left stalk";
CM_ SG_ 1513 APP_sw157_rightStalk "Driver assistance computer (primary): sw157 right stalk";
CM_ SG_ 1513 APP_sw157_steeringAngleSensor "Driver assistance computer (primary): sw157 steering angle sensor";
CM_ SG_ 1513 APP_sw158_lvPowerState "Driver assistance computer (primary): sw158 lv power state";
CM_ SG_ 1513 APP_sw158_vehicleStatus "Driver assistance computer (primary): sw158 vehicle status";
CM_ SG_ 1513 APP_sw158_status "Driver assistance computer (primary): sw158 status";
CM_ SG_ 1513 APP_sw158_lighting "Driver assistance computer (primary): sw158 lighting";
CM_ SG_ 1513 APP_sw158_LVHealth "Driver assistance computer (primary): sw158 LV health";
CM_ SG_ 1513 APP_sw158_sensors "Driver assistance computer (primary): sw158 sensors";
CM_ SG_ 1513 APP_sw158_coolant "Driver assistance computer (primary): sw158 coolant";
CM_ SG_ 1513 APP_sw159_doorStatus "Driver assistance computer (primary): sw159 door status";
CM_ SG_ 1513 APP_sw159_switchStatus "Driver assistance computer (primary): sw159 switch status";
CM_ SG_ 1513 APP_sw160_doorStatus "Driver assistance computer (primary): sw160 door status";
CM_ SG_ 1513 APP_sw160_thsStatus "Driver assistance computer (primary): sw160 ths status";
CM_ SG_ 1513 APP_sw160_hvacStatus "Driver assistance computer (primary): sw160 hvac status";
CM_ SG_ 1513 APP_sw160_switchStatus "Driver assistance computer (primary): sw160 switch status";
CM_ SG_ 1513 APP_sw161_frameTimeout "Driver assistance computer (primary): sw161 frame timeout";
CM_ SG_ 1513 APP_sw161_hdmiDisplayError "Driver assistance computer (primary): sw161 hdmi display error";
CM_ SG_ 1513 APP_sw161_rawImageTimeout "Driver assistance computer (primary): sw161 raw image timeout";
CM_ SG_ 1513 APP_sw161_imagerOutOfSpecTemp "Driver assistance computer (primary): sw161 imager out of spec temp";
CM_ SG_ 1513 APP_sw162_colorFilterMismatch "Driver assistance computer (primary): sw162 color filter mismatch";
CM_ SG_ 1513 APP_sw162_detectedColorFilter "Driver assistance computer (primary): sw162 detected color filter";
CM_ SG_ 1513 APP_sw162_expectedColorFilter "Driver assistance computer (primary): sw162 expected color filter";
CM_ SG_ 1513 APP_sw162_cameraPositionMismatch "Driver assistance computer (primary): sw162 camera position mismatch";
CM_ SG_ 1513 APP_sw162_blacklistedFuseID "Driver assistance computer (primary): sw162 blacklisted fuse ID";
CM_ SG_ 1513 APP_sw162_uuidMismatch "Driver assistance computer (primary): sw162 uuid mismatch";
CM_ SG_ 1513 APP_sw162_detectedPosition "Driver assistance computer (primary): sw162 detected position";
CM_ SG_ 1513 APP_sw163_colorFilterMismatch "Driver assistance computer (primary): sw163 color filter mismatch";
CM_ SG_ 1513 APP_sw163_detectedColorFilter "Driver assistance computer (primary): sw163 detected color filter";
CM_ SG_ 1513 APP_sw163_expectedColorFilter "Driver assistance computer (primary): sw163 expected color filter";
CM_ SG_ 1513 APP_sw163_cameraPositionMismatch "Driver assistance computer (primary): sw163 camera position mismatch";
CM_ SG_ 1513 APP_sw163_blacklistedFuseID "Driver assistance computer (primary): sw163 blacklisted fuse ID";
CM_ SG_ 1513 APP_sw163_uuidMismatch "Driver assistance computer (primary): sw163 uuid mismatch";
CM_ SG_ 1513 APP_sw163_detectedPosition "Driver assistance computer (primary): sw163 detected position";
CM_ SG_ 1513 APP_sw164_colorFilterMismatch "Driver assistance computer (primary): sw164 color filter mismatch";
CM_ SG_ 1513 APP_sw164_detectedColorFilter "Driver assistance computer (primary): sw164 detected color filter";
CM_ SG_ 1513 APP_sw164_expectedColorFilter "Driver assistance computer (primary): sw164 expected color filter";
CM_ SG_ 1513 APP_sw164_cameraPositionMismatch "Driver assistance computer (primary): sw164 camera position mismatch";
CM_ SG_ 1513 APP_sw164_blacklistedFuseID "Driver assistance computer (primary): sw164 blacklisted fuse ID";
CM_ SG_ 1513 APP_sw164_uuidMismatch "Driver assistance computer (primary): sw164 uuid mismatch";
CM_ SG_ 1513 APP_sw164_detectedPosition "Driver assistance computer (primary): sw164 detected position";
CM_ SG_ 1513 APP_sw165_colorFilterMismatch "Driver assistance computer (primary): sw165 color filter mismatch";
CM_ SG_ 1513 APP_sw165_detectedColorFilter "Driver assistance computer (primary): sw165 detected color filter";
CM_ SG_ 1513 APP_sw165_expectedColorFilter "Driver assistance computer (primary): sw165 expected color filter";
CM_ SG_ 1513 APP_sw165_cameraPositionMismatch "Driver assistance computer (primary): sw165 camera position mismatch";
CM_ SG_ 1513 APP_sw165_blacklistedFuseID "Driver assistance computer (primary): sw165 blacklisted fuse ID";
CM_ SG_ 1513 APP_sw165_uuidMismatch "Driver assistance computer (primary): sw165 uuid mismatch";
CM_ SG_ 1513 APP_sw165_detectedPosition "Driver assistance computer (primary): sw165 detected position";
CM_ SG_ 1513 APP_sw166_colorFilterMismatch "Driver assistance computer (primary): sw166 color filter mismatch";
CM_ SG_ 1513 APP_sw166_detectedColorFilter "Driver assistance computer (primary): sw166 detected color filter";
CM_ SG_ 1513 APP_sw166_expectedColorFilter "Driver assistance computer (primary): sw166 expected color filter";
CM_ SG_ 1513 APP_sw166_cameraPositionMismatch "Driver assistance computer (primary): sw166 camera position mismatch";
CM_ SG_ 1513 APP_sw166_blacklistedFuseID "Driver assistance computer (primary): sw166 blacklisted fuse ID";
CM_ SG_ 1513 APP_sw166_uuidMismatch "Driver assistance computer (primary): sw166 uuid mismatch";
CM_ SG_ 1513 APP_sw166_detectedPosition "Driver assistance computer (primary): sw166 detected position";
CM_ SG_ 1513 APP_sw167_colorFilterMismatch "Driver assistance computer (primary): sw167 color filter mismatch";
CM_ SG_ 1513 APP_sw167_detectedColorFilter "Driver assistance computer (primary): sw167 detected color filter";
CM_ SG_ 1513 APP_sw167_expectedColorFilter "Driver assistance computer (primary): sw167 expected color filter";
CM_ SG_ 1513 APP_sw167_cameraPositionMismatch "Driver assistance computer (primary): sw167 camera position mismatch";
CM_ SG_ 1513 APP_sw167_blacklistedFuseID "Driver assistance computer (primary): sw167 blacklisted fuse ID";
CM_ SG_ 1513 APP_sw167_uuidMismatch "Driver assistance computer (primary): sw167 uuid mismatch";
CM_ SG_ 1513 APP_sw167_detectedPosition "Driver assistance computer (primary): sw167 detected position";
CM_ SG_ 1513 APP_sw168_colorFilterMismatch "Driver assistance computer (primary): sw168 color filter mismatch";
CM_ SG_ 1513 APP_sw168_detectedColorFilter "Driver assistance computer (primary): sw168 detected color filter";
CM_ SG_ 1513 APP_sw168_expectedColorFilter "Driver assistance computer (primary): sw168 expected color filter";
CM_ SG_ 1513 APP_sw168_cameraPositionMismatch "Driver assistance computer (primary): sw168 camera position mismatch";
CM_ SG_ 1513 APP_sw168_blacklistedFuseID "Driver assistance computer (primary): sw168 blacklisted fuse ID";
CM_ SG_ 1513 APP_sw168_uuidMismatch "Driver assistance computer (primary): sw168 uuid mismatch";
CM_ SG_ 1513 APP_sw168_detectedPosition "Driver assistance computer (primary): sw168 detected position";
CM_ SG_ 1513 APP_sw169_colorFilterMismatch "Driver assistance computer (primary): sw169 color filter mismatch";
CM_ SG_ 1513 APP_sw169_detectedColorFilter "Driver assistance computer (primary): sw169 detected color filter";
CM_ SG_ 1513 APP_sw169_expectedColorFilter "Driver assistance computer (primary): sw169 expected color filter";
CM_ SG_ 1513 APP_sw169_cameraPositionMismatch "Driver assistance computer (primary): sw169 camera position mismatch";
CM_ SG_ 1513 APP_sw169_blacklistedFuseID "Driver assistance computer (primary): sw169 blacklisted fuse ID";
CM_ SG_ 1513 APP_sw169_uuidMismatch "Driver assistance computer (primary): sw169 uuid mismatch";
CM_ SG_ 1513 APP_sw169_detectedPosition "Driver assistance computer (primary): sw169 detected position";
CM_ SG_ 1513 APP_sw170_colorFilterMismatch "Driver assistance computer (primary): sw170 color filter mismatch";
CM_ SG_ 1513 APP_sw170_detectedColorFilter "Driver assistance computer (primary): sw170 detected color filter";
CM_ SG_ 1513 APP_sw170_expectedColorFilter "Driver assistance computer (primary): sw170 expected color filter";
CM_ SG_ 1513 APP_sw170_cameraPositionMismatch "Driver assistance computer (primary): sw170 camera position mismatch";
CM_ SG_ 1513 APP_sw170_blacklistedFuseID "Driver assistance computer (primary): sw170 blacklisted fuse ID";
CM_ SG_ 1513 APP_sw170_uuidMismatch "Driver assistance computer (primary): sw170 uuid mismatch";
CM_ SG_ 1513 APP_sw170_detectedPosition "Driver assistance computer (primary): sw170 detected position";
CM_ SG_ 1513 APP_sw171_APP_parkerATemp "Driver assistance computer (primary): sw171 APP parker a temp";
CM_ SG_ 1513 APP_sw171_APP_parkerBTemp "Driver assistance computer (primary): sw171 APP parker b temp";
CM_ SG_ 1513 APP_sw171_APP_pascalTemp "Driver assistance computer (primary): sw171 APP pascal temp";
CM_ SG_ 1513 APP_sw171_APP_pascalExtTemp "Driver assistance computer (primary): sw171 APP pascal ext temp";
CM_ SG_ 1513 APP_sw172_fisheyeCamExtNoCalFile "Driver assistance computer (primary): sw172 fisheye cam ext no cal file";
CM_ SG_ 1513 APP_sw173_lPillarCamExtNoCalFile "Driver assistance computer (primary): sw173 l pillar cam ext no cal file";
CM_ SG_ 1513 APP_sw174_rPillarCamExtNoCalFile "Driver assistance computer (primary): sw174 r pillar cam ext no cal file";
CM_ SG_ 1513 APP_sw175_lRepeatCamExtNoCalFile "Driver assistance computer (primary): sw175 l repeat cam ext no cal file";
CM_ SG_ 1513 APP_sw176_rRepeatCamExtNoCalFile "Driver assistance computer (primary): sw176 r repeat cam ext no cal file";
CM_ SG_ 1513 APP_sw182_exitStatus "Driver assistance computer (primary): sw182 exit status";
CM_ SG_ 1513 APP_sw182_bufferError "Driver assistance computer (primary): sw182 buffer error";
CM_ SG_ 1513 APP_sw182_frameGrabFailure "Driver assistance computer (primary): sw182 frame grab failure";
CM_ SG_ 1513 APP_sw182_gainControlFailure "Driver assistance computer (primary): sw182 gain control failure";
CM_ SG_ 1513 APP_sw182_tempMonitorFailure "Driver assistance computer (primary): sw182 temp monitor failure";
CM_ SG_ 1513 APP_sw182_firstFrameGrabFailure "Driver assistance computer (primary): sw182 first frame grab failure";
CM_ SG_ 1513 APP_sw182_deserParityError "Driver assistance computer (primary): sw182 deser parity error";
CM_ SG_ 1513 APP_sw182_deserLockError "Driver assistance computer (primary): sw182 deser lock error";
CM_ SG_ 1513 APP_sw182_deserCrcError "Driver assistance computer (primary): sw182 deser crc error";
CM_ SG_ 1513 APP_sw182_imagerHeartbeat "Driver assistance computer (primary): sw182 imager heartbeat; raw 3 = signal not available (SNA)";
CM_ SG_ 1513 APP_sw182_serializerCrcErrCount "Driver assistance computer (primary): sw182 serializer crc err count; raw 255 = signal not available (SNA)";
CM_ SG_ 1513 APP_sw182_deserLineLengthError "Driver assistance computer (primary): sw182 deser line length error";
CM_ SG_ 1513 APP_sw182_numCaptureRecoveries "Driver assistance computer (primary): sw182 num capture recoveries";
CM_ SG_ 1513 APP_sw182_currentTemperature "Driver assistance computer (primary): sw182 current temperature; raw 255 = signal not available (SNA)";
CM_ SG_ 1513 APP_sw182_minTemperature "Driver assistance computer (primary): sw182 min temperature; raw 255 = signal not available (SNA)";
CM_ SG_ 1513 APP_sw182_maxTemperature "Driver assistance computer (primary): sw182 max temperature; raw 255 = signal not available (SNA)";
CM_ SG_ 1513 APP_sw183_exitStatus "Driver assistance computer (primary): sw183 exit status";
CM_ SG_ 1513 APP_sw183_bufferError "Driver assistance computer (primary): sw183 buffer error";
CM_ SG_ 1513 APP_sw183_frameGrabFailure "Driver assistance computer (primary): sw183 frame grab failure";
CM_ SG_ 1513 APP_sw183_gainControlFailure "Driver assistance computer (primary): sw183 gain control failure";
CM_ SG_ 1513 APP_sw183_tempMonitorFailure "Driver assistance computer (primary): sw183 temp monitor failure";
CM_ SG_ 1513 APP_sw183_firstFrameGrabFailure "Driver assistance computer (primary): sw183 first frame grab failure";
CM_ SG_ 1513 APP_sw183_deserParityError "Driver assistance computer (primary): sw183 deser parity error";
CM_ SG_ 1513 APP_sw183_deserLockError "Driver assistance computer (primary): sw183 deser lock error";
CM_ SG_ 1513 APP_sw183_deserCrcError "Driver assistance computer (primary): sw183 deser crc error";
CM_ SG_ 1513 APP_sw183_imagerHeartbeat "Driver assistance computer (primary): sw183 imager heartbeat; raw 3 = signal not available (SNA)";
CM_ SG_ 1513 APP_sw183_serializerCrcErrCount "Driver assistance computer (primary): sw183 serializer crc err count; raw 255 = signal not available (SNA)";
CM_ SG_ 1513 APP_sw183_deserLineLengthError "Driver assistance computer (primary): sw183 deser line length error";
CM_ SG_ 1513 APP_sw183_numCaptureRecoveries "Driver assistance computer (primary): sw183 num capture recoveries";
CM_ SG_ 1513 APP_sw183_currentTemperature "Driver assistance computer (primary): sw183 current temperature; raw 255 = signal not available (SNA)";
CM_ SG_ 1513 APP_sw183_minTemperature "Driver assistance computer (primary): sw183 min temperature; raw 255 = signal not available (SNA)";
CM_ SG_ 1513 APP_sw183_maxTemperature "Driver assistance computer (primary): sw183 max temperature; raw 255 = signal not available (SNA)";
CM_ SG_ 1513 APP_sw184_exitStatus "Driver assistance computer (primary): sw184 exit status";
CM_ SG_ 1513 APP_sw184_bufferError "Driver assistance computer (primary): sw184 buffer error";
CM_ SG_ 1513 APP_sw184_frameGrabFailure "Driver assistance computer (primary): sw184 frame grab failure";
CM_ SG_ 1513 APP_sw184_gainControlFailure "Driver assistance computer (primary): sw184 gain control failure";
CM_ SG_ 1513 APP_sw184_tempMonitorFailure "Driver assistance computer (primary): sw184 temp monitor failure";
CM_ SG_ 1513 APP_sw184_firstFrameGrabFailure "Driver assistance computer (primary): sw184 first frame grab failure";
CM_ SG_ 1513 APP_sw184_deserParityError "Driver assistance computer (primary): sw184 deser parity error";
CM_ SG_ 1513 APP_sw184_deserLockError "Driver assistance computer (primary): sw184 deser lock error";
CM_ SG_ 1513 APP_sw184_deserCrcError "Driver assistance computer (primary): sw184 deser crc error";
CM_ SG_ 1513 APP_sw184_imagerHeartbeat "Driver assistance computer (primary): sw184 imager heartbeat; raw 3 = signal not available (SNA)";
CM_ SG_ 1513 APP_sw184_serializerCrcErrCount "Driver assistance computer (primary): sw184 serializer crc err count; raw 255 = signal not available (SNA)";
CM_ SG_ 1513 APP_sw184_deserLineLengthError "Driver assistance computer (primary): sw184 deser line length error";
CM_ SG_ 1513 APP_sw184_numCaptureRecoveries "Driver assistance computer (primary): sw184 num capture recoveries";
CM_ SG_ 1513 APP_sw184_currentTemperature "Driver assistance computer (primary): sw184 current temperature; raw 255 = signal not available (SNA)";
CM_ SG_ 1513 APP_sw184_minTemperature "Driver assistance computer (primary): sw184 min temperature; raw 255 = signal not available (SNA)";
CM_ SG_ 1513 APP_sw184_maxTemperature "Driver assistance computer (primary): sw184 max temperature; raw 255 = signal not available (SNA)";
CM_ SG_ 1513 APP_sw185_exitStatus "Driver assistance computer (primary): sw185 exit status";
CM_ SG_ 1513 APP_sw185_bufferError "Driver assistance computer (primary): sw185 buffer error";
CM_ SG_ 1513 APP_sw185_frameGrabFailure "Driver assistance computer (primary): sw185 frame grab failure";
CM_ SG_ 1513 APP_sw185_gainControlFailure "Driver assistance computer (primary): sw185 gain control failure";
CM_ SG_ 1513 APP_sw185_tempMonitorFailure "Driver assistance computer (primary): sw185 temp monitor failure";
CM_ SG_ 1513 APP_sw185_firstFrameGrabFailure "Driver assistance computer (primary): sw185 first frame grab failure";
CM_ SG_ 1513 APP_sw185_deserParityError "Driver assistance computer (primary): sw185 deser parity error";
CM_ SG_ 1513 APP_sw185_deserLockError "Driver assistance computer (primary): sw185 deser lock error";
CM_ SG_ 1513 APP_sw185_deserCrcError "Driver assistance computer (primary): sw185 deser crc error";
CM_ SG_ 1513 APP_sw185_imagerHeartbeat "Driver assistance computer (primary): sw185 imager heartbeat; raw 3 = signal not available (SNA)";
CM_ SG_ 1513 APP_sw185_serializerCrcErrCount "Driver assistance computer (primary): sw185 serializer crc err count; raw 255 = signal not available (SNA)";
CM_ SG_ 1513 APP_sw185_deserLineLengthError "Driver assistance computer (primary): sw185 deser line length error";
CM_ SG_ 1513 APP_sw185_numCaptureRecoveries "Driver assistance computer (primary): sw185 num capture recoveries";
CM_ SG_ 1513 APP_sw185_currentTemperature "Driver assistance computer (primary): sw185 current temperature; raw 255 = signal not available (SNA)";
CM_ SG_ 1513 APP_sw185_minTemperature "Driver assistance computer (primary): sw185 min temperature; raw 255 = signal not available (SNA)";
CM_ SG_ 1513 APP_sw185_maxTemperature "Driver assistance computer (primary): sw185 max temperature; raw 255 = signal not available (SNA)";
CM_ SG_ 1513 APP_sw186_exitStatus "Driver assistance computer (primary): sw186 exit status";
CM_ SG_ 1513 APP_sw186_bufferError "Driver assistance computer (primary): sw186 buffer error";
CM_ SG_ 1513 APP_sw186_frameGrabFailure "Driver assistance computer (primary): sw186 frame grab failure";
CM_ SG_ 1513 APP_sw186_gainControlFailure "Driver assistance computer (primary): sw186 gain control failure";
CM_ SG_ 1513 APP_sw186_tempMonitorFailure "Driver assistance computer (primary): sw186 temp monitor failure";
CM_ SG_ 1513 APP_sw186_firstFrameGrabFailure "Driver assistance computer (primary): sw186 first frame grab failure";
CM_ SG_ 1513 APP_sw186_deserParityError "Driver assistance computer (primary): sw186 deser parity error";
CM_ SG_ 1513 APP_sw186_deserLockError "Driver assistance computer (primary): sw186 deser lock error";
CM_ SG_ 1513 APP_sw186_deserCrcError "Driver assistance computer (primary): sw186 deser crc error";
CM_ SG_ 1513 APP_sw186_imagerHeartbeat "Driver assistance computer (primary): sw186 imager heartbeat; raw 3 = signal not available (SNA)";
CM_ SG_ 1513 APP_sw186_serializerCrcErrCount "Driver assistance computer (primary): sw186 serializer crc err count; raw 255 = signal not available (SNA)";
CM_ SG_ 1513 APP_sw186_deserLineLengthError "Driver assistance computer (primary): sw186 deser line length error";
CM_ SG_ 1513 APP_sw186_numCaptureRecoveries "Driver assistance computer (primary): sw186 num capture recoveries";
CM_ SG_ 1513 APP_sw186_currentTemperature "Driver assistance computer (primary): sw186 current temperature; raw 255 = signal not available (SNA)";
CM_ SG_ 1513 APP_sw186_minTemperature "Driver assistance computer (primary): sw186 min temperature; raw 255 = signal not available (SNA)";
CM_ SG_ 1513 APP_sw186_maxTemperature "Driver assistance computer (primary): sw186 max temperature; raw 255 = signal not available (SNA)";
CM_ SG_ 1513 APP_sw187_exitStatus "Driver assistance computer (primary): sw187 exit status";
CM_ SG_ 1513 APP_sw187_bufferError "Driver assistance computer (primary): sw187 buffer error";
CM_ SG_ 1513 APP_sw187_frameGrabFailure "Driver assistance computer (primary): sw187 frame grab failure";
CM_ SG_ 1513 APP_sw187_gainControlFailure "Driver assistance computer (primary): sw187 gain control failure";
CM_ SG_ 1513 APP_sw187_tempMonitorFailure "Driver assistance computer (primary): sw187 temp monitor failure";
CM_ SG_ 1513 APP_sw187_firstFrameGrabFailure "Driver assistance computer (primary): sw187 first frame grab failure";
CM_ SG_ 1513 APP_sw187_deserParityError "Driver assistance computer (primary): sw187 deser parity error";
CM_ SG_ 1513 APP_sw187_deserLockError "Driver assistance computer (primary): sw187 deser lock error";
CM_ SG_ 1513 APP_sw187_deserCrcError "Driver assistance computer (primary): sw187 deser crc error";
CM_ SG_ 1513 APP_sw187_imagerHeartbeat "Driver assistance computer (primary): sw187 imager heartbeat; raw 3 = signal not available (SNA)";
CM_ SG_ 1513 APP_sw187_serializerCrcErrCount "Driver assistance computer (primary): sw187 serializer crc err count; raw 255 = signal not available (SNA)";
CM_ SG_ 1513 APP_sw187_deserLineLengthError "Driver assistance computer (primary): sw187 deser line length error";
CM_ SG_ 1513 APP_sw187_numCaptureRecoveries "Driver assistance computer (primary): sw187 num capture recoveries";
CM_ SG_ 1513 APP_sw187_currentTemperature "Driver assistance computer (primary): sw187 current temperature; raw 255 = signal not available (SNA)";
CM_ SG_ 1513 APP_sw187_minTemperature "Driver assistance computer (primary): sw187 min temperature; raw 255 = signal not available (SNA)";
CM_ SG_ 1513 APP_sw187_maxTemperature "Driver assistance computer (primary): sw187 max temperature; raw 255 = signal not available (SNA)";
CM_ SG_ 1513 APP_sw188_exitStatus "Driver assistance computer (primary): sw188 exit status";
BA_DEF_ "BusType" STRING;
BA_DEF_ "DBName" STRING;
BA_DEF_ "Baudrate" INT 0 1000000;
BA_DEF_ "BaudrateCANFD" INT 0 16000000;
BA_DEF_ "Manufacturer" STRING;
BA_DEF_ "FirmwareVersion" STRING;
BA_DEF_ "VehicleModel" STRING;
BA_DEF_ BU_ "ECU" STRING;
BA_DEF_ BO_ "GenMsgCycleTime" INT 0 3600000;
BA_DEF_ BO_ "GenMsgSendType" ENUM "Cyclic","NotUsed","NotUsed","NotUsed","NotUsed","NotUsed","NotUsed","IfActive","NoMsgSendType","NotUsed";
BA_DEF_ BO_ "VFrameFormat" ENUM "StandardCAN","ExtendedCAN","reserved","J1939PG","reserved","reserved","reserved","reserved","reserved","reserved","reserved","reserved","reserved","reserved","StandardCAN_FD","ExtendedCAN_FD";
BA_DEF_ BO_ "CANFD_BRS" ENUM "0","1";
BA_DEF_ SG_ "GenSigSNA" STRING;
BA_DEF_ SG_ "SystemSignalLongSymbol" STRING;
BA_DEF_ SG_ "Confidence" ENUM "validated","plausible","layout-only","contradicted";
BA_DEF_DEF_ "BusType" "CAN";
BA_DEF_DEF_ "DBName" "";
BA_DEF_DEF_ "Baudrate" 500000;
BA_DEF_DEF_ "BaudrateCANFD" 2000000;
BA_DEF_DEF_ "Manufacturer" "";
BA_DEF_DEF_ "FirmwareVersion" "";
BA_DEF_DEF_ "VehicleModel" "";
BA_DEF_DEF_ "ECU" "";
BA_DEF_DEF_ "GenMsgCycleTime" 0;
BA_DEF_DEF_ "GenMsgSendType" "NoMsgSendType";
BA_DEF_DEF_ "VFrameFormat" "StandardCAN";
BA_DEF_DEF_ "CANFD_BRS" "1";
BA_DEF_DEF_ "GenSigSNA" "";
BA_DEF_DEF_ "SystemSignalLongSymbol" "";
BA_DEF_DEF_ "Confidence" "layout-only";
BA_ "DBName" "AllModels_ETH";
BA_ "Manufacturer" "Tesla";
BA_ "FirmwareVersion" "2026.26.6.5";
BA_ "VehicleModel" "Model 3 / Model Y";
BA_ "ECU" BU_ ADSP "ADSP";
BA_ "ECU" BU_ APB "APB";
BA_ "ECU" BU_ APP "APP";
BA_ "ECU" BU_ APS "APS";
BA_ "ECU" BU_ APSB "APSB";
BA_ "ECU" BU_ BB "BB";
BA_ "ECU" BU_ BMS "BMS";
BA_ "ECU" BU_ CC "CC";
BA_ "ECU" BU_ CMP "CMP";
BA_ "ECU" BU_ CMPD "CMPD";
BA_ "ECU" BU_ CP "CP";
BA_ "ECU" BU_ DAS "DAS";
BA_ "ECU" BU_ DI "DI";
BA_ "ECU" BU_ DIF "DIF";
BA_ "ECU" BU_ DIR "DIR";
BA_ "ECU" BU_ DPB "DPB";
BA_ "ECU" BU_ EPAS3P "EPAS3P";
BA_ "ECU" BU_ EPAS3S "EPAS3S";
BA_ "ECU" BU_ EPASTP "EPASTP";
BA_ "ECU" BU_ EPASTS "EPASTS";
BA_ "ECU" BU_ EPBL "EPBL";
BA_ "ECU" BU_ EPBR "EPBR";
BA_ "ECU" BU_ ESP "ESP";
BA_ "ECU" BU_ EVSE "EVSE";
BA_ "ECU" BU_ FC "FC";
BA_ "ECU" BU_ GTW "GTW";
BA_ "ECU" BU_ HCML "HCML";
BA_ "ECU" BU_ HCMR "HCMR";
BA_ "ECU" BU_ HVP "HVP";
BA_ "ECU" BU_ IBST "IBST";
BA_ "ECU" BU_ ICR "ICR";
BA_ "ECU" BU_ IDB "IDB";
BA_ "ECU" BU_ LS "LS";
BA_ "ECU" BU_ OCS1P "OCS1P";
BA_ "ECU" BU_ PARK "PARK";
BA_ "ECU" BU_ PCS "PCS";
BA_ "ECU" BU_ PCS2 "PCS2";
BA_ "ECU" BU_ PM "PM";
BA_ "ECU" BU_ PMF "PMF";
BA_ "ECU" BU_ PMR "PMR";
BA_ "ECU" BU_ PNCD "PNCD";
BA_ "ECU" BU_ PTC "PTC";
BA_ "ECU" BU_ RADC "RADC";
BA_ "ECU" BU_ RCM "RCM";
BA_ "ECU" BU_ RCM2 "RCM2";
BA_ "ECU" BU_ RCM3 "RCM3";
BA_ "ECU" BU_ RCU "RCU";
BA_ "ECU" BU_ SCCM "SCCM";
BA_ "ECU" BU_ SCM "SCM";
BA_ "ECU" BU_ SCS "SCS";
BA_ "ECU" BU_ SDCR "SDCR";
BA_ "ECU" BU_ TAS "TAS";
BA_ "ECU" BU_ TCU "TCU";
BA_ "ECU" BU_ TCU2 "TCU2";
BA_ "ECU" BU_ TPMS "TPMS";
BA_ "ECU" BU_ TRCM "TRCM";
BA_ "ECU" BU_ UI "UI";
BA_ "ECU" BU_ UIS "UIS";
BA_ "ECU" BU_ UMC "UMC";
BA_ "ECU" BU_ USM "USM";
BA_ "ECU" BU_ V2G "V2G";
BA_ "ECU" BU_ VC "VC";
BA_ "ECU" BU_ VCBATT "VCBATT";
BA_ "ECU" BU_ VCBATT0 "VCBATT0";
BA_ "ECU" BU_ VCBATT1 "VCBATT1";
BA_ "ECU" BU_ VCBATT2 "VCBATT2";
BA_ "ECU" BU_ VCCC "VCCC";
BA_ "ECU" BU_ VCFRONT "VCFRONT";
BA_ "ECU" BU_ VCFRONT1 "VCFRONT1";
BA_ "ECU" BU_ VCFRONT2 "VCFRONT2";
BA_ "ECU" BU_ VCLEFT "VCLEFT";
BA_ "ECU" BU_ VCRIGHT "VCRIGHT";
BA_ "ECU" BU_ VCSEAT2L "VCSEAT2L";
BA_ "ECU" BU_ VCSEAT2R "VCSEAT2R";
BA_ "ECU" BU_ VCSEC "VCSEC";
BA_ "ECU" BU_ VEH "VEH";
BA_ "GenMsgCycleTime" BO_ 1361 1000;
BA_ "GenMsgSendType" BO_ 1361 0;
BA_ "GenMsgCycleTime" BO_ 1362 1000;
BA_ "GenMsgSendType" BO_ 1362 0;
BA_ "GenMsgCycleTime" BO_ 1951 20;
BA_ "GenMsgSendType" BO_ 1951 0;
BA_ "GenMsgCycleTime" BO_ 1383 200;
BA_ "GenMsgSendType" BO_ 1383 0;
BA_ "GenMsgCycleTime" BO_ 600 100;
BA_ "GenMsgSendType" BO_ 600 0;
BA_ "GenMsgCycleTime" BO_ 909 1000;
BA_ "GenMsgSendType" BO_ 909 0;
BA_ "Confidence" SG_ 1360 ADSP_alertID 1;
BA_ "Confidence" SG_ 1360 ADSP_alertState 1;
BA_ "Confidence" SG_ 1360 ADSP_a002_cause 1;
BA_ "Confidence" SG_ 1360 ADSP_a022_error 1;
BA_ "Confidence" SG_ 1360 ADSP_a035_a2baIntrType 1;
BA_ "Confidence" SG_ 1360 ADSP_a035_a2baFaultType 1;
BA_ "Confidence" SG_ 1360 ADSP_a036_a2bbIntrType 1;
BA_ "Confidence" SG_ 1360 ADSP_a036_a2bbFaultType 1;
BA_ "Confidence" SG_ 1360 ADSP_a053_audioSystemUnavailable 1;
BA_ "Confidence" SG_ 1360 ADSP_a067_baseamp0Fault 1;
BA_ "Confidence" SG_ 1360 ADSP_a067_baseamp0Temp 1;
BA_ "Confidence" SG_ 1360 ADSP_a068_baseamp1Fault 1;
BA_ "Confidence" SG_ 1360 ADSP_a068_baseamp1Temp 1;
BA_ "Confidence" SG_ 1360 ADSP_a069_baseamp2Fault 1;
BA_ "Confidence" SG_ 1360 ADSP_a069_baseamp2Temp 1;
BA_ "Confidence" SG_ 1360 ADSP_a070_baseamp3Fault 1;
BA_ "Confidence" SG_ 1360 ADSP_a070_baseamp3Temp 1;
BA_ "Confidence" SG_ 1360 ADSP_a071_versionMismatch 1;
BA_ "Confidence" SG_ 1360 ADSP_a080_micInitError 1;
BA_ "SystemSignalLongSymbol" SG_ 1362 ADSP_w065_tcuGpioExpanderCritica "ADSP_w065_tcuGpioExpanderCriticalError";
BA_ "SystemSignalLongSymbol" SG_ 1362 ADSP_w072_turnSignalChannelUnder "ADSP_w072_turnSignalChannelUnderrun";
BA_ "SystemSignalLongSymbol" SG_ 1362 ADSP_w076_activeSafetyChannelUnd "ADSP_w076_activeSafetyChannelUnderrun";
BA_ "Confidence" SG_ 1951 ADSP_audioVisualizerBrightness 0;
BA_ "Confidence" SG_ 1383 ADSP_a2baState 0;
BA_ "Confidence" SG_ 1383 ADSP_a2bbState 0;
BA_ "Confidence" SG_ 1383 ADSP_baseamp0State 0;
BA_ "Confidence" SG_ 1383 ADSP_baseamp1State 0;
BA_ "Confidence" SG_ 1383 ADSP_baseamp2State 0;
BA_ "Confidence" SG_ 1383 ADSP_baseamp3State 0;
BA_ "Confidence" SG_ 1383 ADSP_audioReady 0;
BA_ "Confidence" SG_ 1383 ADSP_extSpkCheckRan 0;
BA_ "Confidence" SG_ 1383 ADSP_tcuI2SEnabled 0;
BA_ "Confidence" SG_ 1383 ADSP_telephonyRxMute 0;
BA_ "Confidence" SG_ 1383 ADSP_ancState 0;
BA_ "Confidence" SG_ 1383 ADSP_sourceSelect 0;
BA_ "Confidence" SG_ 1383 ADSP_tunerSelect 0;
BA_ "Confidence" SG_ 1383 ADSP_ancMode 0;
BA_ "Confidence" SG_ 1383 ADSP_spkMuteAll 0;
BA_ "Confidence" SG_ 1383 ADSP_eCall_ENS_state 0;
BA_ "Confidence" SG_ 1383 ADSP_eCallSelfTest 0;
BA_ "Confidence" SG_ 1383 ADSP_eCallState 0;
BA_ "Confidence" SG_ 1383 ADSP_allAudioReady 0;
BA_ "Confidence" SG_ 1383 ADSP_callState 0;
BA_ "Confidence" SG_ 1383 ADSP_telephonyTxMute 0;
BA_ "Confidence" SG_ 1383 ADSP_eCallMicrophoneStatus 0;
BA_ "Confidence" SG_ 1383 ADSP_eCallSpeakerStatus 0;
BA_ "Confidence" SG_ 1383 ADSP_a2baLoadShedded 0;
BA_ "Confidence" SG_ 1383 ADSP_requestFailoverSpeaker 0;
BA_ "Confidence" SG_ 1383 ADSP_microphoneDataState 0;
BA_ "Confidence" SG_ 600 APB_watchdogState 0;
BA_ "GenSigSNA" SG_ 600 APB_watchdogState "7";
BA_ "Confidence" SG_ 600 APB_fusedState 0;
BA_ "GenSigSNA" SG_ 600 APB_fusedState "3";
BA_ "Confidence" SG_ 600 APB_cameraHeaterRequest 0;
BA_ "Confidence" SG_ 600 APB_factorySummonStatus 0;
BA_ "GenSigSNA" SG_ 600 APB_factorySummonStatus "0";
BA_ "Confidence" SG_ 600 APB_clipRecordingStatus 0;
BA_ "Confidence" SG_ 600 APB_summonUnavailableReason 0;
BA_ "Confidence" SG_ 600 APB_fsdSuspendState 0;
BA_ "GenSigSNA" SG_ 600 APB_fsdSuspendState "3";
BA_ "Confidence" SG_ 600 APB_fsdRevokeStrikeoutCount 0;
BA_ "GenSigSNA" SG_ 600 APB_fsdRevokeStrikeoutCount "7";
BA_ "Confidence" SG_ 600 APB_teslaVisionSupported 0;
BA_ "GenSigSNA" SG_ 600 APB_teslaVisionSupported "3";
BA_ "Confidence" SG_ 600 APB_teslaVisionUnsupportedReason 0;
BA_ "Confidence" SG_ 600 APB_fsdRevokeCount 0;
BA_ "GenSigSNA" SG_ 600 APB_fsdRevokeCount "7";
BA_ "Confidence" SG_ 600 APB_excessiveAccelPedalWarning 0;
BA_ "Confidence" SG_ 600 APB_unifiedObjectStackSupported 0;
BA_ "GenSigSNA" SG_ 600 APB_unifiedObjectStackSupported "3";
BA_ "Confidence" SG_ 600 APB_sendingBUCStream 0;
BA_ "Confidence" SG_ 600 APB_DDAWSystemStatus 0;
BA_ "GenSigSNA" SG_ 600 APB_DDAWSystemStatus "4";
BA_ "Confidence" SG_ 600 APB_socOperatingMode 0;
BA_ "Confidence" SG_ 600 APB_summonVersionIdentifier 0;
BA_ "Confidence" SG_ 600 APB_sentryState 0;
BA_ "GenSigSNA" SG_ 600 APB_sentryState "6";
BA_ "Confidence" SG_ 600 APB_autoparkVersionIdentifier 0;
BA_ "Confidence" SG_ 600 APB_autonomySystemHealth 0;
BA_ "Confidence" SG_ 600 APB_suspendResumeAvailable 0;
BA_ "Confidence" SG_ 600 APB_statusCounter 0;
BA_ "Confidence" SG_ 600 APB_statusChecksum 0;
BA_ "Confidence" SG_ 909 APP_inTunnel 0;
BA_ "GenSigSNA" SG_ 909 APP_inTunnel "0";
BA_ "Confidence" SG_ 909 APP_windshieldHeaterOnReason 0;
BA_ "GenSigSNA" SG_ 909 APP_windshieldHeaterOnReason "0";
BA_ "Confidence" SG_ 909 APP_selfieCameraBlocked 0;
BA_ "GenSigSNA" SG_ 909 APP_selfieCameraBlocked "0";
BA_ "Confidence" SG_ 909 APP_selfieCameraLUX 0;
BA_ "GenSigSNA" SG_ 909 APP_selfieCameraLUX "255";
BA_ "Confidence" SG_ 909 APP_sceneTagClearlyRaining 0;
BA_ "GenSigSNA" SG_ 909 APP_sceneTagClearlyRaining "0";
BA_ "Confidence" SG_ 909 APP_sceneTagFog 0;
BA_ "GenSigSNA" SG_ 909 APP_sceneTagFog "0";
BA_ "Confidence" SG_ 909 APP_sceneTagFullyBlocked 0;
BA_ "GenSigSNA" SG_ 909 APP_sceneTagFullyBlocked "0";
BA_ "Confidence" SG_ 909 APP_sceneTagIndoors 0;
BA_ "GenSigSNA" SG_ 909 APP_sceneTagIndoors "0";
BA_ "Confidence" SG_ 909 APP_sceneTagLensFlare 0;
BA_ "GenSigSNA" SG_ 909 APP_sceneTagLensFlare "0";
BA_ "Confidence" SG_ 909 APP_sceneTagRaining 0;
BA_ "GenSigSNA" SG_ 909 APP_sceneTagRaining "0";
BA_ "Confidence" SG_ 909 APP_sceneTagSevereWeather 0;
BA_ "GenSigSNA" SG_ 909 APP_sceneTagSevereWeather "0";
BA_ "Confidence" SG_ 909 APP_sceneTagSnowing 0;
BA_ "GenSigSNA" SG_ 909 APP_sceneTagSnowing "0";
BA_ "Confidence" SG_ 909 APP_sceneTagSnowyRoad 0;
BA_ "GenSigSNA" SG_ 909 APP_sceneTagSnowyRoad "0";
BA_ "Confidence" SG_ 909 APP_sceneTagSunGlare 0;
BA_ "GenSigSNA" SG_ 909 APP_sceneTagSunGlare "0";
BA_ "Confidence" SG_ 909 APP_sceneTagTunnel 0;
BA_ "GenSigSNA" SG_ 909 APP_sceneTagTunnel "0";
BA_ "Confidence" SG_ 909 APP_sceneTagWetRoad 0;
BA_ "GenSigSNA" SG_ 909 APP_sceneTagWetRoad "0";
BA_ "Confidence" SG_ 909 APP_fisheyeInPathVisibility 0;
BA_ "GenSigSNA" SG_ 909 APP_fisheyeInPathVisibility "0";
BA_ "Confidence" SG_ 909 APP_fisheyeOverallVisibility 0;
BA_ "GenSigSNA" SG_ 909 APP_fisheyeOverallVisibility "0";
BA_ "Confidence" SG_ 909 APP_mainInPathVisibility 0;
BA_ "GenSigSNA" SG_ 909 APP_mainInPathVisibility "0";
BA_ "Confidence" SG_ 909 APP_mainOverallVisibility 0;
BA_ "GenSigSNA" SG_ 909 APP_mainOverallVisibility "0";
BA_ "Confidence" SG_ 909 APP_narrowInPathVisibility 0;
BA_ "GenSigSNA" SG_ 909 APP_narrowInPathVisibility "0";
BA_ "Confidence" SG_ 909 APP_narrowOverallVisibility 0;
BA_ "GenSigSNA" SG_ 909 APP_narrowOverallVisibility "0";
BA_ "Confidence" SG_ 909 APP_frontCamOcclusionType 0;
BA_ "Confidence" SG_ 1513 APP_alertID 1;
BA_ "Confidence" SG_ 1513 APP_alertSource 1;
BA_ "Confidence" SG_ 1513 APP_alertState 1;
BA_ "Confidence" SG_ 1513 APP_sw010_HorizontalMisalignment 1;
BA_ "Confidence" SG_ 1513 APP_sw010_VerticalMisalignment 1;
BA_ "Confidence" SG_ 1513 APP_sw010_VmaPlausibility 1;
BA_ "Confidence" SG_ 1513 APP_sw011_scaSpeed 1;
BA_ "Confidence" SG_ 1513 APP_sw011_scaSonicDist 1;
BA_ "Confidence" SG_ 1513 APP_sw011_scaSteerAngle 1;
BA_ "Confidence" SG_ 1513 APP_sw011_laneWidth 1;
BA_ "Confidence" SG_ 1513 APP_sw025_state_before_override 1;
BA_ "Confidence" SG_ 1513 APP_sw025_torsionBarTorque 1;
BA_ "Confidence" SG_ 1513 APP_sw040_accel_pedal_pos 1;
BA_ "Confidence" SG_ 1513 APP_sw040_ego_veh_speed 1;
BA_ "Confidence" SG_ 1513 APP_sw040_das_steering_req 1;
BA_ "Confidence" SG_ 1513 APP_sw040_epas_internal_sas 1;
BA_ "Confidence" SG_ 1513 APP_sw040_torsion_bar_torque 1;
BA_ "Confidence" SG_ 1513 APP_sw040_view_range 1;
BA_ "Confidence" SG_ 1513 APP_sw041_rate 1;
BA_ "Confidence" SG_ 1513 APP_sw041_max_rate 1;
BA_ "Confidence" SG_ 1513 APP_sw041_ego_speed 1;
BA_ "Confidence" SG_ 1513 APP_sw042_health_state 1;
BA_ "GenSigSNA" SG_ 1513 APP_sw042_health_state "7";
BA_ "Confidence" SG_ 1513 APP_sw042_abort_reason 1;
BA_ "Confidence" SG_ 1513 APP_sw050_targetDist 1;
BA_ "Confidence" SG_ 1513 APP_sw050_targetRelSpeed 1;
BA_ "Confidence" SG_ 1513 APP_sw050_targetOverlap 1;
BA_ "Confidence" SG_ 1513 APP_sw050_hostSpeed 1;
BA_ "Confidence" SG_ 1513 APP_sw050_hostLongAccel 1;
BA_ "Confidence" SG_ 1513 APP_sw073_escalateLDWreason 1;
BA_ "Confidence" SG_ 1513 APP_sw073_freespaceLeftC0 1;
BA_ "Confidence" SG_ 1513 APP_sw073_freespaceRightC0 1;
BA_ "Confidence" SG_ 1513 APP_sw073_freespaceLeftC1 1;
BA_ "Confidence" SG_ 1513 APP_sw073_freespaceRightC1 1;
BA_ "Confidence" SG_ 1513 APP_sw073_freespaceLeftFarZ 1;
BA_ "Confidence" SG_ 1513 APP_sw073_freespaceRightFarZ 1;
BA_ "Confidence" SG_ 1513 APP_sw077_oocDistance 1;
BA_ "Confidence" SG_ 1513 APP_sw077_oocConfidence 1;
BA_ "Confidence" SG_ 1513 APP_sw077_vehicleSpeed 1;
BA_ "Confidence" SG_ 1513 APP_sw077_oocUntrackedTime 1;
BA_ "Confidence" SG_ 1513 APP_sw080_rad_tar_5_dist 1;
BA_ "Confidence" SG_ 1513 APP_sw080_stw_angle_deg 1;
BA_ "Confidence" SG_ 1513 APP_sw080_ego_speed 1;
BA_ "Confidence" SG_ 1513 APP_sw081_radarDistance 1;
BA_ "Confidence" SG_ 1513 APP_sw081_radarTTC 1;
BA_ "Confidence" SG_ 1513 APP_sw081_cameraDistance 1;
BA_ "Confidence" SG_ 1513 APP_sw081_cameraTTC 1;
BA_ "Confidence" SG_ 1513 APP_sw081_pedalPosition 1;
BA_ "Confidence" SG_ 1513 APP_sw133_mainCamDeserFault 1;
BA_ "Confidence" SG_ 1513 APP_sw133_mainCamSensorFault 1;
BA_ "Confidence" SG_ 1513 APP_sw133_mainCamSerFault 1;
BA_ "Confidence" SG_ 1513 APP_sw134_narrowCamDeserFault 1;
BA_ "Confidence" SG_ 1513 APP_sw134_narrowCamSensorFault 1;
BA_ "Confidence" SG_ 1513 APP_sw134_narrowCamSerFault 1;
BA_ "Confidence" SG_ 1513 APP_sw135_fisheyeCamDeserFault 1;
BA_ "Confidence" SG_ 1513 APP_sw135_fisheyeCamSensorFault 1;
BA_ "Confidence" SG_ 1513 APP_sw135_fisheyeCamSerFault 1;
BA_ "Confidence" SG_ 1513 APP_sw136_lPillarCamDeserFault 1;
BA_ "Confidence" SG_ 1513 APP_sw136_lPillarCamSensorFault 1;
BA_ "Confidence" SG_ 1513 APP_sw136_lPillarCamSerFault 1;
BA_ "Confidence" SG_ 1513 APP_sw137_rPillarCamDeserFault 1;
BA_ "Confidence" SG_ 1513 APP_sw137_rPillarCamSensorFault 1;
BA_ "Confidence" SG_ 1513 APP_sw137_rPillarCamSerFault 1;
BA_ "Confidence" SG_ 1513 APP_sw138_lRepeatCamDeserFault 1;
BA_ "Confidence" SG_ 1513 APP_sw138_lRepeatCamSensorFault 1;
BA_ "Confidence" SG_ 1513 APP_sw138_lRepeatCamSerFault 1;
BA_ "Confidence" SG_ 1513 APP_sw139_rRepeatCamDeserFault 1;
BA_ "Confidence" SG_ 1513 APP_sw139_rRepeatCamSensorFault 1;
BA_ "Confidence" SG_ 1513 APP_sw139_rRepeatCamSerFault 1;
BA_ "Confidence" SG_ 1513 APP_sw140_backupCamCSIBridgeFlt 1;
BA_ "Confidence" SG_ 1513 APP_sw140_backupCamDeserFault 1;
BA_ "Confidence" SG_ 1513 APP_sw140_backupCamSensorFault 1;
BA_ "Confidence" SG_ 1513 APP_sw140_backupCamDeserLock 1;
BA_ "Confidence" SG_ 1513 APP_sw140_backupCamSerFault 1;
BA_ "Confidence" SG_ 1513 APP_sw141_maxThreshold 1;
BA_ "Confidence" SG_ 1513 APP_sw141_minThreshold 1;
BA_ "Confidence" SG_ 1513 APP_sw141_temperature 1;
BA_ "Confidence" SG_ 1513 APP_sw142_camExtPitchCal 1;
BA_ "Confidence" SG_ 1513 APP_sw142_pitchOffsetAtmptVal 1;
BA_ "Confidence" SG_ 1513 APP_sw142_problemCamPosition 1;
BA_ "Confidence" SG_ 1513 APP_sw145_problemCamPosition 1;
BA_ "Confidence" SG_ 1513 APP_sw145_camExtPitchCal 1;
BA_ "Confidence" SG_ 1513 APP_sw145_camExtYawCal 1;
BA_ "Confidence" SG_ 1513 APP_sw145_camExtRollCal 1;
BA_ "Confidence" SG_ 1513 APP_sw147_selfieCamDeserFault 1;
BA_ "Confidence" SG_ 1513 APP_sw147_selfieCamSensorFault 1;
BA_ "Confidence" SG_ 1513 APP_sw147_selfieCamSerFault 1;
BA_ "Confidence" SG_ 1513 APP_sw162_detectedColorFilter 1;
BA_ "Confidence" SG_ 1513 APP_sw162_expectedColorFilter 1;
BA_ "Confidence" SG_ 1513 APP_sw162_detectedPosition 1;
BA_ "Confidence" SG_ 1513 APP_sw163_detectedColorFilter 1;
BA_ "Confidence" SG_ 1513 APP_sw163_expectedColorFilter 1;
BA_ "Confidence" SG_ 1513 APP_sw163_detectedPosition 1;
BA_ "Confidence" SG_ 1513 APP_sw164_detectedColorFilter 1;
BA_ "Confidence" SG_ 1513 APP_sw164_expectedColorFilter 1;
BA_ "Confidence" SG_ 1513 APP_sw164_detectedPosition 1;
BA_ "Confidence" SG_ 1513 APP_sw165_detectedColorFilter 1;
BA_ "Confidence" SG_ 1513 APP_sw165_expectedColorFilter 1;
BA_ "Confidence" SG_ 1513 APP_sw165_detectedPosition 1;
BA_ "Confidence" SG_ 1513 APP_sw166_detectedColorFilter 1;
BA_ "Confidence" SG_ 1513 APP_sw166_expectedColorFilter 1;
BA_ "Confidence" SG_ 1513 APP_sw166_detectedPosition 1;
BA_ "Confidence" SG_ 1513 APP_sw167_detectedColorFilter 1;
BA_ "Confidence" SG_ 1513 APP_sw167_expectedColorFilter 1;
BA_ "Confidence" SG_ 1513 APP_sw167_detectedPosition 1;
BA_ "Confidence" SG_ 1513 APP_sw168_detectedColorFilter 1;
BA_ "Confidence" SG_ 1513 APP_sw168_expectedColorFilter 1;
BA_ "Confidence" SG_ 1513 APP_sw168_detectedPosition 1;
BA_ "Confidence" SG_ 1513 APP_sw169_detectedColorFilter 1;
BA_ "Confidence" SG_ 1513 APP_sw169_expectedColorFilter 1;
BA_ "Confidence" SG_ 1513 APP_sw169_detectedPosition 1;
BA_ "Confidence" SG_ 1513 APP_sw170_detectedColorFilter 1;
BA_ "Confidence" SG_ 1513 APP_sw170_expectedColorFilter 1;
BA_ "Confidence" SG_ 1513 APP_sw170_detectedPosition 1;
BA_ "Confidence" SG_ 1513 APP_sw171_APP_parkerATemp 1;
BA_ "Confidence" SG_ 1513 APP_sw171_APP_parkerBTemp 1;
BA_ "Confidence" SG_ 1513 APP_sw171_APP_pascalTemp 1;
BA_ "Confidence" SG_ 1513 APP_sw171_APP_pascalExtTemp 1;
BA_ "Confidence" SG_ 1513 APP_sw182_exitStatus 1;
BA_ "Confidence" SG_ 1513 APP_sw182_tempMonitorFailure 1;
BA_ "Confidence" SG_ 1513 APP_sw182_imagerHeartbeat 1;
BA_ "GenSigSNA" SG_ 1513 APP_sw182_imagerHeartbeat "3";
BA_ "Confidence" SG_ 1513 APP_sw182_serializerCrcErrCount 1;
BA_ "GenSigSNA" SG_ 1513 APP_sw182_serializerCrcErrCount "255";
BA_ "Confidence" SG_ 1513 APP_sw182_currentTemperature 1;
BA_ "GenSigSNA" SG_ 1513 APP_sw182_currentTemperature "255";
BA_ "Confidence" SG_ 1513 APP_sw182_minTemperature 1;
BA_ "GenSigSNA" SG_ 1513 APP_sw182_minTemperature "255";
BA_ "Confidence" SG_ 1513 APP_sw182_maxTemperature 1;
BA_ "GenSigSNA" SG_ 1513 APP_sw182_maxTemperature "255";
BA_ "Confidence" SG_ 1513 APP_sw183_exitStatus 1;
BA_ "Confidence" SG_ 1513 APP_sw183_tempMonitorFailure 1;
BA_ "Confidence" SG_ 1513 APP_sw183_imagerHeartbeat 1;
BA_ "GenSigSNA" SG_ 1513 APP_sw183_imagerHeartbeat "3";
BA_ "Confidence" SG_ 1513 APP_sw183_serializerCrcErrCount 1;
BA_ "GenSigSNA" SG_ 1513 APP_sw183_serializerCrcErrCount "255";
BA_ "Confidence" SG_ 1513 APP_sw183_currentTemperature 1;
BA_ "GenSigSNA" SG_ 1513 APP_sw183_currentTemperature "255";
BA_ "Confidence" SG_ 1513 APP_sw183_minTemperature 1;
BA_ "GenSigSNA" SG_ 1513 APP_sw183_minTemperature "255";
BA_ "Confidence" SG_ 1513 APP_sw183_maxTemperature 1;
BA_ "GenSigSNA" SG_ 1513 APP_sw183_maxTemperature "255";
BA_ "Confidence" SG_ 1513 APP_sw184_exitStatus 1;
BA_ "Confidence" SG_ 1513 APP_sw184_tempMonitorFailure 1;
BA_ "Confidence" SG_ 1513 APP_sw184_imagerHeartbeat 1;
BA_ "GenSigSNA" SG_ 1513 APP_sw184_imagerHeartbeat "3";
BA_ "Confidence" SG_ 1513 APP_sw184_serializerCrcErrCount 1;
BA_ "GenSigSNA" SG_ 1513 APP_sw184_serializerCrcErrCount "255";
BA_ "Confidence" SG_ 1513 APP_sw184_currentTemperature 1;
BA_ "GenSigSNA" SG_ 1513 APP_sw184_currentTemperature "255";
BA_ "Confidence" SG_ 1513 APP_sw184_minTemperature 1;
BA_ "GenSigSNA" SG_ 1513 APP_sw184_minTemperature "255";
BA_ "Confidence" SG_ 1513 APP_sw184_maxTemperature 1;
BA_ "GenSigSNA" SG_ 1513 APP_sw184_maxTemperature "255";
BA_ "Confidence" SG_ 1513 APP_sw185_exitStatus 1;
BA_ "Confidence" SG_ 1513 APP_sw185_tempMonitorFailure 1;
BA_ "Confidence" SG_ 1513 APP_sw185_imagerHeartbeat 1;
BA_ "GenSigSNA" SG_ 1513 APP_sw185_imagerHeartbeat "3";
BA_ "Confidence" SG_ 1513 APP_sw185_serializerCrcErrCount 1;
BA_ "GenSigSNA" SG_ 1513 APP_sw185_serializerCrcErrCount "255";
BA_ "Confidence" SG_ 1513 APP_sw185_currentTemperature 1;
BA_ "GenSigSNA" SG_ 1513 APP_sw185_currentTemperature "255";
BA_ "Confidence" SG_ 1513 APP_sw185_minTemperature 1;
BA_ "GenSigSNA" SG_ 1513 APP_sw185_minTemperature "255";
BA_ "Confidence" SG_ 1513 APP_sw185_maxTemperature 1;
BA_ "GenSigSNA" SG_ 1513 APP_sw185_maxTemperature "255";
BA_ "Confidence" SG_ 1513 APP_sw186_exitStatus 1;
BA_ "Confidence" SG_ 1513 APP_sw186_tempMonitorFailure 1;
BA_ "Confidence" SG_ 1513 APP_sw186_imagerHeartbeat 1;
BA_ "GenSigSNA" SG_ 1513 APP_sw186_imagerHeartbeat "3";
BA_ "Confidence" SG_ 1513 APP_sw186_serializerCrcErrCount 1;
BA_ "GenSigSNA" SG_ 1513 APP_sw186_serializerCrcErrCount "255";
BA_ "Confidence" SG_ 1513 APP_sw186_currentTemperature 1;
BA_ "GenSigSNA" SG_ 1513 APP_sw186_currentTemperature "255";
BA_ "Confidence" SG_ 1513 APP_sw186_minTemperature 1;
BA_ "GenSigSNA" SG_ 1513 APP_sw186_minTemperature "255";
BA_ "Confidence" SG_ 1513 APP_sw186_maxTemperature 1;
BA_ "GenSigSNA" SG_ 1513 APP_sw186_maxTemperature "255";
BA_ "Confidence" SG_ 1513 APP_sw187_exitStatus 1;
BA_ "Confidence" SG_ 1513 APP_sw187_tempMonitorFailure 1;
BA_ "Confidence" SG_ 1513 APP_sw187_imagerHeartbeat 1;
BA_ "GenSigSNA" SG_ 1513 APP_sw187_imagerHeartbeat "3";
BA_ "Confidence" SG_ 1513 APP_sw187_serializerCrcErrCount 1;
BA_ "GenSigSNA" SG_ 1513 APP_sw187_serializerCrcErrCount "255";
BA_ "Confidence" SG_ 1513 APP_sw187_currentTemperature 1;
BA_ "GenSigSNA" SG_ 1513 APP_sw187_currentTemperature "255";
BA_ "Confidence" SG_ 1513 APP_sw187_minTemperature 1;
BA_ "GenSigSNA" SG_ 1513 APP_sw187_minTemperature "255";
BA_ "Confidence" SG_ 1513 APP_sw187_maxTemperature 1;
BA_ "GenSigSNA" SG_ 1513 APP_sw187_maxTemperature "255";
BA_ "Confidence" SG_ 1513 APP_sw188_exitStatus 1;
VAL_ 1360 ADSP_alertID 84 "w084_sharc1LowCpuUsage" 83 "w083_sharc0LowCpuUsage" 80 "w080_micInitError" 77 "w077_mediaMathExcept" 76 "w076_activeSafetyChannelUnderrun" 75 "w075_tdspArmError" 74 "w074_tdspArmXrun" 73 "w073_romFLError" 72 "w072_turnSignalChannelUnderrun" 71 "w071_versionMismatch" 70 "w070_baseamp3Fault" 69 "w069_baseamp2Fault" 68 "w068_baseamp1Fault" 67 "w067_baseamp0Fault" 66 "w066_rearPwsFault" 65 "w065_tcuGpioExpanderCriticalError" 61 "w061_tcuGpioServiceError" 60 "w060_baseamp3SmFault" 59 "w059_nvmmError" 58 "w058_hfpMathExcept2INF" 57 "w057_hfpMathExcept2NAN" 56 "w056_hfpMathExcept1INF" 55 "w055_hfpMathExcept1NAN" 54 "w054_canethRxError" 53 "w053_audioSystemUnavailable" 52 "w052_criticalReset" 51 "w051_extspkFailure" 50 "w050_extSpkFault" 49 "w049_sae" 48 "w048_eCallSelfTestFailed" 47 "w047_sharc1AweFrameOverload" 46 "w046_sharc0AweFrameOverload" 45 "w045_ancEnableFail" 44 "w044_canethChecksum" 43 "w043_aweControlError" 42 "w042_twiReadError" 41 "w041_twiWriteError" 40 "w040_socSciHeartbeat" 39 "w039_ancPing" 38 "w038_a2bbIdleFailed" 37 "w037_a2baIdleFailed" 36 "w036_a2bbFault" 35 "w035_a2baFault" 34 "w034_a2bbDiscoveryFailed" 33 "w033_a2baDiscoveryFailed" 32 "w032_baseamp2SmFault" 31 "w031_baseamp1SmFault" 30 "w030_ethSysErr" 29 "w029_baseamp0SmFault" 28 "w028_ethTcpErr" 27 "w027_ethUdpErr" 26 "w026_ethIcmpErr" 25 "w025_ethIpErr" 24 "w024_ethIpfragErr" 23 "w023_ethEtharpErr" 22 "w022_emacErr" 21 "w021_usbTxAborted" 20 "w020_usbTxFailed" 19 "w019_usbTxUnderrun" 18 "w018_usbTxOverrun" 17 "w017_usbRxUnderrun" 16 "w016_usbRxOverrun" 15 "w015_eavbUnderrun" 14 "w014_eavbOverrun" 13 "w013_sharc1HighCpuUsage" 12 "w012_sharc0HighCpuUsage" 11 "w011_armHighCpuUsage" 10 "w010_12vAudioFiltLow" 8 "w008_internalTempHigh" 7 "w007_ethLinkErr" 6 "w006_eavbSeqno" 5 "w005_stackOverflow" 4 "w004_malloc" 3 "w003_assert" 2 "w002_exception" 1 "w001_flashInit" 0 "ALERT_DO_NOT_USE_ZERO" ;
VAL_ 1360 ADSP_alertState 1 "SET" 0 "CLEARED" ;
VAL_ 1360 ADSP_a002_cause 9 "WDOG_TASK_EXPIRED" 8 "FREERTOS_HOOK" 7 "ARM_FATAL" 6 "SHARC_ASSERTION" 5 "SHARC_CCES_FATAL" 4 "WDOG1_EXPIRED" 3 "WDOG0_EXPIRED" 2 "PREFETCH_ABORT" 1 "DATA_ABORT" 0 "UNKNOWN" ;
VAL_ 1360 ADSP_a022_error 7 "TX_STOP" 6 "JABBER_TO" 5 "TX_BUF_UNAVAIL" 4 "RX_BUF_UNAVAIL" 3 "RX_STOP" 2 "RX_WD_TO" 1 "BUS_ERR" 0 "NONE" ;
VAL_ 1360 ADSP_a035_a2baIntrType 255 "MSTR_RUNNING" 254 "STANDBY_DONE" 253 "SLAVE_INTTYPE_ERR" 252 "STRTUP_ERR_RTF" 251 "NONE" 128 "IRPT_MSG_ERR" 51 "MBOX1_EMPTY" 50 "MBOX1_FULL" 49 "MBOX0_EMPTY" 48 "MBOX0_FULL" 42 "PWRERR_NON_LOCALIZED_SHORT_VBAT" 41 "PWRERR_NON_LOCALIZED_SHORT_GND" 26 "ICRCERR" 25 "I2CERR" 24 "DSCDONE" 23 "IO7PND" 22 "IO6PND" 21 "IO5PND" 20 "IO4PND" 19 "IO3PND" 18 "IO2PND" 17 "IO1PND" 16 "IO0PND" 15 "PWRERR_INDETERMINATE_FAULT" 13 "PWRERR_CABLE_REVERSE_CONNECTED" 12 "PWRERR_CABLE_DISCONNECTED_OR_OPEN_CIRCUIT" 11 "PWRERR_CABLE_SHORTED_TOGETHER" 10 "PWRERR_CABLE_SHORTED_VBAT" 9 "PWRERR_CABLE_SHORTED_GND" 5 "SRFERR" 4 "BIT_ERR_COUNT_OVERFLOW" 3 "DATA_PARITY_ERR" 2 "CRC_ERR" 1 "DATA_DECODING_ERR" 0 "HEADER_COUNT_ERR" ;
VAL_ 1360 ADSP_a035_a2baFaultType 44 "UNKNOWN" 43 "END" 42 "A2B_NOT_LAST_NODE" 41 "A2B_BAD_NODE" 40 "A2B_BUS_REVERSE_CONNECTED" 39 "A2B_BUS_DISCONNECT_OR_OPEN_CIRCUIT" 38 "A2B_BUS_SHORT_TO_VBAT" 37 "A2B_BUS_SHORT_TO_GROUND" 36 "A2B_BUS_NO_FAULT" 35 "A2B_BUS_UNKNOWN_FAULT" 34 "A2B_BUS_INDETERMINATE_FAULT" 33 "A2B_BUS_REVERSED_OR_WRONG_PORT" 32 "A2B_BUS_REVERSED_OR_OPEN" 31 "A2B_BUS_OPEN_OR_WRONG_PORT" 30 "A2B_BUS_SHORT_TOGETHER" 29 "A2B_BUS_NEG_SHORT_TO_VBAT" 28 "A2B_BUS_POS_SHORT_TO_GROUND" 27 "A2B_MEMORY_ERROR" 26 "A2B_I2C_READ_ERROR" 25 "A2B_I2C_WRITE_ERROR" 24 "UNSUPPORTED_PROTOCOL" 23 "UNSUPPORTED_ADDR_BYTES" 22 "UNSUPPORTED_DATA_WIDTH" 21 "UNSUPPORTED_READ_LENGTH" 20 "UNSUPPORTED_INIT_FILE" 19 "CORRUPT_INIT_FILE" 18 "ODD_I2C_ADDRESS_ERROR" 17 "BUS_TIMEOUT" 16 "BUS_ERROR" 15 "CFG_ERROR" 14 "ERROR" 13 "SUCCESS" 12 "STRTUP_ERR_RTF" 11 "BECOVF" 10 "PWRERR_NLS_VBAT" 9 "PWRERR_NLS_GND" 8 "PWRERR_FAULT" 7 "PWRERR_CREV" 6 "PWRERR_CDISC" 5 "PWRERR_CS" 4 "PWRERR_CS_VBAT" 3 "PWRERR_CS_GND" 2 "DISCOVERY_DIAG_TIMEOUT" 1 "BUS_OK" 0 "EMPTY" ;
VAL_ 1360 ADSP_a036_a2bbIntrType 255 "MSTR_RUNNING" 254 "STANDBY_DONE" 253 "SLAVE_INTTYPE_ERR" 252 "STRTUP_ERR_RTF" 251 "NONE" 128 "IRPT_MSG_ERR" 51 "MBOX1_EMPTY" 50 "MBOX1_FULL" 49 "MBOX0_EMPTY" 48 "MBOX0_FULL" 42 "PWRERR_NON_LOCALIZED_SHORT_VBAT" 41 "PWRERR_NON_LOCALIZED_SHORT_GND" 26 "ICRCERR" 25 "I2CERR" 24 "DSCDONE" 23 "IO7PND" 22 "IO6PND" 21 "IO5PND" 20 "IO4PND" 19 "IO3PND" 18 "IO2PND" 17 "IO1PND" 16 "IO0PND" 15 "PWRERR_INDETERMINATE_FAULT" 13 "PWRERR_CABLE_REVERSE_CONNECTED" 12 "PWRERR_CABLE_DISCONNECTED_OR_OPEN_CIRCUIT" 11 "PWRERR_CABLE_SHORTED_TOGETHER" 10 "PWRERR_CABLE_SHORTED_VBAT" 9 "PWRERR_CABLE_SHORTED_GND" 5 "SRFERR" 4 "BIT_ERR_COUNT_OVERFLOW" 3 "DATA_PARITY_ERR" 2 "CRC_ERR" 1 "DATA_DECODING_ERR" 0 "HEADER_COUNT_ERR" ;
VAL_ 1360 ADSP_a036_a2bbFaultType 44 "UNKNOWN" 43 "END" 42 "A2B_NOT_LAST_NODE" 41 "A2B_BAD_NODE" 40 "A2B_BUS_REVERSE_CONNECTED" 39 "A2B_BUS_DISCONNECT_OR_OPEN_CIRCUIT" 38 "A2B_BUS_SHORT_TO_VBAT" 37 "A2B_BUS_SHORT_TO_GROUND" 36 "A2B_BUS_NO_FAULT" 35 "A2B_BUS_UNKNOWN_FAULT" 34 "A2B_BUS_INDETERMINATE_FAULT" 33 "A2B_BUS_REVERSED_OR_WRONG_PORT" 32 "A2B_BUS_REVERSED_OR_OPEN" 31 "A2B_BUS_OPEN_OR_WRONG_PORT" 30 "A2B_BUS_SHORT_TOGETHER" 29 "A2B_BUS_NEG_SHORT_TO_VBAT" 28 "A2B_BUS_POS_SHORT_TO_GROUND" 27 "A2B_MEMORY_ERROR" 26 "A2B_I2C_READ_ERROR" 25 "A2B_I2C_WRITE_ERROR" 24 "UNSUPPORTED_PROTOCOL" 23 "UNSUPPORTED_ADDR_BYTES" 22 "UNSUPPORTED_DATA_WIDTH" 21 "UNSUPPORTED_READ_LENGTH" 20 "UNSUPPORTED_INIT_FILE" 19 "CORRUPT_INIT_FILE" 18 "ODD_I2C_ADDRESS_ERROR" 17 "BUS_TIMEOUT" 16 "BUS_ERROR" 15 "CFG_ERROR" 14 "ERROR" 13 "SUCCESS" 12 "STRTUP_ERR_RTF" 11 "BECOVF" 10 "PWRERR_NLS_VBAT" 9 "PWRERR_NLS_GND" 8 "PWRERR_FAULT" 7 "PWRERR_CREV" 6 "PWRERR_CDISC" 5 "PWRERR_CS" 4 "PWRERR_CS_VBAT" 3 "PWRERR_CS_GND" 2 "DISCOVERY_DIAG_TIMEOUT" 1 "BUS_OK" 0 "EMPTY" ;
VAL_ 1360 ADSP_a053_audioSystemUnavailable 6 "AWE1_NOT_RUNNING" 5 "AWE0_NOT_RUNNING" 4 "CHIME_SYSTEM_FAULT" 3 "EXTERNAL_SPEAKER_CONNECTION_FAULT" 2 "EXTERNAL_SPEAKER_BASEAMP_NOT_AVAILABLE" 1 "EXTERNAL_SPEAKER_BASEAMP_FAULT" 0 "NONE" ;
VAL_ 1360 ADSP_a067_baseamp0Fault 7 "OTHER" 6 "DC" 5 "UNDER_VOLTAGE" 4 "OVER_VOLTAGE" 3 "OVER_CURRENT" 2 "CLOCK_PLL" 1 "OVER_TEMP" 0 "NONE" ;
VAL_ 1360 ADSP_a068_baseamp1Fault 7 "OTHER" 6 "DC" 5 "UNDER_VOLTAGE" 4 "OVER_VOLTAGE" 3 "OVER_CURRENT" 2 "CLOCK_PLL" 1 "OVER_TEMP" 0 "NONE" ;
VAL_ 1360 ADSP_a069_baseamp2Fault 7 "OTHER" 6 "DC" 5 "UNDER_VOLTAGE" 4 "OVER_VOLTAGE" 3 "OVER_CURRENT" 2 "CLOCK_PLL" 1 "OVER_TEMP" 0 "NONE" ;
VAL_ 1360 ADSP_a070_baseamp3Fault 7 "OTHER" 6 "DC" 5 "UNDER_VOLTAGE" 4 "OVER_VOLTAGE" 3 "OVER_CURRENT" 2 "CLOCK_PLL" 1 "OVER_TEMP" 0 "NONE" ;
VAL_ 1360 ADSP_a071_versionMismatch 1 "MISMATCH" 0 "MATCH" ;
VAL_ 1360 ADSP_a080_micInitError 3 "MISMATCH" 2 "SET_FAILED" 1 "UNKNOWN_TYPE" 0 "NO_ERROR" ;
VAL_ 1383 ADSP_a2baState 19 "INTERRUPT" 18 "PRE_IDLE" 17 "BUS_PARTIAL" 16 "REDISCOVER_RETRY_WAIT" 15 "BUS_DOWN" 14 "COMMAND_START" 13 "COMMAND_STOP" 12 "BUS_ECALL" 11 "BUS_IDLE" 10 "EXT_REQ" 9 "NODE_TEST" 8 "GOING_DOWN" 7 "DISCOVER_RETRY" 6 "DIAG" 5 "IDLE" 4 "DISCOVER_WAIT" 3 "DISCOVER" 2 "RESTART" 1 "DOWN" 0 "INIT" ;
VAL_ 1383 ADSP_a2bbState 19 "INTERRUPT" 18 "PRE_IDLE" 17 "BUS_PARTIAL" 16 "REDISCOVER_RETRY_WAIT" 15 "BUS_DOWN" 14 "COMMAND_START" 13 "COMMAND_STOP" 12 "BUS_ECALL" 11 "BUS_IDLE" 10 "EXT_REQ" 9 "NODE_TEST" 8 "GOING_DOWN" 7 "DISCOVER_RETRY" 6 "DIAG" 5 "IDLE" 4 "DISCOVER_WAIT" 3 "DISCOVER" 2 "RESTART" 1 "DOWN" 0 "INIT" ;
VAL_ 1383 ADSP_baseamp0State 7 "LDSHD_SELF_TEST" 6 "DIAG" 5 "OFF" 4 "TURN_OFF" 3 "HALT" 2 "ENABLED" 1 "CONFIGURED" 0 "INIT" ;
VAL_ 1383 ADSP_baseamp1State 7 "LDSHD_SELF_TEST" 6 "DIAG" 5 "OFF" 4 "TURN_OFF" 3 "HALT" 2 "ENABLED" 1 "CONFIGURED" 0 "INIT" ;
VAL_ 1383 ADSP_baseamp2State 7 "LDSHD_SELF_TEST" 6 "DIAG" 5 "OFF" 4 "TURN_OFF" 3 "HALT" 2 "ENABLED" 1 "CONFIGURED" 0 "INIT" ;
VAL_ 1383 ADSP_baseamp3State 7 "LDSHD_SELF_TEST" 6 "DIAG" 5 "OFF" 4 "TURN_OFF" 3 "HALT" 2 "ENABLED" 1 "CONFIGURED" 0 "INIT" ;
VAL_ 1383 ADSP_ancState 4 "DISABLED" 3 "ENABLED" 2 "DSP_ON" 1 "DSP_OFF" 0 "INIT" ;
VAL_ 1383 ADSP_sourceSelect 3 "PINK" 2 "SINE" 1 "TUNER" 0 "MEDIA" ;
VAL_ 1383 ADSP_tunerSelect 1 "XM" 0 "FM" ;
VAL_ 1383 ADSP_ancMode 22 "UNKNOWN" 21 "CALIBRATING_80" 20 "CALIBRATING_60" 19 "CALIBRATING_40" 18 "CALIBRATING_20" 17 "DISABLED_REASON_SENSOR_IMBALANCE" 16 "DISABLED_REASON_MUSIC_LOUD" 15 "DISABLED_REASON_FRUNK_OPEN" 14 "DISABLED_REASON_DOOR_OPEN" 13 "DISABLED_REASON_ACCELS" 12 "DISABLED_REASON_PARKED" 11 "DISABLED_REASON_WINDOW_OPEN" 10 "DISABLED_REASON_REAR_OCCUPANT" 9 "DISABLED_REASON_SEAT_MOVING" 8 "DISABLED_REASON_HVAC" 7 "DISABLED_REASON_CLOSURE_OPEN" 6 "DISABLED_REASON_A2BB" 5 "DISABLED_REASON_A2BA" 4 "CALIBRATING_00" 3 "ALL" 2 "REAR" 1 "FRONT" 0 "OFF" ;
VAL_ 1383 ADSP_eCall_ENS_state 5 "NORMAL" 4 "EMERGENCY" 3 "SOURCE_ERROR" 2 "SOURCE_MISSING" 1 "SIGNAL_ERROR" 0 "UNKOWN" ;
VAL_ 1383 ADSP_eCallSelfTest 2 "FAILED" 1 "PASSED" 0 "NOT_RUN_YET" ;
VAL_ 1383 ADSP_eCallState 1 "ACTIVE" 0 "INACTIVE" ;
VAL_ 1383 ADSP_eCallMicrophoneStatus 2 "FAILED" 1 "PASSED" 0 "NOT_RUN_YET" ;
VAL_ 1383 ADSP_eCallSpeakerStatus 3 "FAILED_DIAG" 2 "FAILED_DISCONNECT" 1 "PASSED" 0 "NOT_RUN_YET" ;
VAL_ 1383 ADSP_requestFailoverSpeaker 1 "TRUE" 0 "FALSE" ;
VAL_ 1383 ADSP_microphoneDataState 1 "A2B_DOWN" 0 "VALID" ;
VAL_ 600 APB_watchdogState 7 "AP_WDOG_STATE_SNA" 4 "AP_WDOG_STATE_SHUTTING_DOWN" 3 "AP_WDOG_STATE_HEALTHY" 2 "AP_WDOG_STATE_CRITICAL" 1 "AP_WDOG_STATE_DEGRADED" 0 "AP_WDOG_STATE_UNKNOWN" ;
VAL_ 600 APB_fusedState 3 "APP_FUSE_SNA" 2 "APP_FUSE_FUSED" 1 "APP_FUSE_UNFUSED" 0 "APP_FUSE_UNKNOWN" ;
VAL_ 600 APB_factorySummonStatus 8 "FACTORY_SUMMON_END_OF_ROUTE" 7 "FACTORY_SUMMON_UNAVAILABLE_HEADING_NOT_INITIALIZED" 6 "FACTORY_SUMMON_UNAVAILABLE_VEHICLE_SPEED_INVALID" 5 "FACTORY_SUMMON_UNAVAILABLE_NO_GPS" 4 "FACTORY_SUMMON_UNAVAILABLE_GOAL_TOO_FAR" 3 "FACTORY_SUMMON_UNAVAILABLE_NO_QR_INSTRUCTION" 2 "FACTORY_SUMMON_AVAILABLE" 1 "FACTORY_SUMMON_ACTIVE" 0 "FACTORY_SUMMON_SNA" ;
VAL_ 600 APB_clipRecordingStatus 4 "APP_CLIP_FAULTED" 3 "APP_CLIP_TRIGGERED" 2 "APP_CLIP_RECORDING" 1 "APP_CLIP_IDLE" 0 "APP_CLIP_NO_DRIVE" ;
VAL_ 600 APB_summonUnavailableReason 28 "SMART_SUMMON_UNAVAILABLE_OUTSIDE_GEOFENCE" 27 "SMART_SUMMON_UNAVAILABLE_ACCEL_PEDAL_PRESSED" 26 "SMART_SUMMON_UNAVAILABLE_BRAKE_PEDAL_PRESSED" 25 "SMART_SUMMON_UNAVAILABLE_REMOTE_STOP_OR_ABORT_REQUEST_ACTIVE" 24 "SMART_SUMMON_UNAVAILABLE_CLOSURE_OPEN" 23 "SMART_SUMMON_UNAVAILABLE_LOW_TIRE_PRESSURE" 22 "SMART_SUMMON_UNAVAILABLE_EXTENDED_COMPUTE_INACTIVE" 21 "SMART_SUMMON_UNAVAILABLE_HIGH_GRADE" 20 "SMART_SUMMON_UNAVAILABLE_NO_CONTEXT" 19 "SMART_SUMMON_UNAVAILABLE_PUBLIC_ROAD_BOUNDARIES_NOT_VALID" 18 "SMART_SUMMON_UNAVAILABLE_ALL_SENSORS_OCCLUDED" 17 "SMART_SUMMON_UNAVAILABLE_ULTRASONIC_STALE" 16 "SMART_SUMMON_UNAVAILABLE_VISION_HEALTH_CRITICAL" 15 "SMART_SUMMON_UNAVAILABLE_CAMERA_NOT_CALIBRATED" 14 "SMART_SUMMON_UNAVAILABLE_END_OF_LEASH" 13 "SMART_SUMMON_UNAVAILABLE_PHONE_IS_TOO_FAR" 12 "SMART_SUMMON_UNAVAILABLE_EGO_GPS_UNAVAILABLE" 11 "SMART_SUMMON_UNAVAILABLE_PHONE_GPS_UNAVAILABLE" 10 "SMART_SUMMON_UNAVAILABLE_POOR_CONNECTION" 9 "SMART_SUMMON_UNAVAILABLE_PUBLIC_ROAD" 8 "SMART_SUMMON_UNAVAILABLE_EAC_UNAVAILABLE" 7 "SMART_SUMMON_UNAVAILABLE_CRUISE_UNAVAILABLE" 6 "SMART_SUMMON_UNAVAILABLE_ULTRASONIC_FAULT" 5 "SMART_SUMMON_UNAVAILABLE_ULTRASONIC_BLOCKED" 4 "SMART_SUMMON_UNAVAILABLE_CAMERA_BLOCKED" 3 "SMART_SUMMON_UNAVAILABLE_CAMERA_STREAM" 2 "SMART_SUMMON_UNAVAILABLE_NOT_IN_PARK" 1 "SMART_SUMMON_UNAVAILABLE_NONE" 0 "SMART_SUMMON_UNAVAILABLE_UNKNOWN" ;
VAL_ 600 APB_fsdSuspendState 3 "SNA" 1 "SUSPENDED" 0 "NOT_SUSPENDED" ;
VAL_ 600 APB_fsdRevokeStrikeoutCount 7 "SNA" ;
VAL_ 600 APB_teslaVisionSupported 3 "SNA" 1 "SUPPORTED" 0 "NOT_SUPPORTED" ;
VAL_ 600 APB_teslaVisionUnsupportedReason 4 "VEHICLE_LOCATION" 3 "UNSUPPORTED_CAMERA" 2 "AP_HARDWARE" 1 "NONE" 0 "UNKNOWN" ;
VAL_ 600 APB_fsdRevokeCount 7 "SNA" ;
VAL_ 600 APB_unifiedObjectStackSupported 3 "SNA" 1 "SUPPORTED" 0 "NOT_SUPPORTED" ;
VAL_ 600 APB_DDAWSystemStatus 4 "DDAW_SYSTEM_SNA" 3 "DDAW_SYSTEM_INVALID" 2 "DDAW_SYSTEM_FAILURE" 1 "DDAW_SYSTEM_DRIVER_DROWSY" 0 "DDAW_SYSTEM_NOMINAL" ;
VAL_ 600 APB_socOperatingMode 2 "AP_DUAL_SOC" 1 "AP_SINGLE_SOC" 0 "AP_UNKNOWN" ;
VAL_ 600 APB_summonVersionIdentifier 2 "AUTONOMY_SUMMON" 1 "ACTUALLY_SMART_SUMMON" 0 "LEGACY_SMART_SUMMON" ;
VAL_ 600 APB_sentryState 6 "SENTRY_SNA" 5 "SENTRY_QUIET" 4 "SENTRY_PANIC" 3 "SENTRY_AWARE" 2 "SENTRY_ARMED" 1 "SENTRY_IDLE" 0 "SENTRY_OFF" ;
VAL_ 600 APB_autoparkVersionIdentifier 2 "ACTUALLY_SMART_AUTOPARK" 1 "V3_VISION_AUTOPARK" 0 "LEGACY_AUTOPARK" ;
VAL_ 600 APB_autonomySystemHealth 1 "AUTONOMY_SYSTEM_HEALTH_HEALTHY" 0 "AUTONOMY_SYSTEM_HEALTH_UNHEALTHY" ;
VAL_ 909 APP_inTunnel 2 "NOT_IN_TUNNEL" 1 "IN_TUNNEL" 0 "IN_TUNNEL_SNA" ;
VAL_ 909 APP_windshieldHeaterOnReason 8 "WINDSHIELD_HEATER_ON_REASON_WIPERS_ACTIVE" 7 "WINDSHIELD_HEATER_ON_REASON_HVAC_REQUESTED" 6 "WINDSHIELD_HEATER_ON_REASON_OVERRIDE" 5 "WINDSHIELD_HEATER_ON_REASON_OFF" 4 "WINDSHIELD_HEATER_ON_REASON_STARTUP" 3 "WINDSHIELD_HEATER_ON_REASON_CONDENSATION_LIKELY" 2 "WINDSHIELD_HEATER_ON_REASON_OCCLUDED" 1 "WINDSHIELD_HEATER_ON_REASON_DEFROST" 0 "WINDSHIELD_HEATER_ON_REASON_SNA" ;
VAL_ 909 APP_selfieCameraBlocked 2 "SELFIE_CAMERA_BLOCKED" 1 "SELFIE_CAMERA_NOT_BLOCKED" 0 "SELFIE_CAMERA_BLOCKED_SNA" ;
VAL_ 909 APP_selfieCameraLUX 255 "SNA" 254 "SATURATED" ;
VAL_ 909 APP_sceneTagClearlyRaining 2 "NOT_ACTIVATED" 1 "ACTIVATED" 0 "SNA" ;
VAL_ 909 APP_sceneTagFog 2 "NOT_ACTIVATED" 1 "ACTIVATED" 0 "SNA" ;
VAL_ 909 APP_sceneTagFullyBlocked 2 "NOT_ACTIVATED" 1 "ACTIVATED" 0 "SNA" ;
VAL_ 909 APP_sceneTagIndoors 2 "NOT_ACTIVATED" 1 "ACTIVATED" 0 "SNA" ;
VAL_ 909 APP_sceneTagLensFlare 2 "NOT_ACTIVATED" 1 "ACTIVATED" 0 "SNA" ;
VAL_ 909 APP_sceneTagRaining 2 "NOT_ACTIVATED" 1 "ACTIVATED" 0 "SNA" ;
VAL_ 909 APP_sceneTagSevereWeather 2 "NOT_ACTIVATED" 1 "ACTIVATED" 0 "SNA" ;
VAL_ 909 APP_sceneTagSnowing 2 "NOT_ACTIVATED" 1 "ACTIVATED" 0 "SNA" ;
VAL_ 909 APP_sceneTagSnowyRoad 2 "NOT_ACTIVATED" 1 "ACTIVATED" 0 "SNA" ;
VAL_ 909 APP_sceneTagSunGlare 2 "NOT_ACTIVATED" 1 "ACTIVATED" 0 "SNA" ;
VAL_ 909 APP_sceneTagTunnel 2 "NOT_ACTIVATED" 1 "ACTIVATED" 0 "SNA" ;
VAL_ 909 APP_sceneTagWetRoad 2 "NOT_ACTIVATED" 1 "ACTIVATED" 0 "SNA" ;
VAL_ 909 APP_fisheyeInPathVisibility 4 "VISIBILITY_CONDITION_NOMINAL" 3 "VISIBILITY_OCCLUDED_LOW_SEVERITY" 2 "VISIBILITY_OCCLUDED_MEDIUM_SEVERITY" 1 "VISIBILITY_OCCLUDED_HIGH_SEVERITY" 0 "VISIBILITY_CONDITION_SNA" ;
VAL_ 909 APP_fisheyeOverallVisibility 4 "VISIBILITY_CONDITION_NOMINAL" 3 "VISIBILITY_OCCLUDED_LOW_SEVERITY" 2 "VISIBILITY_OCCLUDED_MEDIUM_SEVERITY" 1 "VISIBILITY_OCCLUDED_HIGH_SEVERITY" 0 "VISIBILITY_CONDITION_SNA" ;
VAL_ 909 APP_mainInPathVisibility 4 "VISIBILITY_CONDITION_NOMINAL" 3 "VISIBILITY_OCCLUDED_LOW_SEVERITY" 2 "VISIBILITY_OCCLUDED_MEDIUM_SEVERITY" 1 "VISIBILITY_OCCLUDED_HIGH_SEVERITY" 0 "VISIBILITY_CONDITION_SNA" ;
VAL_ 909 APP_mainOverallVisibility 4 "VISIBILITY_CONDITION_NOMINAL" 3 "VISIBILITY_OCCLUDED_LOW_SEVERITY" 2 "VISIBILITY_OCCLUDED_MEDIUM_SEVERITY" 1 "VISIBILITY_OCCLUDED_HIGH_SEVERITY" 0 "VISIBILITY_CONDITION_SNA" ;
VAL_ 909 APP_narrowInPathVisibility 4 "VISIBILITY_CONDITION_NOMINAL" 3 "VISIBILITY_OCCLUDED_LOW_SEVERITY" 2 "VISIBILITY_OCCLUDED_MEDIUM_SEVERITY" 1 "VISIBILITY_OCCLUDED_HIGH_SEVERITY" 0 "VISIBILITY_CONDITION_SNA" ;
VAL_ 909 APP_narrowOverallVisibility 4 "VISIBILITY_CONDITION_NOMINAL" 3 "VISIBILITY_OCCLUDED_LOW_SEVERITY" 2 "VISIBILITY_OCCLUDED_MEDIUM_SEVERITY" 1 "VISIBILITY_OCCLUDED_HIGH_SEVERITY" 0 "VISIBILITY_CONDITION_SNA" ;
VAL_ 909 APP_frontCamOcclusionType 6 "UNKNOWN_OCCLUSION" 5 "DEW" 4 "STREAK" 3 "SUN_GLARE" 2 "DIRTY_OR_BLOCKED" 1 "CONDENSATION" 0 "OFFGASSING" ;
VAL_ 1513 APP_alertID 483 "w483_apbVisionFailoverActivated" 482 "w482_appVisionFailoverActivated" 478 "w478_runModeSwitch" 477 "w477_driverSeatReclined" 467 "w467_imuDegraded" 466 "w466_missingSensorOTP" 465 "w465_autonomyDegradedODD" 464 "w464_autonomyUnavailableODD" 463 "w463_selfDrivingCamObstrcted" 462 "w462_selfDrivingUnavailable" 461 "w461_autonomyReroute" 460 "w460_epblMiaChBus" 459 "w459_epbrMiaPartyBus" 458 "w458_aceEvent" 457 "w457_autonomyDegradedCollision" 456 "w456_autonomyUnavailableCollision" 455 "w455_apbAutonomySystemUnhealthy" 454 "w454_appAutonomySystemUnhealthy" 453 "w453_driverCancelBlinker" 452 "w452_selfieImagerConfigMismatch" 451 "w451_fasciaImagerConfigMismatch" 450 "w450_backupImagerConfigMismatch" 449 "w449_rightRepeaterImagerConfigMismatch" 448 "w448_leftRepeaterImagerConfigMismatch" 447 "w447_rightPillarImagerConfigMismatch" 446 "w446_leftPillarImagerConfigMismatch" 445 "w445_fisheyeImagerConfigMismatch" 444 "w444_narrowImagerConfigMismatch" 443 "w443_mainImagerConfigMismatch" 442 "w442_autonomyCancelMethod" 441 "w441_cabinCamLEDRailOff" 440 "w440_lensHoodOcclusion" 439 "w439_ethernetCommFailure" 438 "w438_rcuMia" 437 "w437_missingCloudEepromData" 436 "w436_camCsiError" 435 "w435_repeaterAeroRibInfoMismatched" 434 "w434_rightRepeaterDowngradeDetected" 433 "w433_leftRepeaterDowngradeDetected" 432 "w432_frontVisibilityDegraded_HIGH" 431 "w431_frontVisibilityDegraded_MEDIUM" 430 "w430_frontVisibilityDegraded_LOW" 429 "w429_cameraVisPopUpFascia" 428 "w428_cameraVisPopUpBackup" 427 "w427_cameraVisPopUpRRepeater" 426 "w426_cameraVisPopUpLRepeater" 425 "w425_cameraVisPopUpRPillar" 424 "w424_cameraVisPopUpLPillar" 423 "w423_cameraVisPopUpForward" 422 "w422_autonomyDegradedUser" 421 "w421_autonomyUnavailableUser" 420 "w420_autonomyDegradedApSystem" 419 "w419_autonomyUnavailableApSystem" 418 "w418_autonomyDegradedVisibility" 417 "w417_autonomyUnavailableVisibility" 416 "w416_autonomyDegradedSystem" 415 "w415_autonomyUnavailableSystem" 413 "w413_autonomyDegraded5" 412 "w412_abortBackupCamOccluded" 411 "w411_backupCameraOccluded" 410 "w410_autonomyDegraded4" 409 "w409_autonomyDegraded3" 408 "w408_autonomyDegraded2" 407 "w407_autonomyDegraded1" 406 "w406_gnssHWHealthDegraded" 405 "w405_apsMia" 404 "w404_epbrMiaVehBus" 403 "w403_notifyCameraSelfCleanAction" 402 "w402_rightPillarCameraHeaterFaulted" 401 "w401_leftPillarCameraHeaterFaulted" 400 "w400_selfieCameraFanFault" 399 "w399_brakeboosterMia" 398 "w398_imuOutputUnhealthy" 397 "w397_apFeatDisabledPermanent" 396 "w396_severeResidueDetected" 395 "w395_cabinCameraLEDFaultSvc" 394 "w394_apImuGrossErrors" 393 "w393_attnMntrUnavailable" 392 "w392_fsdSuspended" 391 "w391_cabinCameraBlockedonAP" 390 "w390_cabinCamVisDegraded" 389 "w389_camFovResidueDetected" 388 "w388_windshieldCameraHeaterFaulted" 387 "w387_radarBlockageDetected" 386 "w386_radarOnlyBrakingEvent" 385 "w385_posEngineUnhealthy" 384 "w384_posEngineInitInMotion" 383 "w383_manyApRebootsWhileInP" 382 "w382_ubloxImuTimestampIssue" 381 "w381_apImuTimestampIssue" 380 "w380_gnssPpsTimestampIssue" 379 "w379_positioningEngineMia" 378 "w378_ubloxImuMia" 377 "w377_apImuMia" 376 "w376_wheeltickCountMia" 375 "w375_gnssPpsMia" 374 "w374_gnssDataMia" 373 "w373_gnssUartError" 372 "w372_cabinCameraBlocked" 371 "w371_networkLoadingIssue" 370 "w370_accApUnavUserSettings" 369 "w369_cruiseWithSingleClick" 368 "w368_fasciaCamTypeMismatch" 367 "w367_fasciaCamCalSaved" 366 "w366_fasciaCameraSyncFailed" 365 "w365_fasciaCamExtNotCal" 364 "w364_fasciaCameraTypeError" 363 "w363_fasciaCameraStreamExit" 362 "w362_fasciaCamInitFault" 361 "w361_cabinCameraLEDFault" 360 "w360_apImuNoiseDetected" 359 "w359_aebDegraded" 358 "w358_isaSystemFault" 357 "w357_ddawSystemFault" 356 "w356_driverOverriding" 355 "w355_camQuadPowerFault" 354 "w354_tradfcMia" 353 "w353_csiDevice2Down" 352 "w352_csiDevice1Down" 351 "w351_csiDevice0Down" 350 "w350_tradfcSensorMisaligned" 349 "w349_cameraPersistentlyFaulted" 348 "w348_cameraSwUpdateRequired" 347 "w347_vcbattMiaVehBus" 346 "w346_gpsSwEvent" 345 "w345_tradfcPerfDegraded" 344 "w344_tradfcDspAlgoTimeout" 343 "w343_tradfcDspSwError" 342 "w342_tradfcDspHwError" 341 "w341_tradfcCalibError" 340 "w340_tradfcCsiError" 339 "w339_tradfcRfTempError" 338 "w338_tradfcLfTempError" 337 "w337_tradfcRfPmicError" 336 "w336_tradfcLfPmicError" 335 "w335_tradfcRfSensorError" 334 "w334_frontCameraOccluded" 333 "w333_fsdUnavailableLocation" 332 "w332_cameraPositionsSwapped" 331 "w331_fsdDegradedUnavailable" 330 "w330_cabinCameraFault" 329 "w329_evasiveManeuver" 328 "w328_autoparkDegraded" 327 "w327_vehicleConfigMismatch" 326 "w326_kernelPanic" 325 "w325_watchdogReset" 324 "w324_adspMia" 323 "w323_drivableSpaceFCW" 322 "w322_autoWiperWash" 321 "w321_bmsMia" 320 "w320_selfieCamTypeMismatch" 319 "w319_backupCamTypeMismatch" 318 "w318_rRepeatCamTypeMismatch" 317 "w317_lRepeatCamTypeMismatch" 316 "w316_rPillarCamTypeMismatch" 315 "w315_lPillarCamTypeMismatch" 314 "w314_fisheyeCamTypeMismatch" 313 "w313_narrowCamTypeMismatch" 312 "w312_mainCamTypeMismatch" 311 "w311_eth1FrameErrors" 310 "w310_eth0FrameErrors" 309 "w309_selfieDisabledOnCar" 308 "w308_iboosterMia" 307 "w307_lssTurnSignalFault" 306 "w306_lssUltrasonicsBlocked" 305 "w305_lssCamStreamExit" 304 "w304_lssCamBlockedStatus" 303 "w303_imuIrational" 302 "w302_vcfrontMiaPartyBus" 301 "w301_selfieCameraSyncFailed" 300 "w300_backupCameraSyncFailed" 299 "w299_rRepeatCameraSyncFailed" 298 "w298_lRepeatCameraSyncFailed" 297 "w297_rPillarCameraSyncFailed" 296 "w296_lPillarCameraSyncFailed" 295 "w295_fisheyeCameraSyncFailed" 294 "w294_narrowCameraSyncFailed" 293 "w293_mainCameraSyncFailed" 291 "w291_stopSignWarning" 290 "w290_dramUncorrEccErrors" 289 "w289_dramCorrEccErrors" 288 "w288_trafficLightWarning" 287 "w287_gpsFusionStatus" 286 "w286_gpsComIssue" 285 "w285_gpsFaultReset" 284 "w284_gpsAntennaDisconnected" 283 "w283_enhancedSummonAbort" 282 "w282_selfieCameraStreamErr" 281 "w281_backupCameraStreamErr" 280 "w280_rRepeatCameraStreamErr" 279 "w279_lRepeatCameraStreamErr" 278 "w278_rPillarCameraStreamErr" 277 "w277_lPillarCameraStreamErr" 276 "w276_fisheyeCameraStreamErr" 275 "w275_narrowCameraStreamErr" 274 "w274_mainCameraStreamErr" 273 "w273_lssEvent" 272 "w272_laneChangeUnavailable" 271 "w271_laneChangeAborted" 270 "w270_blindspotRestricted" 269 "w269_autopilotLimited" 268 "w268_backupCamExtNotCal" 267 "w267_benchtopEcu" 266 "w266_visionScheduleFallback" 265 "w265_drvOnNavUnavailable" 264 "w264_lssFault" 263 "w263_lssAbort" 262 "w262_apeCalibMode" 261 "w261_pcieHardwareErrors" 260 "w260_collisionWarningEvent" 259 "w259_aebOverrideEvent" 258 "w258_aebEvent" 257 "w257_brakeJerkEvent" 235 "w235_fsdRegionNotAllowed" 234 "w234_activeSafetyTelemetry" 233 "w233_fsdQuizRequired" 232 "w232_laneChangeRequested" 231 "w231_idfEvent" 230 "w230_alcUltrasoundBlocked" 229 "w229_alcUltrasoundDamaged" 228 "w228_DEPRECATED" 227 "w227_virtualWallBlocked" 226 "w226_lcCamCalNeededSpeedLmt" 225 "w225_lcDegradedVisSpeedLmt" 224 "w224_accCameraCalibration" 223 "w223_accObjectInPath" 222 "w222_accCameraBlind" 221 "w221_accRadarBlind" 220 "w220_lcTempUnavailableRoad" 219 "w219_lcTempUnavailableSpeed" 218 "w218_lcSpeedExceededLimit" 217 "w217_lcUnavailableSpeeding" 216 "w216_driverOverriding" 215 "w215_contDriverNotIntracting" 214 "w214_driverNotIntracting" 213 "w213_autosteerStruckOut" 212 "w212_lcUnavailableStrikeOut" 211 "w211_accNoSeatBelt" 210 "w210_camObstrcted" 209 "w209_autoSummonRequest" 208 "w208_rackDetected" 207 "w207_autosteerUnavailable" 206 "w206_autosteerNotEnabled" 205 "w205_apcFinalRear" 204 "w204_apcFinalFront" 203 "w203_apcActivation" 202 "w202_scwNoisyEnvironment" 201 "w201_lcAborting" 200 "w200_lcSlowdown" 199 "w199_apcAbort" 198 "w198_tsrUnavailable" 197 "w197_redLightWarning" 196 "w196_stopSignWarning" 195 "w195_scwUnavailable" 194 "w194_accDriverResumeRqrd" 193 "w193_camWindshieldUnclean" 192 "w192_emergencySpeakerFail" 191 "w191_autopilotAborting" 190 "w190_selfieCameraStreamExit" 189 "w189_backupCameraStreamExit" 188 "w188_rRepeatCameraStreamExit" 187 "w187_lRepeatCameraStreamExit" 186 "w186_rPillarCameraStreamExit" 185 "w185_lPillarCameraStreamExit" 184 "w184_fisheyeCameraStreamExit" 183 "w183_narrowCameraStreamExit" 182 "w182_mainCameraStreamExit" 181 "w181_rRepeatCamCalSaved" 180 "w180_lRepeatCamCalSaved" 179 "w179_rPillarCamCalSaved" 178 "w178_lPillarCamCalSaved" 177 "w177_fisheyeCamCalSaved" 176 "w176_rRepeatCamExtNotCal" 175 "w175_lRepeatCamExtNotCal" 174 "w174_rPillarCamExtNotCal" 173 "w173_lPillarCamExtNotCal" 172 "w172_fisheyeCamExtNotCal" 171 "w171_appHighCoolantFlowReq" 170 "w170_selfieCameraTypeError" 169 "w169_backupCameraTypeError" 168 "w168_rRepeatCameraTypeError" 167 "w167_lRepeatCameraTypeError" 166 "w166_rPillarCameraTypeError" 165 "w165_lPillarCameraTypeError" 164 "w164_fisheyeCameraTypeError" 163 "w163_narrowCameraTypeError" 162 "w162_mainCameraTypeError" 161 "w161_backupCameraUnavailable" 160 "w160_vcrightMiaVehBus" 159 "w159_vcleftMiaVehBus" 158 "w158_vcfrontMiaVehBus" 157 "w157_sccmMiaVehBus" 156 "w156_epblMiaVehBus" 155 "w155_vcrightMiaPartyBus" 154 "w154_vcleftMiaPartyBus" 153 "w153_rcmMiaPartyBus" 152 "w152_espMiaPartyBus" 151 "w151_epasMiaPartyBus" 150 "w150_diMiaPartyBus" 149 "w149_diskFull" 148 "w148_overlayActive" 147 "w147_selfieCamInitFault" 146 "w146_telemetryProblem" 145 "w145_camSelfCalIssue" 144 "w144_fanctrldError" 143 "w143_IDF_event" 142 "w142_fwdCamPitchProblem" 141 "w141_ECU_Thermal_Issue" 140 "w140_backupCamInitFault" 139 "w139_rRepeatCamInitFault" 138 "w138_lRepeatCamInitFault" 137 "w137_rPillarCamInitFault" 136 "w136_lPillarCamInitFault" 135 "w135_fisheyeCamInitFault" 134 "w134_narrowCamInitFault" 133 "w133_mainCamInitFault" 132 "w132_narrowCamCalSaved" 131 "w131_mainCamCalSaved" 130 "w130_narrowCamExtNotCal" 129 "w129_mainCamExtNotCal" 106 "w106_torsionBarOffset" 105 "w105_DEPRECATED" 104 "w104_DEPRECATED" 103 "w103_robExperimentalAEB" 102 "w102_DEPRECATED" 101 "w101_DEPRECATED" 100 "w100_DEPRECATED" 99 "w099_DEPRECATED" 98 "w098_DEPRECATED" 97 "w097_DEPRECATED" 96 "w096_DEPRECATED" 95 "w095_DEPRECATED" 94 "w094_DEPRECATED" 93 "w093_DEPRECATED" 92 "w092_DEPRECATED" 91 "w091_DEPRECATED" 90 "w090_DEPRECATED" 89 "w089_DEPRECATED" 88 "w088_DEPRECATED" 87 "w087_DEPRECATED" 86 "w086_robCollision" 85 "w085_pmmSteering" 84 "w084_pmmIPSO" 83 "w083_inPathRADObject" 82 "w082_inPathFSviolation" 81 "w081_pmmActiveBraking" 80 "w080_accFailedActivation" 79 "w079_edrAvailable" 78 "w078_pmmActive2" 77 "w077_pmmActive" 76 "w076_mobilEyeSetC" 75 "w075_scMia" 74 "w074_inPathStationaryObst" 73 "w073_issueEscalatedLDW" 72 "w072_selfparkComplete" 71 "w071_selfparkStarted" 70 "w070_apcIncompleteCal" 69 "w069_apcSpaceMasked" 68 "w068_vlInconsistency" 67 "w067_steeringAlignment" 66 "w066_deserializerLockLost" 65 "w065_deserializerOvercurrent" 64 "w064_epasMia" 63 "w063_parkVersionMismatch" 62 "w062_radcAlignment" 61 "w061_airSuspensionMia" 60 "w060_fcw_event" 59 "w059_parkMia" 58 "w058_epbMia" 57 "w057_mcuMia" 56 "w056_diMia" 55 "w055_radcVersionMismatch" 54 "w054_camAutofix" 53 "w053_radcCommIssue" 52 "w052_radcSensorIssue" 51 "w051_radcEcuIssue" 50 "w050_aeb_event" 49 "w049_eyeqVersionMismatch" 48 "w048_APP_Features_Disabled" 47 "w047_edrEvent" 46 "w046_eepromRecordAbsent" 45 "w045_radMia" 44 "w044_appMobileyeFailure" 43 "w043_camLongRunTime" 42 "w042_autopilotAborting" 41 "w041_autopilotRateSaturated" 40 "w040_autopilotAngleSaturated" 39 "w039_sdm_rcm_Mia" 38 "w038_camFailure" 37 "w037_camTacIssue" 36 "w036_bdyMia" 35 "w035_espMia" 34 "w034_sccmMia" 33 "w033_gtwMia" 32 "w032_canTxError" 31 "w031_canRxError" 30 "w030_Heater_Issue" 29 "w029_spi_tx_error" 28 "w028_spi_rx_error" 27 "w027_ECU_Reset_Fault" 26 "w026_ECU_timingIssue" 25 "w025_LC_Steering_Override" 24 "w024_ECU_Watchdog_Reset" 23 "w023_ECU_Cam_Statemismatc" 22 "w022_ECU_EEPROM_Failure" 21 "w021_ECU_Temperature_Issue" 20 "w020_ECU_checkstopError" 19 "w019_ECU_Stack_Overflow" 18 "w018_ECU_Power_Issue" 17 "w017_Cam_Msg_MIA" 16 "w016_aeb_e_event" 15 "w015_Camera_Failsafes" 14 "w014_swAssert" 13 "w013_Cam_Watchdog" 12 "w012_Cam_BootFailure" 11 "w011_scaEvent" 10 "w010_radcCalibIssue" 9 "w009_aebFault" 8 "w008_parkDisabled" 7 "w007_ahlbDisabled" 6 "w006_aebCancelled" 5 "w005_fcwCancelled" 4 "w004_accDisabled" 3 "w003_isaDisabled" 2 "w002_ldwDisabled" 1 "w001_DEPRECATED" 0 "ALERT_DO_NOT_USE_ZERO" ;
VAL_ 1513 APP_alertSource 1 "TURBOB" 0 "TURBOA" ;
VAL_ 1513 APP_alertState 1 "SET" 0 "CLEARED" ;
VAL_ 1513 APP_sw025_state_before_override 15 "PARKED_FSD_AVAILABLE" 14 "PARKING" 13 "FULL_ABORTED" 12 "FULL_ABORTING" 11 "AUTOSTEER_ABORTED" 10 "AUTOSTEER_ABORTING" 9 "AUTOSTEER_CANCELING" 8 "AUTOSTEER_ACTIVE" 7 "AUTOSTEER_PREACTIVE" 6 "ACC_ACTIVE_AUTOSTEER_AVAILABLE" 5 "ACC_ACTIVE_AUTOSTEER_UNAVAILABLE" 4 "AUTOSTEER_AVAILABLE" 3 "ACC_AVAILABLE" 2 "UNAVAILABLE" 1 "DISABLED" 0 "FAULT" ;
VAL_ 1513 APP_sw042_health_state 7 "SNA" 6 "UNUSED" 5 "FAULT" 4 "ABORTING" 3 "SEVERELY_DEGRADED" 2 "DEGRADED" 1 "NOMINAL" 0 "UNAVAILABLE" ;
VAL_ 1513 APP_sw042_abort_reason 27 "LC_ABORT_USER_OVERRIDE_STRIKEOUT" 26 "LC_ABORT_SEATBELT_UNBUCKLED" 25 "LC_ABORT_AEB" 24 "LC_ABORT_DRIVE_ON_MAPS" 23 "LC_ABORT_ECU_THERMAL_ISSUE" 22 "LC_ABORT_CRUISE_WENT_UNAVAILABLE" 21 "RR_ABORT_CONTROL_NOT_ALLOWED" 20 "RR_ABORT_CONTROLLER_HEALTH" 19 "RR_ABORT_WATCHDOG_HEALTH_CRITICAL" 18 "LC_ABORT_APP_ME_STATE" 17 "LC_ABORT_ME_MAIN_STATE" 16 "LC_ABORT_CAMERA_MSG_MIA" 15 "LC_ABORT_CAMERA_WATCHDOG" 14 "LC_ABORT_TRAILER_MODE_ACTIVATION" 13 "LC_ABORT_SIDE_COLLISION_IMMINENT" 12 "LC_ABORT_ACC_CANCEL" 11 "LC_ABORT_CAMERA_FAILSAFES" 10 "LC_ABORT_EPAS_ERROR_CODE" 9 "LC_ABORT_PLANNER_OUTPUT_INVALID" 8 "LC_ABORT_FOLLOWER_OUTPUT_INVALID" 7 "LC_ABORT_VEHICLE_SPEED_ABOVE_MAX" 6 "LC_ABORT_HEALTH_MONITOR" 5 "LC_ABORT_DRIVING_OFF_NAV" 4 "LC_ABORT_CID_SWITCH_DISABLED" 3 "LC_ABORT_CRUISE_FAULT" 2 "LC_ABORT_COMPONENT_MIA" 1 "LC_ABORT_EPAS_EAC_DENIED" 0 "LC_ABORT_NONE" ;
VAL_ 1513 APP_sw073_escalateLDWreason 4 "SELFIE" 3 "STW_TAKEOVER" 2 "DOUBLE_PULL" 1 "SINGLE_PULL" 0 "NONE" ;
VAL_ 1513 APP_sw133_mainCamDeserFault 4 "I2C_UNKNOWN_IOCTL_ERR" 3 "I2C_DATA_NACK" 2 "I2C_SLAVE_ADDR_NACK" 1 "I2C_BUS_FAULT" 0 "NO_I2C_FAULT" ;
VAL_ 1513 APP_sw133_mainCamSensorFault 4 "I2C_UNKNOWN_IOCTL_ERR" 3 "I2C_DATA_NACK" 2 "I2C_SLAVE_ADDR_NACK" 1 "I2C_BUS_FAULT" 0 "NO_I2C_FAULT" ;
VAL_ 1513 APP_sw133_mainCamSerFault 4 "I2C_UNKNOWN_IOCTL_ERR" 3 "I2C_DATA_NACK" 2 "I2C_SLAVE_ADDR_NACK" 1 "I2C_BUS_FAULT" 0 "NO_I2C_FAULT" ;
VAL_ 1513 APP_sw134_narrowCamDeserFault 4 "I2C_UNKNOWN_IOCTL_ERR" 3 "I2C_DATA_NACK" 2 "I2C_SLAVE_ADDR_NACK" 1 "I2C_BUS_FAULT" 0 "NO_I2C_FAULT" ;
VAL_ 1513 APP_sw134_narrowCamSensorFault 4 "I2C_UNKNOWN_IOCTL_ERR" 3 "I2C_DATA_NACK" 2 "I2C_SLAVE_ADDR_NACK" 1 "I2C_BUS_FAULT" 0 "NO_I2C_FAULT" ;
VAL_ 1513 APP_sw134_narrowCamSerFault 4 "I2C_UNKNOWN_IOCTL_ERR" 3 "I2C_DATA_NACK" 2 "I2C_SLAVE_ADDR_NACK" 1 "I2C_BUS_FAULT" 0 "NO_I2C_FAULT" ;
VAL_ 1513 APP_sw135_fisheyeCamDeserFault 4 "I2C_UNKNOWN_IOCTL_ERR" 3 "I2C_DATA_NACK" 2 "I2C_SLAVE_ADDR_NACK" 1 "I2C_BUS_FAULT" 0 "NO_I2C_FAULT" ;
VAL_ 1513 APP_sw135_fisheyeCamSensorFault 4 "I2C_UNKNOWN_IOCTL_ERR" 3 "I2C_DATA_NACK" 2 "I2C_SLAVE_ADDR_NACK" 1 "I2C_BUS_FAULT" 0 "NO_I2C_FAULT" ;
VAL_ 1513 APP_sw135_fisheyeCamSerFault 4 "I2C_UNKNOWN_IOCTL_ERR" 3 "I2C_DATA_NACK" 2 "I2C_SLAVE_ADDR_NACK" 1 "I2C_BUS_FAULT" 0 "NO_I2C_FAULT" ;
VAL_ 1513 APP_sw136_lPillarCamDeserFault 4 "I2C_UNKNOWN_IOCTL_ERR" 3 "I2C_DATA_NACK" 2 "I2C_SLAVE_ADDR_NACK" 1 "I2C_BUS_FAULT" 0 "NO_I2C_FAULT" ;
VAL_ 1513 APP_sw136_lPillarCamSensorFault 4 "I2C_UNKNOWN_IOCTL_ERR" 3 "I2C_DATA_NACK" 2 "I2C_SLAVE_ADDR_NACK" 1 "I2C_BUS_FAULT" 0 "NO_I2C_FAULT" ;
VAL_ 1513 APP_sw136_lPillarCamSerFault 4 "I2C_UNKNOWN_IOCTL_ERR" 3 "I2C_DATA_NACK" 2 "I2C_SLAVE_ADDR_NACK" 1 "I2C_BUS_FAULT" 0 "NO_I2C_FAULT" ;
VAL_ 1513 APP_sw137_rPillarCamDeserFault 4 "I2C_UNKNOWN_IOCTL_ERR" 3 "I2C_DATA_NACK" 2 "I2C_SLAVE_ADDR_NACK" 1 "I2C_BUS_FAULT" 0 "NO_I2C_FAULT" ;
VAL_ 1513 APP_sw137_rPillarCamSensorFault 4 "I2C_UNKNOWN_IOCTL_ERR" 3 "I2C_DATA_NACK" 2 "I2C_SLAVE_ADDR_NACK" 1 "I2C_BUS_FAULT" 0 "NO_I2C_FAULT" ;
VAL_ 1513 APP_sw137_rPillarCamSerFault 4 "I2C_UNKNOWN_IOCTL_ERR" 3 "I2C_DATA_NACK" 2 "I2C_SLAVE_ADDR_NACK" 1 "I2C_BUS_FAULT" 0 "NO_I2C_FAULT" ;
VAL_ 1513 APP_sw138_lRepeatCamDeserFault 4 "I2C_UNKNOWN_IOCTL_ERR" 3 "I2C_DATA_NACK" 2 "I2C_SLAVE_ADDR_NACK" 1 "I2C_BUS_FAULT" 0 "NO_I2C_FAULT" ;
VAL_ 1513 APP_sw138_lRepeatCamSensorFault 4 "I2C_UNKNOWN_IOCTL_ERR" 3 "I2C_DATA_NACK" 2 "I2C_SLAVE_ADDR_NACK" 1 "I2C_BUS_FAULT" 0 "NO_I2C_FAULT" ;
VAL_ 1513 APP_sw138_lRepeatCamSerFault 4 "I2C_UNKNOWN_IOCTL_ERR" 3 "I2C_DATA_NACK" 2 "I2C_SLAVE_ADDR_NACK" 1 "I2C_BUS_FAULT" 0 "NO_I2C_FAULT" ;
VAL_ 1513 APP_sw139_rRepeatCamDeserFault 4 "I2C_UNKNOWN_IOCTL_ERR" 3 "I2C_DATA_NACK" 2 "I2C_SLAVE_ADDR_NACK" 1 "I2C_BUS_FAULT" 0 "NO_I2C_FAULT" ;
VAL_ 1513 APP_sw139_rRepeatCamSensorFault 4 "I2C_UNKNOWN_IOCTL_ERR" 3 "I2C_DATA_NACK" 2 "I2C_SLAVE_ADDR_NACK" 1 "I2C_BUS_FAULT" 0 "NO_I2C_FAULT" ;
VAL_ 1513 APP_sw139_rRepeatCamSerFault 4 "I2C_UNKNOWN_IOCTL_ERR" 3 "I2C_DATA_NACK" 2 "I2C_SLAVE_ADDR_NACK" 1 "I2C_BUS_FAULT" 0 "NO_I2C_FAULT" ;
VAL_ 1513 APP_sw140_backupCamCSIBridgeFlt 4 "I2C_UNKNOWN_IOCTL_ERR" 3 "I2C_DATA_NACK" 2 "I2C_SLAVE_ADDR_NACK" 1 "I2C_BUS_FAULT" 0 "NO_I2C_FAULT" ;
VAL_ 1513 APP_sw140_backupCamDeserFault 4 "I2C_UNKNOWN_IOCTL_ERR" 3 "I2C_DATA_NACK" 2 "I2C_SLAVE_ADDR_NACK" 1 "I2C_BUS_FAULT" 0 "NO_I2C_FAULT" ;
VAL_ 1513 APP_sw140_backupCamSensorFault 4 "I2C_UNKNOWN_IOCTL_ERR" 3 "I2C_DATA_NACK" 2 "I2C_SLAVE_ADDR_NACK" 1 "I2C_BUS_FAULT" 0 "NO_I2C_FAULT" ;
VAL_ 1513 APP_sw140_backupCamDeserLock 2 "UNKNOWN" 1 "LOST" 0 "LOCKED" ;
VAL_ 1513 APP_sw140_backupCamSerFault 4 "I2C_UNKNOWN_IOCTL_ERR" 3 "I2C_DATA_NACK" 2 "I2C_SLAVE_ADDR_NACK" 1 "I2C_BUS_FAULT" 0 "NO_I2C_FAULT" ;
VAL_ 1513 APP_sw142_problemCamPosition 10 "FASCIA" 9 "SELFIE" 8 "BACKUP" 7 "R_REPEATER" 6 "L_REPEATER" 5 "R_PILLAR" 4 "L_PILLAR" 3 "FISHEYE" 2 "NARROW" 1 "MAIN" 0 "INVALID" ;
VAL_ 1513 APP_sw145_problemCamPosition 10 "FASCIA" 9 "SELFIE" 8 "BACKUP" 7 "R_REPEATER" 6 "L_REPEATER" 5 "R_PILLAR" 4 "L_PILLAR" 3 "FISHEYE" 2 "NARROW" 1 "MAIN" 0 "INVALID" ;
VAL_ 1513 APP_sw147_selfieCamDeserFault 4 "I2C_UNKNOWN_IOCTL_ERR" 3 "I2C_DATA_NACK" 2 "I2C_SLAVE_ADDR_NACK" 1 "I2C_BUS_FAULT" 0 "NO_I2C_FAULT" ;
VAL_ 1513 APP_sw147_selfieCamSensorFault 4 "I2C_UNKNOWN_IOCTL_ERR" 3 "I2C_DATA_NACK" 2 "I2C_SLAVE_ADDR_NACK" 1 "I2C_BUS_FAULT" 0 "NO_I2C_FAULT" ;
VAL_ 1513 APP_sw147_selfieCamSerFault 4 "I2C_UNKNOWN_IOCTL_ERR" 3 "I2C_DATA_NACK" 2 "I2C_SLAVE_ADDR_NACK" 1 "I2C_BUS_FAULT" 0 "NO_I2C_FAULT" ;
VAL_ 1513 APP_sw162_detectedColorFilter 3 "UNKNOWN" 2 "RGGB" 1 "RCCB" 0 "RCCC" ;
VAL_ 1513 APP_sw162_expectedColorFilter 3 "UNKNOWN" 2 "RGGB" 1 "RCCB" 0 "RCCC" ;
VAL_ 1513 APP_sw162_detectedPosition 10 "FASCIA" 9 "SELFIE" 8 "BACKUP" 7 "R_REPEATER" 6 "L_REPEATER" 5 "R_PILLAR" 4 "L_PILLAR" 3 "FISHEYE" 2 "NARROW" 1 "MAIN" 0 "INVALID" ;
VAL_ 1513 APP_sw163_detectedColorFilter 3 "UNKNOWN" 2 "RGGB" 1 "RCCB" 0 "RCCC" ;
VAL_ 1513 APP_sw163_expectedColorFilter 3 "UNKNOWN" 2 "RGGB" 1 "RCCB" 0 "RCCC" ;
VAL_ 1513 APP_sw163_detectedPosition 10 "FASCIA" 9 "SELFIE" 8 "BACKUP" 7 "R_REPEATER" 6 "L_REPEATER" 5 "R_PILLAR" 4 "L_PILLAR" 3 "FISHEYE" 2 "NARROW" 1 "MAIN" 0 "INVALID" ;
VAL_ 1513 APP_sw164_detectedColorFilter 3 "UNKNOWN" 2 "RGGB" 1 "RCCB" 0 "RCCC" ;
VAL_ 1513 APP_sw164_expectedColorFilter 3 "UNKNOWN" 2 "RGGB" 1 "RCCB" 0 "RCCC" ;
VAL_ 1513 APP_sw164_detectedPosition 10 "FASCIA" 9 "SELFIE" 8 "BACKUP" 7 "R_REPEATER" 6 "L_REPEATER" 5 "R_PILLAR" 4 "L_PILLAR" 3 "FISHEYE" 2 "NARROW" 1 "MAIN" 0 "INVALID" ;
VAL_ 1513 APP_sw165_detectedColorFilter 3 "UNKNOWN" 2 "RGGB" 1 "RCCB" 0 "RCCC" ;
VAL_ 1513 APP_sw165_expectedColorFilter 3 "UNKNOWN" 2 "RGGB" 1 "RCCB" 0 "RCCC" ;
VAL_ 1513 APP_sw165_detectedPosition 10 "FASCIA" 9 "SELFIE" 8 "BACKUP" 7 "R_REPEATER" 6 "L_REPEATER" 5 "R_PILLAR" 4 "L_PILLAR" 3 "FISHEYE" 2 "NARROW" 1 "MAIN" 0 "INVALID" ;
VAL_ 1513 APP_sw166_detectedColorFilter 3 "UNKNOWN" 2 "RGGB" 1 "RCCB" 0 "RCCC" ;
VAL_ 1513 APP_sw166_expectedColorFilter 3 "UNKNOWN" 2 "RGGB" 1 "RCCB" 0 "RCCC" ;
VAL_ 1513 APP_sw166_detectedPosition 10 "FASCIA" 9 "SELFIE" 8 "BACKUP" 7 "R_REPEATER" 6 "L_REPEATER" 5 "R_PILLAR" 4 "L_PILLAR" 3 "FISHEYE" 2 "NARROW" 1 "MAIN" 0 "INVALID" ;
VAL_ 1513 APP_sw167_detectedColorFilter 3 "UNKNOWN" 2 "RGGB" 1 "RCCB" 0 "RCCC" ;
VAL_ 1513 APP_sw167_expectedColorFilter 3 "UNKNOWN" 2 "RGGB" 1 "RCCB" 0 "RCCC" ;
VAL_ 1513 APP_sw167_detectedPosition 10 "FASCIA" 9 "SELFIE" 8 "BACKUP" 7 "R_REPEATER" 6 "L_REPEATER" 5 "R_PILLAR" 4 "L_PILLAR" 3 "FISHEYE" 2 "NARROW" 1 "MAIN" 0 "INVALID" ;
VAL_ 1513 APP_sw168_detectedColorFilter 3 "UNKNOWN" 2 "RGGB" 1 "RCCB" 0 "RCCC" ;
VAL_ 1513 APP_sw168_expectedColorFilter 3 "UNKNOWN" 2 "RGGB" 1 "RCCB" 0 "RCCC" ;
VAL_ 1513 APP_sw168_detectedPosition 10 "FASCIA" 9 "SELFIE" 8 "BACKUP" 7 "R_REPEATER" 6 "L_REPEATER" 5 "R_PILLAR" 4 "L_PILLAR" 3 "FISHEYE" 2 "NARROW" 1 "MAIN" 0 "INVALID" ;
VAL_ 1513 APP_sw169_detectedColorFilter 3 "UNKNOWN" 2 "RGGB" 1 "RCCB" 0 "RCCC" ;
VAL_ 1513 APP_sw169_expectedColorFilter 3 "UNKNOWN" 2 "RGGB" 1 "RCCB" 0 "RCCC" ;
VAL_ 1513 APP_sw169_detectedPosition 10 "FASCIA" 9 "SELFIE" 8 "BACKUP" 7 "R_REPEATER" 6 "L_REPEATER" 5 "R_PILLAR" 4 "L_PILLAR" 3 "FISHEYE" 2 "NARROW" 1 "MAIN" 0 "INVALID" ;
VAL_ 1513 APP_sw170_detectedColorFilter 3 "UNKNOWN" 2 "RGGB" 1 "RCCB" 0 "RCCC" ;
VAL_ 1513 APP_sw170_expectedColorFilter 3 "UNKNOWN" 2 "RGGB" 1 "RCCB" 0 "RCCC" ;
VAL_ 1513 APP_sw170_detectedPosition 10 "FASCIA" 9 "SELFIE" 8 "BACKUP" 7 "R_REPEATER" 6 "L_REPEATER" 5 "R_PILLAR" 4 "L_PILLAR" 3 "FISHEYE" 2 "NARROW" 1 "MAIN" 0 "INVALID" ;
VAL_ 1513 APP_sw182_exitStatus 1 "FAULT" 0 "NOMINAL" ;
VAL_ 1513 APP_sw182_tempMonitorFailure 2 "MONITOR_OTHER_FAILURE" 1 "OUT_OF_SPEC" 0 "MONITOR_NO_FAILURE" ;
VAL_ 1513 APP_sw182_imagerHeartbeat 3 "SNA" 1 "STATIC" 0 "NOMINAL" ;
VAL_ 1513 APP_sw182_serializerCrcErrCount 255 "SNA" ;
VAL_ 1513 APP_sw182_currentTemperature 255 "SNA" ;
VAL_ 1513 APP_sw182_minTemperature 255 "SNA" ;
VAL_ 1513 APP_sw182_maxTemperature 255 "SNA" ;
VAL_ 1513 APP_sw183_exitStatus 1 "FAULT" 0 "NOMINAL" ;
VAL_ 1513 APP_sw183_tempMonitorFailure 2 "MONITOR_OTHER_FAILURE" 1 "OUT_OF_SPEC" 0 "MONITOR_NO_FAILURE" ;
VAL_ 1513 APP_sw183_imagerHeartbeat 3 "SNA" 1 "STATIC" 0 "NOMINAL" ;
VAL_ 1513 APP_sw183_serializerCrcErrCount 255 "SNA" ;
VAL_ 1513 APP_sw183_currentTemperature 255 "SNA" ;
VAL_ 1513 APP_sw183_minTemperature 255 "SNA" ;
VAL_ 1513 APP_sw183_maxTemperature 255 "SNA" ;
VAL_ 1513 APP_sw184_exitStatus 1 "FAULT" 0 "NOMINAL" ;
VAL_ 1513 APP_sw184_tempMonitorFailure 2 "MONITOR_OTHER_FAILURE" 1 "OUT_OF_SPEC" 0 "MONITOR_NO_FAILURE" ;
VAL_ 1513 APP_sw184_imagerHeartbeat 3 "SNA" 1 "STATIC" 0 "NOMINAL" ;
VAL_ 1513 APP_sw184_serializerCrcErrCount 255 "SNA" ;
VAL_ 1513 APP_sw184_currentTemperature 255 "SNA" ;
VAL_ 1513 APP_sw184_minTemperature 255 "SNA" ;
VAL_ 1513 APP_sw184_maxTemperature 255 "SNA" ;
VAL_ 1513 APP_sw185_exitStatus 1 "FAULT" 0 "NOMINAL" ;
VAL_ 1513 APP_sw185_tempMonitorFailure 2 "MONITOR_OTHER_FAILURE" 1 "OUT_OF_SPEC" 0 "MONITOR_NO_FAILURE" ;
VAL_ 1513 APP_sw185_imagerHeartbeat 3 "SNA" 1 "STATIC" 0 "NOMINAL" ;
VAL_ 1513 APP_sw185_serializerCrcErrCount 255 "SNA" ;
VAL_ 1513 APP_sw185_currentTemperature 255 "SNA" ;
VAL_ 1513 APP_sw185_minTemperature 255 "SNA" ;
VAL_ 1513 APP_sw185_maxTemperature 255 "SNA" ;
VAL_ 1513 APP_sw186_exitStatus 1 "FAULT" 0 "NOMINAL" ;
VAL_ 1513 APP_sw186_tempMonitorFailure 2 "MONITOR_OTHER_FAILURE" 1 "OUT_OF_SPEC" 0 "MONITOR_NO_FAILURE" ;
VAL_ 1513 APP_sw186_imagerHeartbeat 3 "SNA" 1 "STATIC" 0 "NOMINAL" ;
VAL_ 1513 APP_sw186_serializerCrcErrCount 255 "SNA" ;
VAL_ 1513 APP_sw186_currentTemperature 255 "SNA" ;
VAL_ 1513 APP_sw186_minTemperature 255 "SNA" ;
VAL_ 1513 APP_sw186_maxTemperature 255 "SNA" ;
VAL_ 1513 APP_sw187_exitStatus 1 "FAULT" 0 "NOMINAL" ;
VAL_ 1513 APP_sw187_tempMonitorFailure 2 "MONITOR_OTHER_FAILURE" 1 "OUT_OF_SPEC" 0 "MONITOR_NO_FAILURE" ;
VAL_ 1513 APP_sw187_imagerHeartbeat 3 "SNA" 1 "STATIC" 0 "NOMINAL" ;
VAL_ 1513 APP_sw187_serializerCrcErrCount 255 "SNA" ;
VAL_ 1513 APP_sw187_currentTemperature 255 "SNA" ;
VAL_ 1513 APP_sw187_minTemperature 255 "SNA" ;
VAL_ 1513 APP_sw187_maxTemperature 255 "SNA" ;
VAL_ 1513 APP_sw188_exitStatus 1 "FAULT" 0 "NOMINAL" ;
